VERSION ""

NS_ :

BS_:

BU_: AHLM ASBS CBC DIAGNOST DPDM DTCM ECM EHPS ESC ESL ESM ETM GPF HCP IC IRCM OCM ORC PTS RF_HUB SCCM SGW TBM TCM TPM

BO_ 1002 VehCfg3: 8 CBC
 SG_ VC_ADJ_PDL_PRSNT : 26|1@1+ (1,0) [0|0] ""  RF_HUB,SGW
 SG_ VC_AUTO_HL : 27|1@1+ (1,0) [0|0] ""  RF_HUB,SGW
 SG_ VC_AutoParkPrsnt : 61|1@1+ (1,0) [0|0] ""  RF_HUB,SGW
 SG_ VC_Base_TPM : 57|1@1+ (1,0) [0|0] ""  IC,ORC,RF_HUB,SGW,TPM
 SG_ VC_CMP_DISP : 48|1@1+ (1,0) [0|0] ""  IC,RF_HUB,SGW
 SG_ VC_CMS : 55|1@1+ (1,0) [0|0] ""  ESC,IRCM,ORC,RF_HUB,SGW
 SG_ VC_ChassisType : 32|7@1+ (1,0) [0|126] ""  DTCM,EHPS,ESC,RF_HUB,SGW
 SG_ VC_DSBL_CLK_DISP : 31|1@1+ (1,0) [0|0] ""  RF_HUB,SGW
 SG_ VC_DrAlrPrsnt : 28|1@1+ (1,0) [0|0] ""  RF_HUB,SGW
 SG_ VC_DualFuelSens : 29|1@1+ (1,0) [0|0] ""  IC,RF_HUB,SGW
 SG_ VC_ELV_Prsnt : 15|1@1+ (1,0) [0|0] ""  RF_HUB,SGW
 SG_ VC_ESCL_PRSNT : 50|1@1+ (1,0) [0|0] ""  RF_HUB,SGW
 SG_ VC_FCW : 56|1@1+ (1,0) [0|0] ""  ESC,IRCM,ORC,RF_HUB,SGW
 SG_ VC_FOBIKsafeENBL : 14|1@1+ (1,0) [0|0] ""  RF_HUB,SGW
 SG_ VC_FUEL_CAP : 16|8@1+ (1,36) [36|290] "liters"  IC,RF_HUB,SGW
 SG_ VC_HID_HL : 51|1@1+ (1,0) [0|0] ""  RF_HUB,SGW
 SG_ VC_HVAC_Config : 40|4@1+ (1,0) [0|0] ""  RF_HUB,SGW
 SG_ VC_IntEC_MIRR : 49|1@1+ (1,0) [0|0] ""  RF_HUB,SGW
 SG_ VC_KG_Prsnt : 63|1@1+ (1,0) [0|0] ""  IC,RF_HUB,SGW,TCM
 SG_ VC_Liftgate_Trunk : 53|2@1+ (1,0) [0|0] ""  RF_HUB,SGW
 SG_ VC_PDDL_PRSNT : 59|1@1+ (1,0) [0|0] ""  IC,RF_HUB,SGW,TCM
 SG_ VC_PE_Prsnt : 62|1@1+ (1,0) [0|0] ""  RF_HUB,SGW
 SG_ VC_POLICE : 2|1@1+ (1,0) [0|0] ""  RF_HUB,SGW
 SG_ VC_PWR_LFT_GT : 3|1@1+ (1,0) [0|0] ""  RF_HUB,SGW
 SG_ VC_PWR_LT_SLDR : 5|1@1+ (1,0) [0|0] ""  RF_HUB,SGW
 SG_ VC_PWR_RT_SLDR : 4|1@1+ (1,0) [0|0] ""  RF_HUB,SGW
 SG_ VC_Prem_TPM : 58|1@1+ (1,0) [0|0] ""  IC,ORC,RF_HUB,SGW,TPM
 SG_ VC_RKE_PRSNT : 6|1@1+ (1,0) [0|0] ""  RF_HUB,SGW
 SG_ VC_SPORT_PRSNT : 60|1@1+ (1,0) [0|0] ""  RF_HUB,SGW
 SG_ VC_SRT_PRSNT : 30|1@1+ (1,0) [0|0] ""  RF_HUB,SGW,TPM
 SG_ VC_SecLkPrsnt : 52|1@1+ (1,0) [0|0] ""  RF_HUB,SGW
 SG_ VC_SunShade_Present : 7|1@1+ (1,0) [0|0] ""  RF_HUB,SGW
 SG_ VC_TEMP_DISP : 39|1@1+ (1,0) [0|0] ""  IC,RF_HUB,SGW
 SG_ VC_TcaseTyp : 8|4@1+ (1,0) [0|0] ""  DTCM,ESC,IC,RF_HUB,SGW
 SG_ VC_VEH_BRAND : 44|4@1+ (1,0) [0|0] ""  PTS,RF_HUB,SGW
 SG_ VC_VehCfg3_Stat : 0|2@1+ (1,0) [0|0] ""  DTCM,ECM,EHPS,ESC,ESM,HCP,IC,IRCM,ORC,PTS,RF_HUB,SGW,TCM,TPM
 SG_ VC_WHL_BASE : 12|2@1+ (1,0) [0|0] ""  IC,IRCM,RF_HUB,SGW
 SG_ VC_WIN_EXPR_FEAT : 24|2@1+ (1,0) [0|0] ""  RF_HUB,SGW

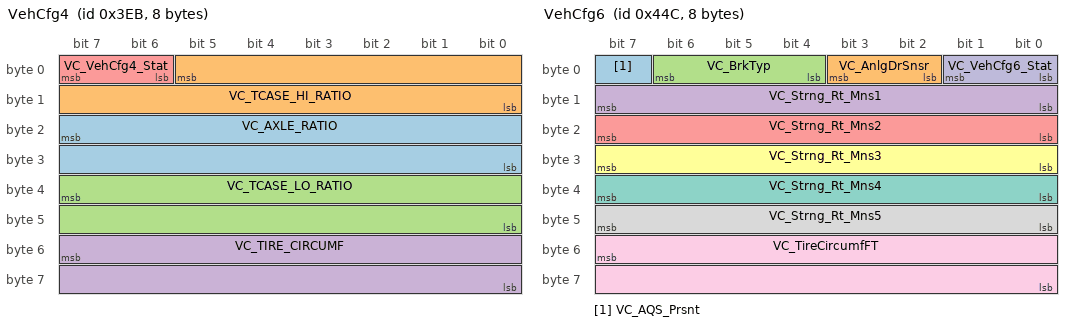
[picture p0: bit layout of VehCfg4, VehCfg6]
BO_ 1003 VehCfg4: 8 CBC
 SG_ VC_AXLE_RATIO : 23|16@0+ (0.001,0) [0|65.534] ""  DTCM,ECM,ESC,HCP,IRCM,RF_HUB,SGW,TCM
 SG_ VC_TCASE_HI_RATIO : 5|14@0+ (0.001,0) [0|16.382] ""  DTCM,ECM,ESC,HCP,RF_HUB,SGW,TCM
 SG_ VC_TCASE_LO_RATIO : 39|16@0+ (0.001,0) [0|65.534] ""  DTCM,ECM,ESC,HCP,RF_HUB,SGW,TCM
 SG_ VC_TIRE_CIRCUMF : 55|16@0+ (1,0) [0|65534] "mm"  DTCM,ECM,EHPS,ESC,HCP,IRCM,ORC,RF_HUB,SGW,TCM
 SG_ VC_VehCfg4_Stat : 6|2@1+ (1,0) [0|0] ""  DTCM,ECM,EHPS,ESC,HCP,IRCM,ORC,PTS,RF_HUB,SGW,TCM

BO_ 1098 VehCfg5: 8 CBC
 SG_ VC_AmbLtgPrsnt : 61|1@1+ (1,0) [0|0] ""  RF_HUB,SGW
 SG_ VC_AmbTempLct : 6|2@1+ (1,0) [0|0] ""  RF_HUB,SGW
 SG_ VC_ChildDisp_Prsnt : 59|1@1+ (1,0) [0|0] ""  RF_HUB,SGW
 SG_ VC_LUCI_PRSNT : 2|1@1+ (1,0) [0|0] ""  RF_HUB,SGW
 SG_ VC_NonReg_TPIS : 4|1@1+ (1,0) [0|0] ""  RF_HUB,SGW
 SG_ VC_OffRoadPg : 60|1@1+ (1,0) [0|0] ""  RF_HUB,SGW
 SG_ VC_PPPA_Prsnt : 62|1@1+ (1,0) [0|0] ""  ECM,ESC,RF_HUB,SGW
 SG_ VC_ParkStopPrsnt : 63|1@1+ (1,0) [0|0] ""  ESC,RF_HUB,SGW
 SG_ VC_RR_DuallyPrsnt : 3|1@1+ (1,0) [0|0] ""  RF_HUB,SGW
 SG_ VC_RearDoorLocks2DCM : 56|1@1+ (1,0) [0|0] ""  RF_HUB,SGW
 SG_ VC_SBR_Prsnt : 58|1@1+ (1,0) [0|0] ""  IC,RF_HUB,SGW
 SG_ VC_SpdLmt_PRSNT : 57|1@1+ (1,0) [0|0] ""  ECM,IC,IRCM,RF_HUB,SCCM,SGW
 SG_ VC_Strng_Rt_0 : 8|8@1+ (0.1,0) [0|25.4] ""  ESC,RF_HUB,SGW
 SG_ VC_Strng_Rt_pls1 : 16|8@1+ (0.1,0) [0|25.4] ""  ESC,RF_HUB,SGW
 SG_ VC_Strng_Rt_pls2 : 24|8@1+ (0.1,0) [0|25.4] ""  ESC,RF_HUB,SGW
 SG_ VC_Strng_Rt_pls3 : 32|8@1+ (0.1,0) [0|25.4] ""  ESC,RF_HUB,SGW
 SG_ VC_Strng_Rt_pls4 : 40|8@1+ (0.1,0) [0|25.4] ""  ESC,RF_HUB,SGW
 SG_ VC_Strng_Rt_pls5 : 48|8@1+ (0.1,0) [0|25.4] ""  ESC,RF_HUB,SGW
 SG_ VC_VehCfg5_Stat : 0|2@1+ (1,0) [0|0] ""  ECM,ESC,IC,ORC,PTS,RF_HUB,SCCM,SGW
 SG_ VC_WTS_Prsnt : 5|1@1+ (1,0) [0|0] ""  RF_HUB,SGW

BO_ 1100 VehCfg6: 8 CBC
 SG_ VC_AQS_Prsnt : 7|1@1+ (1,0) [0|0] ""  RF_HUB,SGW
 SG_ VC_AnlgDrSnsr : 2|2@1+ (1,0) [0|0] ""  ECM,RF_HUB,SGW
 SG_ VC_BrkTyp : 4|3@1+ (1,0) [0|0] ""  RF_HUB,SGW,TCM
 SG_ VC_Strng_Rt_Mns1 : 8|8@1+ (0.1,0) [0|25.4] ""  ESC,RF_HUB,SGW
 SG_ VC_Strng_Rt_Mns2 : 16|8@1+ (0.1,0) [0|25.4] ""  ESC,RF_HUB,SGW
 SG_ VC_Strng_Rt_Mns3 : 24|8@1+ (0.1,0) [0|25.4] ""  ESC,RF_HUB,SGW
 SG_ VC_Strng_Rt_Mns4 : 32|8@1+ (0.1,0) [0|25.4] ""  ESC,RF_HUB,SGW
 SG_ VC_Strng_Rt_Mns5 : 40|8@1+ (0.1,0) [0|25.4] ""  ESC,RF_HUB,SGW
 SG_ VC_TireCircumfFT : 55|16@0+ (1,0) [0|65534] "mm"  ESC,RF_HUB,SGW,TCM
 SG_ VC_VehCfg6_Stat : 0|2@1+ (1,0) [0|0] ""  ECM,ESC,HCP,IC,ORC,RF_HUB,SGW,TCM

BO_ 897 VehCfg7: 8 CBC
 SG_ VC_ABSM : 25|1@1+ (1,0) [0|0] ""  RF_HUB,SGW
 SG_ VC_ACC_Type : 19|2@1+ (1,0) [0|0] ""  ECM,ESC,IC,IRCM,ORC,RF_HUB,SCCM,SGW,TCM
 SG_ VC_ADR_PRSNT : 40|1@1+ (1,0) [0|0] ""  RF_HUB,SGW
 SG_ VC_AGSprsnt : 41|1@1+ (1,0) [0|0] ""  RF_HUB,SGW
 SG_ VC_AS_ERS : 14|2@1+ (1,0) [0|0] ""  RF_HUB,SGW,TCM
 SG_ VC_AxleLockerPrsnt : 26|2@1+ (1,0) [0|0] ""  DTCM,IC,RF_HUB,SGW
 SG_ VC_Brake_Type : 56|4@1+ (1,0) [0|0] ""  RF_HUB,SGW
 SG_ VC_DST_Present : 5|1@1+ (1,0) [0|0] ""  RF_HUB,SGW
 SG_ VC_DampingPrsnt : 22|1@1+ (1,0) [0|0] ""  RF_HUB,SGW
 SG_ VC_FullSpeedRange_FCW : 18|1@1+ (1,0) [0|0] ""  ESC,IC,IRCM,RF_HUB,SGW
 SG_ VC_GlareFree_Prsnt : 48|1@1+ (1,0) [0|0] ""  RF_HUB,SGW
 SG_ VC_Glovebox : 44|1@1+ (1,0) [0|0] ""  RF_HUB,SGW
 SG_ VC_HybridType : 36|3@1+ (1,0) [0|0] ""  AHLM,DTCM,ECM,EHPS,ESC,HCP,IC,IRCM,ORC,PTS,RF_HUB,SGW,TCM
 SG_ VC_LDW : 2|1@1+ (1,0) [0|0] ""  ORC,RF_HUB,SGW
 SG_ VC_MOC_Type : 45|2@1+ (1,0) [0|0] ""  RF_HUB,SGW
 SG_ VC_PBTyp : 29|3@1+ (1,0) [0|0] ""  IRCM,ORC,RF_HUB,SGW
 SG_ VC_PTCPrsnt : 43|1@1+ (1,0) [0|0] ""  ECM,RF_HUB,SGW
 SG_ VC_PdlsMdPrsnt : 4|1@1+ (1,0) [0|0] ""  RF_HUB,SGW,TCM
 SG_ VC_RedKey : 24|1@1+ (1,0) [0|0] ""  RF_HUB,SGW
 SG_ VC_STP_PRSNT : 6|1@1+ (1,0) [0|0] ""  RF_HUB,SGW
 SG_ VC_SUNR_Prsnt : 47|1@1+ (1,0) [0|0] ""  RF_HUB,SGW
 SG_ VC_SVC_Prsnt : 17|1@1+ (1,0) [0|0] ""  RF_HUB,SGW
 SG_ VC_SmartAlternator : 35|1@1+ (1,0) [0|0] ""  ECM,RF_HUB,SGW
 SG_ VC_SuspPrsnt : 21|1@1+ (1,0) [0|0] ""  RF_HUB,SGW
 SG_ VC_Suspension_Type : 60|4@1+ (1,0) [0|0] ""  RF_HUB,SGW
 SG_ VC_TPMS_Configuration : 32|3@1+ (1,0) [0|0] ""  IC,RF_HUB,SGW,TPM
 SG_ VC_TSBM_Prsnt : 39|1@1+ (1,0) [0|0] ""  RF_HUB,SGW
 SG_ VC_TeenKey : 16|1@1+ (1,0) [0|0] ""  RF_HUB,SGW
 SG_ VC_Temp_Display_Resolution : 42|1@1+ (1,0) [0|0] ""  RF_HUB,SGW
 SG_ VC_TransType : 8|6@1+ (1,0) [0|0] ""  DTCM,ESC,IC,RF_HUB,SGW
 SG_ VC_Trans_Equipped : 28|1@1+ (1,0) [0|0] ""  DTCM,ESC,IC,IRCM,ORC,PTS,RF_HUB,SGW,TPM
 SG_ VC_Trans_N_Hold_Prsnt : 23|1@1+ (1,0) [0|0] ""  RF_HUB,SGW
 SG_ VC_TrnsDrvMdPrsnt : 3|1@1+ (1,0) [0|0] ""  RF_HUB,SGW,TCM
 SG_ VC_VehCfg7_Stat : 0|2@1+ (1,0) [0|0] ""  DTCM,ECM,EHPS,ESC,HCP,IC,IRCM,ORC,PTS,RF_HUB,SCCM,SGW,TCM,TPM
 SG_ VC_eShifter_Prsnt : 7|1@1+ (1,0) [0|0] ""  RF_HUB,SGW

BO_ 906 VehCfg8: 8 CBC
 SG_ VC_ARC_PRSNT : 5|1@1+ (1,0) [0|0] ""  RF_HUB,SGW
 SG_ VC_AVAC_PRSNT : 21|1@1+ (1,0) [0|0] ""  RF_HUB,SGW
 SG_ VC_BEAM_SHAPING_PRSNT : 19|1@1+ (1,0) [0|0] ""  RF_HUB,SGW
 SG_ VC_CHILLER_PRSNT : 6|1@1+ (1,0) [0|0] ""  RF_HUB,SGW
 SG_ VC_DBL_PRSNT : 20|1@1+ (1,0) [0|0] ""  RF_HUB,SGW
 SG_ VC_FADPrsnt : 38|1@1+ (1,0) [0|0] ""  DTCM,RF_HUB,SGW
 SG_ VC_HighOctane_PRSNT : 7|1@1+ (1,0) [0|0] ""  RF_HUB,SGW
 SG_ VC_INDIA_SPEED_WARNING : 41|1@1+ (1,0) [0|0] ""  IC,RF_HUB,SGW
 SG_ VC_Increasing_Speed_Constant : 13|3@1+ (1,0) [0|0] ""  ECM,IC,IRCM,RF_HUB,SGW
 SG_ VC_LineLock_PRSNT : 4|1@1+ (1,0) [0|0] ""  RF_HUB,SGW
 SG_ VC_OFFRoadModePrsnt : 22|1@1+ (1,0) [0|0] ""  DTCM,ECM,ESC,IC,IRCM,RF_HUB,SGW,TCM
 SG_ VC_OFFroad_Camera : 23|1@1+ (1,0) [0|0] ""  RF_HUB,SGW
 SG_ VC_OvertakingBan : 16|1@1+ (1,0) [0|0] ""  RF_HUB,SGW
 SG_ VC_PEB_PRSNT : 62|1@1+ (1,0) [0|0] ""  RF_HUB,SGW
 SG_ VC_PPPAHardBtn : 24|1@1+ (1,0) [0|0] ""  RF_HUB,SGW
 SG_ VC_Power_Outlet_Type : 35|2@1+ (1,0) [0|0] ""  RF_HUB,SGW
 SG_ VC_SBL_FBL_CORNERING_PRSNT : 17|2@1+ (1,0) [0|0] ""  RF_HUB,SGW
 SG_ VC_STFA_Prsnt : 53|1@1+ (1,0) [0|0] ""  RF_HUB,SGW,TPM
 SG_ VC_Speedometer_Tolerance : 9|4@1+ (1,0) [0|0] ""  ECM,IC,IRCM,RF_HUB,SGW
 SG_ VC_Steering_Cfactor : 2|2@1+ (1,0) [0|0] ""  IRCM,RF_HUB,SGW
 SG_ VC_TACHO_TYPE : 54|2@1+ (1,0) [0|0] ""  ECM,IC,RF_HUB,SGW
 SG_ VC_TIPL_LOT : 39|1@1+ (1,0) [0|0] ""  RF_HUB
 SG_ VC_TLC_PRSNT : 37|1@1+ (1,0) [0|0] ""  RF_HUB,SGW
 SG_ VC_Trans_Brake_PRSNT : 8|1@1+ (1,0) [0|0] ""  RF_HUB,SGW
 SG_ VC_VP_Level : 43|4@1+ (1,0) [0|0] ""  HCP,RF_HUB,SGW
 SG_ VC_VehCfg8_Stat : 0|2@1+ (1,0) [0|0] ""  DTCM,ECM,IC,IRCM,RF_HUB,SGW,TCM
 SG_ VC_WHL_BASE_LENGTH : 56|4@1+ (1,0) [0|0] ""  IRCM,RF_HUB,SGW

BO_ 1004 VehCfgBu1: 8 RF_HUB
 SG_ VC_BU_AUTO_HB : 27|1@1+ (1,0) [0|0] ""  CBC,SGW
 SG_ VC_BU_BODY_STYLE : 28|4@1+ (1,0) [0|0] ""  CBC,SGW
 SG_ VC_BU_CHMCM_Prsnt : 61|1@1+ (1,0) [0|0] ""  CBC,SGW
 SG_ VC_BU_COUNTRY : 16|5@1+ (1,0) [0|0] ""  CBC,SGW
 SG_ VC_BU_EmodePrsnt : 26|1@1+ (1,0) [0|0] ""  CBC,SGW
 SG_ VC_BU_HDC_Prsnt : 62|1@1+ (1,0) [0|0] ""  CBC,SGW
 SG_ VC_BU_HdRstPrsnt : 56|1@1+ (1,0) [0|0] ""  CBC,SGW
 SG_ VC_BU_LHD_RHD : 21|2@1+ (1,0) [0|0] ""  CBC,SGW
 SG_ VC_BU_MAX_VEH_SPD : 32|8@1+ (2,0) [0|506] "kph"  CBC,SGW
 SG_ VC_BU_MODEL_YEAR : 2|6@1+ (1,2000) [2000|2062] "model-year"  CBC,SGW
 SG_ VC_BU_PP_Prsnt : 47|1@1+ (1,0) [0|0] ""  CBC,SGW
 SG_ VC_BU_PTS_Config : 58|2@1+ (1,0) [0|0] ""  CBC,SGW
 SG_ VC_BU_PTS_DispTyp : 44|3@1+ (1,0) [0|0] ""  CBC,SGW
 SG_ VC_BU_RVCM_Prsnt : 60|1@1+ (1,0) [0|0] ""  CBC,SGW
 SG_ VC_BU_RemStPrsnt : 23|1@1+ (1,0) [0|0] ""  CBC,SGW
 SG_ VC_BU_SCR_Prsnt : 57|1@1+ (1,0) [0|0] ""  CBC,SGW
 SG_ VC_BU_SSC_Prsnt : 63|1@1+ (1,0) [0|0] ""  CBC,SGW
 SG_ VC_BU_ShftrTyp : 40|4@1+ (1,0) [0|0] ""  CBC,SGW
 SG_ VC_BU_SpecialPKG : 48|8@1+ (1,0) [1|254] ""  CBC,SGW
 SG_ VC_BU_VEH_LINE : 8|8@1+ (1,0) [0|0] ""  CBC,SGW
 SG_ VC_BU_VehCfg1_Stat : 0|2@1+ (1,0) [0|0] ""  CBC,SGW
 SG_ VC_BU_XWD : 24|2@1+ (1,0) [0|0] ""  CBC,SGW

BO_ 1005 VehCfgBu2: 8 RF_HUB
 SG_ VC_BU_AC_Prsnt : 11|1@1+ (1,0) [0|0] ""  CBC,SGW
 SG_ VC_BU_CRUISE_PRSNT : 12|1@1+ (1,0) [0|0] ""  CBC,SGW
 SG_ VC_BU_DRVMD_Prsnt : 25|1@1+ (1,0) [0|0] ""  CBC,SGW
 SG_ VC_BU_ECO_Indicator : 24|1@1+ (1,0) [0|0] ""  CBC,SGW
 SG_ VC_BU_ESCDrvMd_Prsnt : 27|1@1+ (1,0) [0|0] ""  CBC,SGW
 SG_ VC_BU_EngPowerDrvMd_Prsnt : 28|1@1+ (1,0) [0|0] ""  CBC,SGW
 SG_ VC_BU_FG_PRSNT : 13|1@1+ (1,0) [0|0] ""  CBC,SGW
 SG_ VC_BU_FULL_SPARE : 14|1@1+ (1,0) [0|0] ""  CBC,SGW
 SG_ VC_BU_LgtLdPressFtTr : 56|8@1+ (1,0) [0|126] "psi"  CBC,SGW
 SG_ VC_BU_LgtLdPressRrTr : 48|8@1+ (1,0) [0|126] "psi"  CBC,SGW
 SG_ VC_BU_MaseratiMd : 6|2@1+ (1,0) [0|0] ""  CBC,SGW
 SG_ VC_BU_MaxLdPressFtTr : 40|8@1+ (1,0) [0|126] "psi"  CBC,SGW
 SG_ VC_BU_MaxLdPressRrTr : 32|8@1+ (1,0) [0|126] "psi"  CBC,SGW
 SG_ VC_BU_MemoryDRVMD_Prsnt : 26|1@1+ (1,0) [0|0] ""  CBC,SGW
 SG_ VC_BU_OffRoad : 15|1@1+ (1,0) [0|0] ""  CBC,SGW
 SG_ VC_BU_PADS_Prsnt : 8|1@1+ (1,0) [0|0] ""  CBC,SGW
 SG_ VC_BU_PwrIvtrTyp : 2|2@1+ (1,0) [0|0] ""  CBC,SGW
 SG_ VC_BU_RainSnsPrsnt : 9|1@1+ (1,0) [0|0] ""  CBC,SGW
 SG_ VC_BU_RunFlatTirePrsnt : 5|1@1+ (1,0) [0|0] ""  CBC,SGW
 SG_ VC_BU_SKIM_PRSNT : 10|1@1+ (1,0) [0|0] ""  CBC,SGW
 SG_ VC_BU_SecPrkPrsnt : 29|1@1+ (1,0) [0|0] ""  CBC,SGW
 SG_ VC_BU_ShftInd_Prsnt : 30|2@1+ (1,0) [0|0] ""  CBC,SGW
 SG_ VC_BU_SpecialPKG_IC : 16|8@1+ (1,0) [0|0] ""  CBC,SGW
 SG_ VC_BU_ThatchamPrsnt : 4|1@1+ (1,0) [0|0] ""  CBC,SGW
 SG_ VC_BU_VehCfg2_Stat : 0|2@1+ (1,0) [0|0] ""  CBC,SGW

BO_ 1006 VehCfgBu3: 8 RF_HUB
 SG_ VC_BU_ADJ_PDL_PRSNT : 26|1@1+ (1,0) [0|0] ""  CBC,SGW
 SG_ VC_BU_AUTO_HL : 27|1@1+ (1,0) [0|0] ""  CBC,SGW
 SG_ VC_BU_AutoParkPrsnt : 61|1@1+ (1,0) [0|0] ""  CBC,SGW
 SG_ VC_BU_Base_TPM : 57|1@1+ (1,0) [0|0] ""  CBC,SGW
 SG_ VC_BU_CMP_DISP : 48|1@1+ (1,0) [0|0] ""  CBC,SGW
 SG_ VC_BU_CMS : 55|1@1+ (1,0) [0|0] ""  CBC,SGW
 SG_ VC_BU_ChassisType : 32|7@1+ (1,0) [0|126] ""  CBC,SGW
 SG_ VC_BU_DSBL_CLK_DISP : 31|1@1+ (1,0) [0|0] ""  CBC,SGW
 SG_ VC_BU_DrAlrPrsnt : 28|1@1+ (1,0) [0|0] ""  CBC,SGW
 SG_ VC_BU_DualFuelSens : 29|1@1+ (1,0) [0|0] ""  CBC,SGW
 SG_ VC_BU_ELV_PRSNT : 15|1@1+ (1,0) [0|0] ""  CBC,SGW
 SG_ VC_BU_ESCL_Prsnt : 50|1@1+ (1,0) [0|0] ""  CBC,SGW
 SG_ VC_BU_FCW : 56|1@1+ (1,0) [0|0] ""  CBC,SGW
 SG_ VC_BU_FOBIKsafeENBL : 14|1@1+ (1,0) [0|0] ""  CBC,SGW
 SG_ VC_BU_FUEL_CAP : 16|8@1+ (1,36) [36|290] "liters"  CBC,SGW
 SG_ VC_BU_HID_HL : 51|1@1+ (1,0) [0|0] ""  CBC,SGW
 SG_ VC_BU_HVAC_Config : 40|4@1+ (1,0) [0|0] ""  CBC,SGW
 SG_ VC_BU_IntEC_MIRR : 49|1@1+ (1,0) [0|0] ""  CBC,SGW
 SG_ VC_BU_KG_Prsnt : 63|1@1+ (1,0) [0|0] ""  CBC,SGW
 SG_ VC_BU_Liftgate_Trunk : 53|2@1+ (1,0) [0|0] ""  CBC,SGW
 SG_ VC_BU_PDDL_PRSNT : 59|1@1+ (1,0) [0|0] ""  CBC,SGW
 SG_ VC_BU_PE_Prsnt : 62|1@1+ (1,0) [0|0] ""  CBC,SGW
 SG_ VC_BU_POLICE : 2|1@1+ (1,0) [0|0] ""  CBC,SGW
 SG_ VC_BU_PWR_LFT_GT : 3|1@1+ (1,0) [0|0] ""  CBC,SGW
 SG_ VC_BU_PWR_LT_SLDR : 5|1@1+ (1,0) [0|0] ""  CBC,SGW
 SG_ VC_BU_PWR_RT_SLDR : 4|1@1+ (1,0) [0|0] ""  CBC,SGW
 SG_ VC_BU_Prem_TPM : 58|1@1+ (1,0) [0|0] ""  CBC,SGW
 SG_ VC_BU_RKE_PRSNT : 6|1@1+ (1,0) [0|0] ""  CBC,SGW
 SG_ VC_BU_SPORT_PRSNT : 60|1@1+ (1,0) [0|0] ""  CBC,SGW
 SG_ VC_BU_SRT_PRSNT : 30|1@1+ (1,0) [0|0] ""  CBC,SGW
 SG_ VC_BU_SecLkPrsnt : 52|1@1+ (1,0) [0|0] ""  CBC,SGW
 SG_ VC_BU_SunShade_Present : 7|1@1+ (1,0) [0|0] ""  CBC,SGW
 SG_ VC_BU_TEMP_DISP : 39|1@1+ (1,0) [0|0] ""  CBC,SGW
 SG_ VC_BU_TcaseTyp : 8|4@1+ (1,0) [0|0] ""  CBC,SGW
 SG_ VC_BU_VEH_BRAND : 44|4@1+ (1,0) [0|0] ""  CBC,SGW
 SG_ VC_BU_VehCfg3_Stat : 0|2@1+ (1,0) [0|0] ""  CBC,SGW
 SG_ VC_BU_WHL_BASE : 12|2@1+ (1,0) [0|0] ""  CBC,SGW
 SG_ VC_BU_WIN_EXPR_FEAT : 24|2@1+ (1,0) [0|0] ""  CBC,SGW

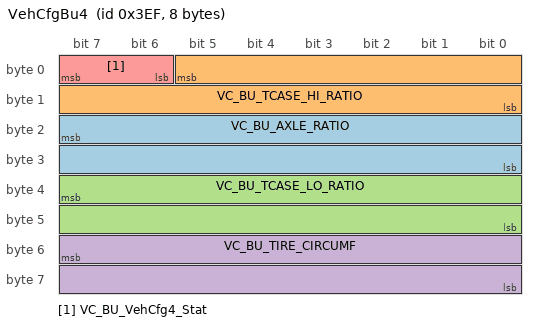
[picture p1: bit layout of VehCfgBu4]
BO_ 1007 VehCfgBu4: 8 RF_HUB
 SG_ VC_BU_AXLE_RATIO : 23|16@0+ (0.001,0) [0|65.534] ""  CBC,SGW
 SG_ VC_BU_TCASE_HI_RATIO : 5|14@0+ (0.001,0) [0|16.382] ""  CBC,SGW
 SG_ VC_BU_TCASE_LO_RATIO : 39|16@0+ (0.001,0) [0|65.534] ""  CBC,SGW
 SG_ VC_BU_TIRE_CIRCUMF : 55|16@0+ (1,0) [0|65534] "mm"  CBC,SGW
 SG_ VC_BU_VehCfg4_Stat : 6|2@1+ (1,0) [0|0] ""  CBC,SGW

CM_ SG_ 1002 VC_ADJ_PDL_PRSNT "Adjustable pedal system present (non-memory); present = [1]";
CM_ SG_ 1002 VC_AUTO_HL "Auto headlamp feature present; present = [1]";
CM_ SG_ 1002 VC_AutoParkPrsnt "Automatic transmission parking feature is present; present = [1]";
CM_ SG_ 1002 VC_Base_TPM "Base TPM system present; present = [1]";
CM_ SG_ 1002 VC_CMP_DISP "Display compass heading present; present = [1]";
CM_ SG_ 1002 VC_CMS "Collision Mitigation System present; present = [1]";
CM_ SG_ 1002 VC_ChassisType "Chassis type (including suspension, brakes, and tires)";
CM_ SG_ 1002 VC_DSBL_CLK_DISP "Disable display of radio clock; 1 = clock display disabled";
CM_ SG_ 1002 VC_DrAlrPrsnt "Door alert feature present; present = [1]";
CM_ SG_ 1002 VC_DualFuelSens "Vehicle equipped with two fuel sending units; present = [1]";
CM_ SG_ 1002 VC_ELV_Prsnt "ELV system present; enabled=[1], disabled=[0]";
CM_ SG_ 1002 VC_ESCL_PRSNT "ESCL system present; enabled=[1], disabled=[0]";
CM_ SG_ 1002 VC_FCW "Forward Collision Warning present; present = [1]";
CM_ SG_ 1002 VC_FOBIKsafeENBL "Feature FOBIK safe is enabled; present = [1]";
CM_ SG_ 1002 VC_FUEL_CAP "Fuel capacity";
CM_ SG_ 1002 VC_HID_HL "High intensity discharge head lamps; present = [1]";
CM_ SG_ 1002 VC_HVAC_Config "HVAC Configuration";
CM_ SG_ 1002 VC_IntEC_MIRR "Vehicle is equipped with an interior EC mirror; present = [1]";
CM_ SG_ 1002 VC_KG_Prsnt "Feature keyless go is present; present = [1]";
CM_ SG_ 1002 VC_Liftgate_Trunk "Liftgate or trunk";
CM_ SG_ 1002 VC_PDDL_PRSNT "Paddle shift feature is present; present = [1]";
CM_ SG_ 1002 VC_PE_Prsnt "Feature passive entry is present; present = [1]";
CM_ SG_ 1002 VC_POLICE "Police lighting feature; present = [1]";
CM_ SG_ 1002 VC_PWR_LFT_GT "Power lift gate present; present = [1]";
CM_ SG_ 1002 VC_PWR_LT_SLDR "Power left sliding door present; present = [1]";
CM_ SG_ 1002 VC_PWR_RT_SLDR "Power right sliding door present; present = [1]";
CM_ SG_ 1002 VC_Prem_TPM "Premium TPM system present; present = [1]";
CM_ SG_ 1002 VC_RKE_PRSNT "RKE system present; present = [1]";
CM_ SG_ 1002 VC_SPORT_PRSNT "Sport mode is present; present = [1]";
CM_ SG_ 1002 VC_SRT_PRSNT "Vehicle is an SRT; present = [1]";
CM_ SG_ 1002 VC_SecLkPrsnt "Secondary Lock Present; [1] = True";
CM_ SG_ 1002 VC_SunShade_Present "Vehicle equipped w/SunShade (1=present)";
CM_ SG_ 1002 VC_TEMP_DISP "Display outside temperature present; present = [1]";
CM_ SG_ 1002 VC_TcaseTyp "Tcase type";
CM_ SG_ 1002 VC_VEH_BRAND "Vehicle brand type";
CM_ SG_ 1002 VC_VehCfg3_Stat "Configuration messages status 3";
CM_ SG_ 1002 VC_WHL_BASE "Wheel base";
CM_ SG_ 1002 VC_WIN_EXPR_FEAT "Window express feature configuration";
CM_ SG_ 1003 VC_AXLE_RATIO "Axle ratio";
CM_ SG_ 1003 VC_TCASE_HI_RATIO "Transfer case high ratio";
CM_ SG_ 1003 VC_TCASE_LO_RATIO "Transfer case low range reduction ratio";
CM_ SG_ 1003 VC_TIRE_CIRCUMF "Dynamic tire circumference (all or rear)";
CM_ SG_ 1003 VC_VehCfg4_Stat "Configuration messages status 4";
CM_ SG_ 1098 VC_AmbLtgPrsnt "Ambient lighting feature is present; True = [1]";
CM_ SG_ 1098 VC_AmbTempLct "Ambient temperature sensor location";
CM_ SG_ 1098 VC_ChildDisp_Prsnt "Child display feature is present; True = 1";
CM_ SG_ 1098 VC_LUCI_PRSNT "Luci feature present; present = [1]";
CM_ SG_ 1098 VC_NonReg_TPIS "Non-regulated tire pressure indicator system; True = 1";
CM_ SG_ 1098 VC_OffRoadPg "Off road pages present; True = [1]";
CM_ SG_ 1098 VC_PPPA_Prsnt "Semi automatic parking system present; present = [1]";
CM_ SG_ 1098 VC_ParkStopPrsnt "Park with stop is present; True = 1";
CM_ SG_ 1098 VC_RR_DuallyPrsnt "Vehicle is equipped with rear duals; present = [1]";
CM_ SG_ 1098 VC_RearDoorLocks2DCM "Rear door lock switch present; present = [1]";
CM_ SG_ 1098 VC_SBR_Prsnt "Seat belt reminder module is present; True = 1";
CM_ SG_ 1098 VC_SpdLmt_PRSNT "Speed limiter is present; present = [1]";
CM_ SG_ 1098 VC_Strng_Rt_0 "Steering Ratio at zero";
CM_ SG_ 1098 VC_Strng_Rt_pls1 "Steering Ratio at positve angle 1";
CM_ SG_ 1098 VC_Strng_Rt_pls2 "Steering Ratio at positve angle 2";
CM_ SG_ 1098 VC_Strng_Rt_pls3 "Steering Ratio at positve angle 3";
CM_ SG_ 1098 VC_Strng_Rt_pls4 "Steering Ratio at positve angle 4";
CM_ SG_ 1098 VC_Strng_Rt_pls5 "Steering Ratio at positve angle 5";
CM_ SG_ 1098 VC_VehCfg5_Stat "Configuration messages status 5";
CM_ SG_ 1098 VC_WTS_Prsnt "Wait to start feature is present; present = [1]";
CM_ SG_ 1100 VC_AQS_Prsnt "Air quality sensor present; present = [1]";
CM_ SG_ 1100 VC_AnlgDrSnsr "Analog door sensor configuration";
CM_ SG_ 1100 VC_BrkTyp "Brake type configuration (M156/7)";
CM_ SG_ 1100 VC_Strng_Rt_Mns1 "Steering Ratio at negative angle 1";
CM_ SG_ 1100 VC_Strng_Rt_Mns2 "Steering Ratio at negative angle 2";
CM_ SG_ 1100 VC_Strng_Rt_Mns3 "Steering Ratio at negative angle 3";
CM_ SG_ 1100 VC_Strng_Rt_Mns4 "Steering Ratio at negative angle 4";
CM_ SG_ 1100 VC_Strng_Rt_Mns5 "Steering Ratio at negative angle 5";
CM_ SG_ 1100 VC_TireCircumfFT "Dynamic tire circumference - front only";
CM_ SG_ 1100 VC_VehCfg6_Stat "Configuration messages status 6";
CM_ SG_ 897 VC_ABSM "Active Blind Spot present; present = [1]";
CM_ SG_ 897 VC_ACC_Type "Type of adaptive cruise control (ACC) system present";
CM_ SG_ 897 VC_ADR_PRSNT "ADR feature present; True = [1]";
CM_ SG_ 897 VC_AGSprsnt "AGS Present/Absent;  Present = 1";
CM_ SG_ 897 VC_AS_ERS "Shift feature autostick / electronic range select status";
CM_ SG_ 897 VC_AxleLockerPrsnt "Axle locker configuration";
CM_ SG_ 897 VC_Brake_Type "Brake type";
CM_ SG_ 897 VC_DST_Present "Dynamic steering torque present; True = [1]";
CM_ SG_ 897 VC_DampingPrsnt "NetCfg_ASCM contains active damping; present = [1]";
CM_ SG_ 897 VC_FullSpeedRange_FCW "Full speed range forward collision warning plus system present; Present = 1";
CM_ SG_ 897 VC_GlareFree_Prsnt "Glare Free Present";
CM_ SG_ 897 VC_Glovebox "Glovebox control; Present = 1";
CM_ SG_ 897 VC_HybridType "Identify the kind of hybrid vehicle";
CM_ SG_ 897 VC_LDW "Lane Departure Warning present; present = [1]";
CM_ SG_ 897 VC_MOC_Type "Motor on caliper type";
CM_ SG_ 897 VC_PBTyp "Park brake type";
CM_ SG_ 897 VC_PTCPrsnt "PTC Present/Absent;  Present = 1";
CM_ SG_ 897 VC_PdlsMdPrsnt "Paddles lock-out feature; present = [1]";
CM_ SG_ 897 VC_RedKey "RedKey feature is present; Present = [1]";
CM_ SG_ 897 VC_STP_PRSNT "Super trac pack present; True = [1]";
CM_ SG_ 897 VC_SUNR_Prsnt "Sunroof is present; True = 1";
CM_ SG_ 897 VC_SVC_Prsnt "Surround view camera; present = [1]";
CM_ SG_ 897 VC_SmartAlternator "Smart alternator is present; True = [1]";
CM_ SG_ 897 VC_SuspPrsnt "NetCfg_ASCM contains suspension; present = [1]";
CM_ SG_ 897 VC_Suspension_Type "Suspension type";
CM_ SG_ 897 VC_TPMS_Configuration "TPMS configuration";
CM_ SG_ 897 VC_TSBM_Prsnt "TSBM LIN slave is present; True = [1]";
CM_ SG_ 897 VC_TeenKey "TeenKey feature is present; Present = [1]";
CM_ SG_ 897 VC_Temp_Display_Resolution "Toggle between 0.5degC and 1degC temperature display";
CM_ SG_ 897 VC_TransType "Automatic transmission type";
CM_ SG_ 897 VC_Trans_Equipped "Transmission equipped: 0 = Automatic & 1 = Manual";
CM_ SG_ 897 VC_Trans_N_Hold_Prsnt "Transmission neutral hold feature; present = [1]";
CM_ SG_ 897 VC_TrnsDrvMdPrsnt "Transmission drive mode feature; present = [1]";
CM_ SG_ 897 VC_VehCfg7_Stat "Configuration messages status 7";
CM_ SG_ 897 VC_eShifter_Prsnt "e-shifter present; present = [1]";
CM_ SG_ 906 VC_ARC_PRSNT "After Run Cooling (Race Cool Down) feature present; True = [1]";
CM_ SG_ 906 VC_AVAC_PRSNT "Present = 1";
CM_ SG_ 906 VC_BEAM_SHAPING_PRSNT "Present = 1";
CM_ SG_ 906 VC_CHILLER_PRSNT "Chiller present; True = [1]";
CM_ SG_ 906 VC_DBL_PRSNT "Present = 1";
CM_ SG_ 906 VC_FADPrsnt "Present = 1";
CM_ SG_ 906 VC_HighOctane_PRSNT "High Octane feature present; True = [1]";
CM_ SG_ 906 VC_INDIA_SPEED_WARNING "INDIA EQUIPPED SPEED WARNING Feature";
CM_ SG_ 906 VC_Increasing_Speed_Constant "Increasing Speed Constant (Offset for Speedometer Biasing)";
CM_ SG_ 906 VC_LineLock_PRSNT "Line Lock feature present; True = [1]";
CM_ SG_ 906 VC_OFFRoadModePrsnt "OFF ROAD MODE Present, Present = 1";
CM_ SG_ 906 VC_OFFroad_Camera "OFF Road Camera Present, Present = 1";
CM_ SG_ 906 VC_OvertakingBan "Overtaking Ban present; present = [1]";
CM_ SG_ 906 VC_PEB_PRSNT "Vehicle config to learn the presence of PEB";
CM_ SG_ 906 VC_PPPAHardBtn "PPPA Hard button present, Present = 1";
CM_ SG_ 906 VC_Power_Outlet_Type "Request to IC to determine the cargo power outlet indication display version";
CM_ SG_ 906 VC_SBL_FBL_CORNERING_PRSNT "Configuration messages status 8";
CM_ SG_ 906 VC_STFA_Prsnt "Selectable Tire Fill Alert Present; True = [1]";
CM_ SG_ 906 VC_Speedometer_Tolerance "Speedometer Tolerance Percentage (Gain for Speedometer Biasing)";
CM_ SG_ 906 VC_Steering_Cfactor "Steering Cfactor feature";
CM_ SG_ 906 VC_TACHO_TYPE "CBC VC Config of Tachometer Type";
CM_ SG_ 906 VC_TIPL_LOT "Traffic in Parallel and Lock on Target (1=present)";
CM_ SG_ 906 VC_TLC_PRSNT "Trailer Light Check Feature Present;  present = [1]";
CM_ SG_ 906 VC_Trans_Brake_PRSNT "Transmission Brake feature present; True = [1]";
CM_ SG_ 906 VC_VP_Level "Radio Type Identifier";
CM_ SG_ 906 VC_VehCfg8_Stat "Configuration messages status 8";
CM_ SG_ 906 VC_WHL_BASE_LENGTH "Wheel Base Length";
CM_ SG_ 1004 VC_BU_AUTO_HB "Backup for Auto Highbeam feature present; present = [1]";
CM_ SG_ 1004 VC_BU_BODY_STYLE "Backup for Body style";
CM_ SG_ 1004 VC_BU_CHMCM_Prsnt "Backup for CHMSL camera (1=present)";
CM_ SG_ 1004 VC_BU_COUNTRY "Backup for Country Code";
CM_ SG_ 1004 VC_BU_EmodePrsnt "Backup for E-Mode feature present; True = [1]";
CM_ SG_ 1004 VC_BU_HDC_Prsnt "Backup for Hill descent feature is present; present = [1]";
CM_ SG_ 1004 VC_BU_HdRstPrsnt "Backup for headrest present; present = [1]";
CM_ SG_ 1004 VC_BU_LHD_RHD "Backup for Left/right hand drive";
CM_ SG_ 1004 VC_BU_MAX_VEH_SPD "Backup for Maximum vehicle speed";
CM_ SG_ 1004 VC_BU_MODEL_YEAR "Backup for Model year";
CM_ SG_ 1004 VC_BU_PP_Prsnt "Backup for Performance Pages Present (1=present)";
CM_ SG_ 1004 VC_BU_PTS_Config "Backup for Parktronics system configuration";
CM_ SG_ 1004 VC_BU_PTS_DispTyp "PTS display type and location";
CM_ SG_ 1004 VC_BU_RVCM_Prsnt "Backup for rear view camera (1=present)";
CM_ SG_ 1004 VC_BU_RemStPrsnt "Backup for Remote start present; present = [1]";
CM_ SG_ 1004 VC_BU_SCR_Prsnt "Backup for Urea/SCR system present; present = [1]";
CM_ SG_ 1004 VC_BU_SSC_Prsnt "Backup for Select speed control feature is present; present = [1]";
CM_ SG_ 1004 VC_BU_ShftrTyp "Shifter type";
CM_ SG_ 1004 VC_BU_SpecialPKG "Special sales code package";
CM_ SG_ 1004 VC_BU_VEH_LINE "Backup for Vehicle line";
CM_ SG_ 1004 VC_BU_VehCfg1_Stat "Backup for Configuration messages status 1";
CM_ SG_ 1004 VC_BU_XWD "Backup for Drive configuration";
CM_ SG_ 1005 VC_BU_AC_Prsnt "Backup for Vehicle is equipped with air conditioning; present = [1]";
CM_ SG_ 1005 VC_BU_CRUISE_PRSNT "Backup for Cruise feature is present; present = [1]";
CM_ SG_ 1005 VC_BU_DRVMD_Prsnt "Backup for drive mode feature configuration (1 = Present)";
CM_ SG_ 1005 VC_BU_ECO_Indicator "Backup for ECO Indicator present on vehicle; True = [1]";
CM_ SG_ 1005 VC_BU_ESCDrvMd_Prsnt "Backup for ESC drive mode sub-feature configuration (1 = Present)";
CM_ SG_ 1005 VC_BU_EngPowerDrvMd_Prsnt "Backup for ECM drive mode sub-feature configuration (1 = Present)";
CM_ SG_ 1005 VC_BU_FG_PRSNT "Backup for Flipper glass present; present = [1]";
CM_ SG_ 1005 VC_BU_FULL_SPARE "Backup for Full size spare; present = [1]";
CM_ SG_ 1005 VC_BU_LgtLdPressFtTr "Backup for Light Load Inflation Pressure Front Tire";
CM_ SG_ 1005 VC_BU_LgtLdPressRrTr "Backup for Light Load Inflation Pressure Rear Tire";
CM_ SG_ 1005 VC_BU_MaseratiMd "Backup for Maserati vehicle mode";
CM_ SG_ 1005 VC_BU_MaxLdPressFtTr "Backup for Max Load Inflation Pressure Front Tire";
CM_ SG_ 1005 VC_BU_MaxLdPressRrTr "Backup for Max Load Inflation Pressure Rear Tire";
CM_ SG_ 1005 VC_BU_MemoryDRVMD_Prsnt "Backup for memory drive mode sub-feature configuration (1 = Present)";
CM_ SG_ 1005 VC_BU_OffRoad "Backup for Off road capable; present = [1]";
CM_ SG_ 1005 VC_BU_PADS_Prsnt "Backup for Pass. airbag disable switch present; present = [1]";
CM_ SG_ 1005 VC_BU_PwrIvtrTyp "Backup for power inverter type";
CM_ SG_ 1005 VC_BU_RainSnsPrsnt "Backup for Rain sensor present; present = [1]";
CM_ SG_ 1005 VC_BU_RunFlatTirePrsnt "Backup for run flat tires present; present = [1]";
CM_ SG_ 1005 VC_BU_SKIM_PRSNT "Backup for SKIM system present; present = [1]";
CM_ SG_ 1005 VC_BU_SecPrkPrsnt "Backup for secure park feature present; present = [1]";
CM_ SG_ 1005 VC_BU_ShftInd_Prsnt "Backup for configuration for performance & gear shift indication";
CM_ SG_ 1005 VC_BU_SpecialPKG_IC "Special sales code package";
CM_ SG_ 1005 VC_BU_ThatchamPrsnt "Backup for thatcham present; present = [1]";
CM_ SG_ 1005 VC_BU_VehCfg2_Stat "Backup for Configuration messages status 2";
CM_ SG_ 1006 VC_BU_ADJ_PDL_PRSNT "Backup for Adjustable pedal system present (non-memory); present = [1]";
CM_ SG_ 1006 VC_BU_AUTO_HL "Backup for Auto headlamp feature present; present = [1]";
CM_ SG_ 1006 VC_BU_AutoParkPrsnt "Backup for automatic transmission parking feature is present; present = [1]";
CM_ SG_ 1006 VC_BU_Base_TPM "Backup for Base TPM system present; present = [1]";
CM_ SG_ 1006 VC_BU_CMP_DISP "Backup for display compass heading present; present = [1]";
CM_ SG_ 1006 VC_BU_CMS "Backup for Collision Mitigation System present; present = [1]";
CM_ SG_ 1006 VC_BU_ChassisType "Backup for chassis type (including suspension, brakes, and tires)";
CM_ SG_ 1006 VC_BU_DSBL_CLK_DISP "Backup of Disable display of radio clock; 1 = clock display disabled";
CM_ SG_ 1006 VC_BU_DrAlrPrsnt "Backup for Door alert feature present; present = [1]";
CM_ SG_ 1006 VC_BU_DualFuelSens "Backup for Vehicle equipped with two fuel sending units; present = [1]";
CM_ SG_ 1006 VC_BU_ELV_PRSNT "Backup for ELV system present; enabled=[1], disabled=[0]";
CM_ SG_ 1006 VC_BU_ESCL_Prsnt "Backup for ESCL system present; enabled=[1], disabled=[0]";
CM_ SG_ 1006 VC_BU_FCW "Backup for Forward Collision Warning present; present = [1]";
CM_ SG_ 1006 VC_BU_FOBIKsafeENBL "Backup for FOBIK safe feature; present = [1]";
CM_ SG_ 1006 VC_BU_FUEL_CAP "Backup for Fuel capacity";
CM_ SG_ 1006 VC_BU_HID_HL "Backup for High intensity discharge head lamps; present = [1]";
CM_ SG_ 1006 VC_BU_HVAC_Config "Backup for HVAC Configuration";
CM_ SG_ 1006 VC_BU_IntEC_MIRR "Backup for vehicle is equipped with an interior EC mirror; present = [1]";
CM_ SG_ 1006 VC_BU_KG_Prsnt "Backup for keyless go is present; present = [1]";
CM_ SG_ 1006 VC_BU_Liftgate_Trunk "Backup for Liftgate or trunk";
CM_ SG_ 1006 VC_BU_PDDL_PRSNT "backup for Paddle shift feature is present; present = [1]";
CM_ SG_ 1006 VC_BU_PE_Prsnt "Backup for passive entry is present; present = [1]";
CM_ SG_ 1006 VC_BU_POLICE "Backup for Police lighting feature; present = [1]";
CM_ SG_ 1006 VC_BU_PWR_LFT_GT "Backup for Power lift gate present; present = [1]";
CM_ SG_ 1006 VC_BU_PWR_LT_SLDR "Backup for Power left sliding door present; present = [1]";
CM_ SG_ 1006 VC_BU_PWR_RT_SLDR "Backup for Power right sliding door present; present = [1]";
CM_ SG_ 1006 VC_BU_Prem_TPM "Backup for Premium TPM system present; present = [1]";
CM_ SG_ 1006 VC_BU_RKE_PRSNT "Backup for RKE system present; present = [1]";
CM_ SG_ 1006 VC_BU_SPORT_PRSNT "Backup for Sport mode is present; present = [1]";
CM_ SG_ 1006 VC_BU_SRT_PRSNT "Backup for Vehicle is an SRT; present = [1]";
CM_ SG_ 1006 VC_BU_SecLkPrsnt "Backup for Secondary Lock Present; [1] = True";
CM_ SG_ 1006 VC_BU_SunShade_Present "Backup for Vehicle equipped w/SunShade (1=present)";
CM_ SG_ 1006 VC_BU_TEMP_DISP "Backup for display outside temperature present; present = [1]";
CM_ SG_ 1006 VC_BU_TcaseTyp "Backup for Tcase type";
CM_ SG_ 1006 VC_BU_VEH_BRAND "Backup for Vehicle brand type";
CM_ SG_ 1006 VC_BU_VehCfg3_Stat "Backup for Configuration messages status 3";
CM_ SG_ 1006 VC_BU_WHL_BASE "Backup for Wheel base";
CM_ SG_ 1006 VC_BU_WIN_EXPR_FEAT "Backup for Window express feature configuration";
CM_ SG_ 1007 VC_BU_AXLE_RATIO "Backup for Axle ratio";
CM_ SG_ 1007 VC_BU_TCASE_HI_RATIO "Backup for Transfer case high ratio";
CM_ SG_ 1007 VC_BU_TCASE_LO_RATIO "Backup for Transfer case low range reduction ratio";
CM_ SG_ 1007 VC_BU_TIRE_CIRCUMF "Backup for Dynamic tire circumference (all or rear)";
CM_ SG_ 1007 VC_BU_VehCfg4_Stat "Backup for Configuration messages status 4";
BA_DEF_ BO_  "App-Botschaft" ENUM  "nein","ja";
BA_DEF_ BO_  "CanMsgMinLen" INT 0 8;
BA_DEF_ BO_  "DiagRequest" ENUM  "nein","ja";
BA_DEF_ BO_  "DiagResponse" ENUM  "nein","ja";
BA_DEF_ BO_  "DiagState" ENUM  "nein","ja";
BA_DEF_ BO_  "GenMsgCycleTime" INT 0 65535;
BA_DEF_ BO_  "GenMsgCycleTimeActive" INT 0 65535;
BA_DEF_ BO_  "GenMsgDelayTime" INT 0 65535;
BA_DEF_ BO_  "GenMsgNrOfRepetitions" INT 0 65535;
BA_DEF_ BO_  "GenMsgSendType" ENUM  "cyclicX","spontanX","cyclicIfActiveX","spontanWithDelay","cyclicAndSpontanX","cyclicAndSpontanWithDelay","spontanWithRepitition","cyclicIfActiveAndSpontanWD","cyclicIfActiveFast","cyclicWithRepeatOnDemand","none";
BA_DEF_ BO_  "GenMsgStartDelayTime" INT 0 65535;
BA_DEF_ BO_  "GenMsgStartValue" STRING ;
BA_DEF_ BO_  "NWM-Botschaft" ENUM  "nein","ja";
BA_DEF_ BO_  "TpTxIndex" INT 0 99;
BA_DEF_ SG_  "FlexKomComment" STRING ;
BA_DEF_ SG_  "FlexKomIsMotorola" ENUM  "nein","ja";
BA_DEF_ SG_  "FlexKomSID" INT 0 2147483647;
BA_DEF_ SG_  "FlexKomSigLaenge" INT 0 64;
BA_DEF_ SG_  "FlexKomSigName" STRING ;
BA_DEF_ SG_  "FlexKomSigStartPos" INT 0 63;
BA_DEF_ SG_  "FlexKomSigStartValue" STRING ;
BA_DEF_ SG_  "GenSigCycleTime" INT 0 65535;
BA_DEF_ SG_  "GenSigCycleTimeActive" INT 0 65535;
BA_DEF_ SG_  "GenSigSendType" ENUM  "cyclicX","spontanX","cyclicIfActiveX","spontanWithDelay","cyclicAndSpontanX","cyclicAndSpontanWithDelay","spontanWithRepitition","cyclicIfActiveAndSpontanWD","cyclicIfActiveFast","cyclicWithRepeatOnDemand","none";
BA_DEF_ SG_  "GenSigSNA" STRING ;
BA_DEF_ SG_  "GenSigStartValue" HEX 0 2147483648;
BA_DEF_ SG_  "GenSigTimeout_AHLM" INT 0 65535;
BA_DEF_ SG_  "GenSigTimeout_ASBS" INT 0 65535;
BA_DEF_ SG_  "GenSigTimeout_CBC" INT 0 65535;
BA_DEF_ SG_  "GenSigTimeout_DPDM" INT 0 65535;
BA_DEF_ SG_  "GenSigTimeout_DTCM" INT 0 65535;
BA_DEF_ SG_  "GenSigTimeout_EHPS" INT 0 65535;
BA_DEF_ SG_  "GenSigTimeout_ESC" INT 0 65535;
BA_DEF_ SG_  "GenSigTimeout_ESL" INT 0 65535;
BA_DEF_ SG_  "GenSigTimeout_ESM" INT 0 65535;
BA_DEF_ SG_  "GenSigTimeout_ETM" INT 0 65535;
BA_DEF_ SG_  "GenSigTimeout_IC" INT 0 65535;
BA_DEF_ SG_  "GenSigTimeout_OCM" INT 0 65535;
BA_DEF_ SG_  "GenSigTimeout_ORC" INT 0 65535;
BA_DEF_ SG_  "GenSigTimeout_PTS" INT 0 65535;
BA_DEF_ SG_  "GenSigTimeout_RF_HUB" INT 0 65535;
BA_DEF_ SG_  "GenSigTimeout_SCCM" INT 0 65535;
BA_DEF_ SG_  "GenSigTimeout_TBM" INT 0 65535;
BA_DEF_ SG_  "GenSigTimeout_TCM" INT 0 65535;
BA_DEF_ SG_  "GenSigTimeout_TPM" INT 0 65535;
BA_DEF_ SG_  "RID" STRING ;
BA_DEF_ SG_  "SystemSignalLongSymbol" STRING ;
BA_DEF_DEF_  "App-Botschaft" "nein";
BA_DEF_DEF_  "CanMsgMinLen" 0;
BA_DEF_DEF_  "DiagRequest" "nein";
BA_DEF_DEF_  "DiagResponse" "nein";
BA_DEF_DEF_  "DiagState" "nein";
BA_DEF_DEF_  "GenMsgCycleTime" 0;
BA_DEF_DEF_  "GenMsgCycleTimeActive" 0;
BA_DEF_DEF_  "GenMsgDelayTime" 0;
BA_DEF_DEF_  "GenMsgNrOfRepetitions" 0;
BA_DEF_DEF_  "GenMsgSendType" "cyclicX";
BA_DEF_DEF_  "GenMsgStartDelayTime" 0;
BA_DEF_DEF_  "GenMsgStartValue" "";
BA_DEF_DEF_  "NWM-Botschaft" "nein";
BA_DEF_DEF_  "TpTxIndex" 0;
BA_DEF_DEF_  "FlexKomComment" "";
BA_DEF_DEF_  "FlexKomIsMotorola" "nein";
BA_DEF_DEF_  "FlexKomSID" 0;
BA_DEF_DEF_  "FlexKomSigLaenge" 0;
BA_DEF_DEF_  "FlexKomSigName" "";
BA_DEF_DEF_  "FlexKomSigStartPos" 0;
BA_DEF_DEF_  "FlexKomSigStartValue" "";
BA_DEF_DEF_  "GenSigCycleTime" 0;
BA_DEF_DEF_  "GenSigCycleTimeActive" 0;
BA_DEF_DEF_  "GenSigSendType" "cyclicX";
BA_DEF_DEF_  "GenSigSNA" "";
BA_DEF_DEF_  "GenSigStartValue" 0;
BA_DEF_DEF_  "GenSigTimeout_AHLM" 0;
BA_DEF_DEF_  "GenSigTimeout_ASBS" 0;
BA_DEF_DEF_  "GenSigTimeout_CBC" 0;
BA_DEF_DEF_  "GenSigTimeout_DPDM" 0;
BA_DEF_DEF_  "GenSigTimeout_DTCM" 0;
BA_DEF_DEF_  "GenSigTimeout_EHPS" 0;
BA_DEF_DEF_  "GenSigTimeout_ESC" 0;
BA_DEF_DEF_  "GenSigTimeout_ESL" 0;
BA_DEF_DEF_  "GenSigTimeout_ESM" 0;
BA_DEF_DEF_  "GenSigTimeout_ETM" 0;
BA_DEF_DEF_  "GenSigTimeout_IC" 0;
BA_DEF_DEF_  "GenSigTimeout_OCM" 0;
BA_DEF_DEF_  "GenSigTimeout_ORC" 0;
BA_DEF_DEF_  "GenSigTimeout_PTS" 0;
BA_DEF_DEF_  "GenSigTimeout_RF_HUB" 0;
BA_DEF_DEF_  "GenSigTimeout_SCCM" 0;
BA_DEF_DEF_  "GenSigTimeout_TBM" 0;
BA_DEF_DEF_  "GenSigTimeout_TCM" 0;
BA_DEF_DEF_  "GenSigTimeout_TPM" 0;
BA_DEF_DEF_  "RID" "";
BA_DEF_DEF_  "SystemSignalLongSymbol" "";
BA_ "GenMsgStartValue" BO_ 1002 "0370FF037FFF0000h";
BA_ "GenMsgStartDelayTime" BO_ 1002 50;
BA_ "GenMsgSendType" BO_ 1002 5;
BA_ "GenMsgNrOfRepetitions" BO_ 1002 2;
BA_ "GenMsgDelayTime" BO_ 1002 20;
BA_ "GenMsgCycleTime" BO_ 1002 2000;
BA_ "GenMsgStartValue" BO_ 1003 "FFFFFFFFFFFFFFFFh";
BA_ "GenMsgStartDelayTime" BO_ 1003 120;
BA_ "GenMsgSendType" BO_ 1003 5;
BA_ "GenMsgNrOfRepetitions" BO_ 1003 2;
BA_ "GenMsgDelayTime" BO_ 1003 20;
BA_ "GenMsgCycleTime" BO_ 1003 1000;
BA_ "GenMsgStartValue" BO_ 1098 "C3FFFFFFFFFFFF00h";
BA_ "GenMsgStartDelayTime" BO_ 1098 60;
BA_ "GenMsgSendType" BO_ 1098 5;
BA_ "GenMsgNrOfRepetitions" BO_ 1098 2;
BA_ "GenMsgDelayTime" BO_ 1098 20;
BA_ "GenMsgCycleTime" BO_ 1098 2000;
BA_ "GenMsgStartValue" BO_ 1100 "73FFFFFFFFFFFFFFh";
BA_ "GenMsgStartDelayTime" BO_ 1100 70;
BA_ "GenMsgSendType" BO_ 1100 5;
BA_ "GenMsgNrOfRepetitions" BO_ 1100 2;
BA_ "GenMsgDelayTime" BO_ 1100 20;
BA_ "GenMsgCycleTime" BO_ 1100 2000;
BA_ "GenMsgStartValue" BO_ 897 "033F000000000000h";
BA_ "GenMsgSendType" BO_ 897 5;
BA_ "GenMsgNrOfRepetitions" BO_ 897 2;
BA_ "GenMsgDelayTime" BO_ 897 20;
BA_ "GenMsgCycleTime" BO_ 897 2000;
BA_ "GenMsgStartValue" BO_ 906 "0300000000000000h";
BA_ "GenMsgSendType" BO_ 906 5;
BA_ "GenMsgNrOfRepetitions" BO_ 906 2;
BA_ "GenMsgDelayTime" BO_ 906 20;
BA_ "GenMsgCycleTime" BO_ 906 2000;
BA_ "GenMsgStartValue" BO_ 1004 "FFFF7FF0FF0FFF00h";
BA_ "GenMsgSendType" BO_ 1004 1;
BA_ "GenMsgNrOfRepetitions" BO_ 1004 2;
BA_ "GenMsgDelayTime" BO_ 1004 20;
BA_ "GenMsgStartValue" BO_ 1005 "0300FF00FFFFFFFFh";
BA_ "GenMsgSendType" BO_ 1005 1;
BA_ "GenMsgNrOfRepetitions" BO_ 1005 2;
BA_ "GenMsgDelayTime" BO_ 1005 20;
BA_ "GenMsgStartValue" BO_ 1006 "0370FF037FFF0000h";
BA_ "GenMsgSendType" BO_ 1006 1;
BA_ "GenMsgNrOfRepetitions" BO_ 1006 2;
BA_ "GenMsgDelayTime" BO_ 1006 20;
BA_ "GenMsgStartValue" BO_ 1007 "FFFFFFFFFFFFFFFFh";
BA_ "GenMsgSendType" BO_ 1007 1;
BA_ "GenMsgNrOfRepetitions" BO_ 1007 2;
BA_ "GenMsgDelayTime" BO_ 1007 20;
BA_ "GenSigSNA" SG_ 1002 VC_ADJ_PDL_PRSNT "0h";
BA_ "GenSigSendType" SG_ 1002 VC_ADJ_PDL_PRSNT 5;
BA_ "GenSigCycleTime" SG_ 1002 VC_ADJ_PDL_PRSNT 2000;
BA_ "FlexKomSigStartValue" SG_ 1002 VC_ADJ_PDL_PRSNT "0370FF037FFF0000h";
BA_ "FlexKomSigStartPos" SG_ 1002 VC_ADJ_PDL_PRSNT 7;
BA_ "FlexKomSigName" SG_ 1002 VC_ADJ_PDL_PRSNT "VehCfg3_Pkt";
BA_ "FlexKomSigLaenge" SG_ 1002 VC_ADJ_PDL_PRSNT 64;
BA_ "FlexKomSID" SG_ 1002 VC_ADJ_PDL_PRSNT 888;
BA_ "FlexKomIsMotorola" SG_ 1002 VC_ADJ_PDL_PRSNT 1;
BA_ "FlexKomComment" SG_ 1002 VC_ADJ_PDL_PRSNT "Vehicle Configuration 3 Packet";
BA_ "GenSigTimeout_IC" SG_ 1002 VC_AUTO_HL 21000;
BA_ "GenSigSNA" SG_ 1002 VC_AUTO_HL "0h";
BA_ "GenSigSendType" SG_ 1002 VC_AUTO_HL 5;
BA_ "GenSigCycleTime" SG_ 1002 VC_AUTO_HL 2000;
BA_ "FlexKomSigStartValue" SG_ 1002 VC_AUTO_HL "0370FF037FFF0000h";
BA_ "FlexKomSigStartPos" SG_ 1002 VC_AUTO_HL 7;
BA_ "FlexKomSigName" SG_ 1002 VC_AUTO_HL "VehCfg3_Pkt";
BA_ "FlexKomSigLaenge" SG_ 1002 VC_AUTO_HL 64;
BA_ "FlexKomSID" SG_ 1002 VC_AUTO_HL 888;
BA_ "FlexKomIsMotorola" SG_ 1002 VC_AUTO_HL 1;
BA_ "FlexKomComment" SG_ 1002 VC_AUTO_HL "Vehicle Configuration 3 Packet";
BA_ "GenSigTimeout_IC" SG_ 1002 VC_AutoParkPrsnt 21000;
BA_ "GenSigSNA" SG_ 1002 VC_AutoParkPrsnt "0h";
BA_ "GenSigSendType" SG_ 1002 VC_AutoParkPrsnt 5;
BA_ "GenSigCycleTime" SG_ 1002 VC_AutoParkPrsnt 2000;
BA_ "FlexKomSigStartValue" SG_ 1002 VC_AutoParkPrsnt "0370FF037FFF0000h";
BA_ "FlexKomSigStartPos" SG_ 1002 VC_AutoParkPrsnt 7;
BA_ "FlexKomSigName" SG_ 1002 VC_AutoParkPrsnt "VehCfg3_Pkt";
BA_ "FlexKomSigLaenge" SG_ 1002 VC_AutoParkPrsnt 64;
BA_ "FlexKomSID" SG_ 1002 VC_AutoParkPrsnt 888;
BA_ "FlexKomIsMotorola" SG_ 1002 VC_AutoParkPrsnt 1;
BA_ "FlexKomComment" SG_ 1002 VC_AutoParkPrsnt "Vehicle Configuration 3 Packet";
BA_ "GenSigTimeout_TPM" SG_ 1002 VC_Base_TPM 21000;
BA_ "GenSigTimeout_ORC" SG_ 1002 VC_Base_TPM 7000;
BA_ "GenSigTimeout_IC" SG_ 1002 VC_Base_TPM 21000;
BA_ "GenSigSNA" SG_ 1002 VC_Base_TPM "0h";
BA_ "GenSigSendType" SG_ 1002 VC_Base_TPM 5;
BA_ "GenSigCycleTime" SG_ 1002 VC_Base_TPM 2000;
BA_ "FlexKomSigStartValue" SG_ 1002 VC_Base_TPM "0370FF037FFF0000h";
BA_ "FlexKomSigStartPos" SG_ 1002 VC_Base_TPM 7;
BA_ "FlexKomSigName" SG_ 1002 VC_Base_TPM "VehCfg3_Pkt";
BA_ "FlexKomSigLaenge" SG_ 1002 VC_Base_TPM 64;
BA_ "FlexKomSID" SG_ 1002 VC_Base_TPM 888;
BA_ "FlexKomIsMotorola" SG_ 1002 VC_Base_TPM 1;
BA_ "FlexKomComment" SG_ 1002 VC_Base_TPM "Vehicle Configuration 3 Packet";
BA_ "GenSigTimeout_IC" SG_ 1002 VC_CMP_DISP 21000;
BA_ "GenSigSNA" SG_ 1002 VC_CMP_DISP "0h";
BA_ "GenSigSendType" SG_ 1002 VC_CMP_DISP 5;
BA_ "GenSigCycleTime" SG_ 1002 VC_CMP_DISP 2000;
BA_ "FlexKomSigStartValue" SG_ 1002 VC_CMP_DISP "0370FF037FFF0000h";
BA_ "FlexKomSigStartPos" SG_ 1002 VC_CMP_DISP 7;
BA_ "FlexKomSigName" SG_ 1002 VC_CMP_DISP "VehCfg3_Pkt";
BA_ "FlexKomSigLaenge" SG_ 1002 VC_CMP_DISP 64;
BA_ "FlexKomSID" SG_ 1002 VC_CMP_DISP 888;
BA_ "FlexKomIsMotorola" SG_ 1002 VC_CMP_DISP 1;
BA_ "FlexKomComment" SG_ 1002 VC_CMP_DISP "Vehicle Configuration 3 Packet";
BA_ "GenSigTimeout_ORC" SG_ 1002 VC_CMS 7000;
BA_ "GenSigSNA" SG_ 1002 VC_CMS "0h";
BA_ "GenSigSendType" SG_ 1002 VC_CMS 5;
BA_ "GenSigCycleTime" SG_ 1002 VC_CMS 2000;
BA_ "FlexKomSigStartValue" SG_ 1002 VC_CMS "0370FF037FFF0000h";
BA_ "FlexKomSigStartPos" SG_ 1002 VC_CMS 7;
BA_ "FlexKomSigName" SG_ 1002 VC_CMS "VehCfg3_Pkt";
BA_ "FlexKomSigLaenge" SG_ 1002 VC_CMS 64;
BA_ "FlexKomSID" SG_ 1002 VC_CMS 888;
BA_ "FlexKomIsMotorola" SG_ 1002 VC_CMS 1;
BA_ "FlexKomComment" SG_ 1002 VC_CMS "Vehicle Configuration 3 Packet";
BA_ "GenSigTimeout_PTS" SG_ 1002 VC_ChassisType 21000;
BA_ "GenSigTimeout_ORC" SG_ 1002 VC_ChassisType 7000;
BA_ "GenSigTimeout_EHPS" SG_ 1002 VC_ChassisType 21000;
BA_ "GenSigStartValue" SG_ 1002 VC_ChassisType 127;
BA_ "GenSigSNA" SG_ 1002 VC_ChassisType "7Fh";
BA_ "GenSigSendType" SG_ 1002 VC_ChassisType 5;
BA_ "GenSigCycleTime" SG_ 1002 VC_ChassisType 2000;
BA_ "FlexKomSigStartValue" SG_ 1002 VC_ChassisType "0370FF037FFF0000h";
BA_ "FlexKomSigStartPos" SG_ 1002 VC_ChassisType 7;
BA_ "FlexKomSigName" SG_ 1002 VC_ChassisType "VehCfg3_Pkt";
BA_ "FlexKomSigLaenge" SG_ 1002 VC_ChassisType 64;
BA_ "FlexKomSID" SG_ 1002 VC_ChassisType 888;
BA_ "FlexKomIsMotorola" SG_ 1002 VC_ChassisType 1;
BA_ "FlexKomComment" SG_ 1002 VC_ChassisType "Vehicle Configuration 3 Packet";
BA_ "GenSigTimeout_IC" SG_ 1002 VC_DSBL_CLK_DISP 21000;
BA_ "GenSigSNA" SG_ 1002 VC_DSBL_CLK_DISP "0h";
BA_ "GenSigSendType" SG_ 1002 VC_DSBL_CLK_DISP 5;
BA_ "GenSigCycleTime" SG_ 1002 VC_DSBL_CLK_DISP 2000;
BA_ "FlexKomSigStartValue" SG_ 1002 VC_DSBL_CLK_DISP "0370FF037FFF0000h";
BA_ "FlexKomSigStartPos" SG_ 1002 VC_DSBL_CLK_DISP 7;
BA_ "FlexKomSigName" SG_ 1002 VC_DSBL_CLK_DISP "VehCfg3_Pkt";
BA_ "FlexKomSigLaenge" SG_ 1002 VC_DSBL_CLK_DISP 64;
BA_ "FlexKomSID" SG_ 1002 VC_DSBL_CLK_DISP 888;
BA_ "FlexKomIsMotorola" SG_ 1002 VC_DSBL_CLK_DISP 1;
BA_ "FlexKomComment" SG_ 1002 VC_DSBL_CLK_DISP "Vehicle Configuration 3 Packet";
BA_ "GenSigTimeout_IC" SG_ 1002 VC_DrAlrPrsnt 21000;
BA_ "GenSigSNA" SG_ 1002 VC_DrAlrPrsnt "0h";
BA_ "GenSigSendType" SG_ 1002 VC_DrAlrPrsnt 5;
BA_ "GenSigCycleTime" SG_ 1002 VC_DrAlrPrsnt 2000;
BA_ "FlexKomSigStartValue" SG_ 1002 VC_DrAlrPrsnt "0370FF037FFF0000h";
BA_ "FlexKomSigStartPos" SG_ 1002 VC_DrAlrPrsnt 7;
BA_ "FlexKomSigName" SG_ 1002 VC_DrAlrPrsnt "VehCfg3_Pkt";
BA_ "FlexKomSigLaenge" SG_ 1002 VC_DrAlrPrsnt 64;
BA_ "FlexKomSID" SG_ 1002 VC_DrAlrPrsnt 888;
BA_ "FlexKomIsMotorola" SG_ 1002 VC_DrAlrPrsnt 1;
BA_ "FlexKomComment" SG_ 1002 VC_DrAlrPrsnt "Vehicle Configuration 3 Packet";
BA_ "GenSigTimeout_IC" SG_ 1002 VC_DualFuelSens 21000;
BA_ "GenSigSNA" SG_ 1002 VC_DualFuelSens "0h";
BA_ "GenSigSendType" SG_ 1002 VC_DualFuelSens 5;
BA_ "GenSigCycleTime" SG_ 1002 VC_DualFuelSens 2000;
BA_ "FlexKomSigStartValue" SG_ 1002 VC_DualFuelSens "0370FF037FFF0000h";
BA_ "FlexKomSigStartPos" SG_ 1002 VC_DualFuelSens 7;
BA_ "FlexKomSigName" SG_ 1002 VC_DualFuelSens "VehCfg3_Pkt";
BA_ "FlexKomSigLaenge" SG_ 1002 VC_DualFuelSens 64;
BA_ "FlexKomSID" SG_ 1002 VC_DualFuelSens 888;
BA_ "FlexKomIsMotorola" SG_ 1002 VC_DualFuelSens 1;
BA_ "FlexKomComment" SG_ 1002 VC_DualFuelSens "Vehicle Configuration 3 Packet";
BA_ "GenSigSNA" SG_ 1002 VC_ELV_Prsnt "0h";
BA_ "GenSigSendType" SG_ 1002 VC_ELV_Prsnt 5;
BA_ "GenSigCycleTime" SG_ 1002 VC_ELV_Prsnt 2000;
BA_ "FlexKomSigStartValue" SG_ 1002 VC_ELV_Prsnt "0370FF037FFF0000h";
BA_ "FlexKomSigStartPos" SG_ 1002 VC_ELV_Prsnt 7;
BA_ "FlexKomSigName" SG_ 1002 VC_ELV_Prsnt "VehCfg3_Pkt";
BA_ "FlexKomSigLaenge" SG_ 1002 VC_ELV_Prsnt 64;
BA_ "FlexKomSID" SG_ 1002 VC_ELV_Prsnt 888;
BA_ "FlexKomIsMotorola" SG_ 1002 VC_ELV_Prsnt 1;
BA_ "FlexKomComment" SG_ 1002 VC_ELV_Prsnt "Vehicle Configuration 3 Packet";
BA_ "GenSigSNA" SG_ 1002 VC_ESCL_PRSNT "0h";
BA_ "GenSigSendType" SG_ 1002 VC_ESCL_PRSNT 5;
BA_ "GenSigCycleTime" SG_ 1002 VC_ESCL_PRSNT 2000;
BA_ "FlexKomSigStartValue" SG_ 1002 VC_ESCL_PRSNT "0370FF037FFF0000h";
BA_ "FlexKomSigStartPos" SG_ 1002 VC_ESCL_PRSNT 7;
BA_ "FlexKomSigName" SG_ 1002 VC_ESCL_PRSNT "VehCfg3_Pkt";
BA_ "FlexKomSigLaenge" SG_ 1002 VC_ESCL_PRSNT 64;
BA_ "FlexKomSID" SG_ 1002 VC_ESCL_PRSNT 888;
BA_ "FlexKomIsMotorola" SG_ 1002 VC_ESCL_PRSNT 1;
BA_ "FlexKomComment" SG_ 1002 VC_ESCL_PRSNT "Vehicle Configuration 3 Packet";
BA_ "GenSigTimeout_ORC" SG_ 1002 VC_FCW 7000;
BA_ "GenSigSNA" SG_ 1002 VC_FCW "0h";
BA_ "GenSigSendType" SG_ 1002 VC_FCW 5;
BA_ "GenSigCycleTime" SG_ 1002 VC_FCW 2000;
BA_ "FlexKomSigStartValue" SG_ 1002 VC_FCW "0370FF037FFF0000h";
BA_ "FlexKomSigStartPos" SG_ 1002 VC_FCW 7;
BA_ "FlexKomSigName" SG_ 1002 VC_FCW "VehCfg3_Pkt";
BA_ "FlexKomSigLaenge" SG_ 1002 VC_FCW 64;
BA_ "FlexKomSID" SG_ 1002 VC_FCW 888;
BA_ "FlexKomIsMotorola" SG_ 1002 VC_FCW 1;
BA_ "FlexKomComment" SG_ 1002 VC_FCW "Vehicle Configuration 3 Packet";
BA_ "GenSigStartValue" SG_ 1002 VC_FOBIKsafeENBL 1;
BA_ "GenSigSNA" SG_ 1002 VC_FOBIKsafeENBL "1h";
BA_ "GenSigSendType" SG_ 1002 VC_FOBIKsafeENBL 5;
BA_ "GenSigCycleTime" SG_ 1002 VC_FOBIKsafeENBL 2000;
BA_ "FlexKomSigStartValue" SG_ 1002 VC_FOBIKsafeENBL "0370FF037FFF0000h";
BA_ "FlexKomSigStartPos" SG_ 1002 VC_FOBIKsafeENBL 7;
BA_ "FlexKomSigName" SG_ 1002 VC_FOBIKsafeENBL "VehCfg3_Pkt";
BA_ "FlexKomSigLaenge" SG_ 1002 VC_FOBIKsafeENBL 64;
BA_ "FlexKomSID" SG_ 1002 VC_FOBIKsafeENBL 888;
BA_ "FlexKomIsMotorola" SG_ 1002 VC_FOBIKsafeENBL 1;
BA_ "FlexKomComment" SG_ 1002 VC_FOBIKsafeENBL "Vehicle Configuration 3 Packet";
BA_ "GenSigTimeout_IC" SG_ 1002 VC_FUEL_CAP 21000;
BA_ "GenSigStartValue" SG_ 1002 VC_FUEL_CAP 255;
BA_ "GenSigSNA" SG_ 1002 VC_FUEL_CAP "FFh";
BA_ "GenSigSendType" SG_ 1002 VC_FUEL_CAP 5;
BA_ "GenSigCycleTime" SG_ 1002 VC_FUEL_CAP 2000;
BA_ "FlexKomSigStartValue" SG_ 1002 VC_FUEL_CAP "0370FF037FFF0000h";
BA_ "FlexKomSigStartPos" SG_ 1002 VC_FUEL_CAP 7;
BA_ "FlexKomSigName" SG_ 1002 VC_FUEL_CAP "VehCfg3_Pkt";
BA_ "FlexKomSigLaenge" SG_ 1002 VC_FUEL_CAP 64;
BA_ "FlexKomSID" SG_ 1002 VC_FUEL_CAP 888;
BA_ "FlexKomIsMotorola" SG_ 1002 VC_FUEL_CAP 1;
BA_ "FlexKomComment" SG_ 1002 VC_FUEL_CAP "Vehicle Configuration 3 Packet";
BA_ "GenSigSNA" SG_ 1002 VC_HID_HL "0h";
BA_ "GenSigSendType" SG_ 1002 VC_HID_HL 5;
BA_ "GenSigCycleTime" SG_ 1002 VC_HID_HL 2000;
BA_ "FlexKomSigStartValue" SG_ 1002 VC_HID_HL "0370FF037FFF0000h";
BA_ "FlexKomSigStartPos" SG_ 1002 VC_HID_HL 7;
BA_ "FlexKomSigName" SG_ 1002 VC_HID_HL "VehCfg3_Pkt";
BA_ "FlexKomSigLaenge" SG_ 1002 VC_HID_HL 64;
BA_ "FlexKomSID" SG_ 1002 VC_HID_HL 888;
BA_ "FlexKomIsMotorola" SG_ 1002 VC_HID_HL 1;
BA_ "FlexKomComment" SG_ 1002 VC_HID_HL "Vehicle Configuration 3 Packet";
BA_ "GenSigTimeout_IC" SG_ 1002 VC_HVAC_Config 21000;
BA_ "GenSigStartValue" SG_ 1002 VC_HVAC_Config 15;
BA_ "GenSigSNA" SG_ 1002 VC_HVAC_Config "Fh";
BA_ "GenSigSendType" SG_ 1002 VC_HVAC_Config 5;
BA_ "GenSigCycleTime" SG_ 1002 VC_HVAC_Config 2000;
BA_ "FlexKomSigStartValue" SG_ 1002 VC_HVAC_Config "0370FF037FFF0000h";
BA_ "FlexKomSigStartPos" SG_ 1002 VC_HVAC_Config 7;
BA_ "FlexKomSigName" SG_ 1002 VC_HVAC_Config "VehCfg3_Pkt";
BA_ "FlexKomSigLaenge" SG_ 1002 VC_HVAC_Config 64;
BA_ "FlexKomSID" SG_ 1002 VC_HVAC_Config 888;
BA_ "FlexKomIsMotorola" SG_ 1002 VC_HVAC_Config 1;
BA_ "FlexKomComment" SG_ 1002 VC_HVAC_Config "Vehicle Configuration 3 Packet";
BA_ "GenSigSNA" SG_ 1002 VC_IntEC_MIRR "0h";
BA_ "GenSigSendType" SG_ 1002 VC_IntEC_MIRR 5;
BA_ "GenSigCycleTime" SG_ 1002 VC_IntEC_MIRR 2000;
BA_ "FlexKomSigStartValue" SG_ 1002 VC_IntEC_MIRR "0370FF037FFF0000h";
BA_ "FlexKomSigStartPos" SG_ 1002 VC_IntEC_MIRR 7;
BA_ "FlexKomSigName" SG_ 1002 VC_IntEC_MIRR "VehCfg3_Pkt";
BA_ "FlexKomSigLaenge" SG_ 1002 VC_IntEC_MIRR 64;
BA_ "FlexKomSID" SG_ 1002 VC_IntEC_MIRR 888;
BA_ "FlexKomIsMotorola" SG_ 1002 VC_IntEC_MIRR 1;
BA_ "FlexKomComment" SG_ 1002 VC_IntEC_MIRR "Vehicle Configuration 3 Packet";
BA_ "GenSigTimeout_IC" SG_ 1002 VC_KG_Prsnt 21000;
BA_ "GenSigSNA" SG_ 1002 VC_KG_Prsnt "0h";
BA_ "GenSigSendType" SG_ 1002 VC_KG_Prsnt 5;
BA_ "GenSigCycleTime" SG_ 1002 VC_KG_Prsnt 2000;
BA_ "FlexKomSigStartValue" SG_ 1002 VC_KG_Prsnt "0370FF037FFF0000h";
BA_ "FlexKomSigStartPos" SG_ 1002 VC_KG_Prsnt 7;
BA_ "FlexKomSigName" SG_ 1002 VC_KG_Prsnt "VehCfg3_Pkt";
BA_ "FlexKomSigLaenge" SG_ 1002 VC_KG_Prsnt 64;
BA_ "FlexKomSID" SG_ 1002 VC_KG_Prsnt 888;
BA_ "FlexKomIsMotorola" SG_ 1002 VC_KG_Prsnt 1;
BA_ "FlexKomComment" SG_ 1002 VC_KG_Prsnt "Vehicle Configuration 3 Packet";
BA_ "GenSigTimeout_IC" SG_ 1002 VC_Liftgate_Trunk 21000;
BA_ "GenSigSNA" SG_ 1002 VC_Liftgate_Trunk "3h";
BA_ "GenSigSendType" SG_ 1002 VC_Liftgate_Trunk 5;
BA_ "GenSigCycleTime" SG_ 1002 VC_Liftgate_Trunk 2000;
BA_ "FlexKomSigStartValue" SG_ 1002 VC_Liftgate_Trunk "0370FF037FFF0000h";
BA_ "FlexKomSigStartPos" SG_ 1002 VC_Liftgate_Trunk 7;
BA_ "FlexKomSigName" SG_ 1002 VC_Liftgate_Trunk "VehCfg3_Pkt";
BA_ "FlexKomSigLaenge" SG_ 1002 VC_Liftgate_Trunk 64;
BA_ "FlexKomSID" SG_ 1002 VC_Liftgate_Trunk 888;
BA_ "FlexKomIsMotorola" SG_ 1002 VC_Liftgate_Trunk 1;
BA_ "FlexKomComment" SG_ 1002 VC_Liftgate_Trunk "Vehicle Configuration 3 Packet";
BA_ "GenSigTimeout_IC" SG_ 1002 VC_PDDL_PRSNT 21000;
BA_ "GenSigSNA" SG_ 1002 VC_PDDL_PRSNT "0h";
BA_ "GenSigSendType" SG_ 1002 VC_PDDL_PRSNT 5;
BA_ "GenSigCycleTime" SG_ 1002 VC_PDDL_PRSNT 2000;
BA_ "FlexKomSigStartValue" SG_ 1002 VC_PDDL_PRSNT "0370FF037FFF0000h";
BA_ "FlexKomSigStartPos" SG_ 1002 VC_PDDL_PRSNT 7;
BA_ "FlexKomSigName" SG_ 1002 VC_PDDL_PRSNT "VehCfg3_Pkt";
BA_ "FlexKomSigLaenge" SG_ 1002 VC_PDDL_PRSNT 64;
BA_ "FlexKomSID" SG_ 1002 VC_PDDL_PRSNT 888;
BA_ "FlexKomIsMotorola" SG_ 1002 VC_PDDL_PRSNT 1;
BA_ "FlexKomComment" SG_ 1002 VC_PDDL_PRSNT "Vehicle Configuration 3 Packet";
BA_ "GenSigTimeout_IC" SG_ 1002 VC_PE_Prsnt 21000;
BA_ "GenSigSNA" SG_ 1002 VC_PE_Prsnt "0h";
BA_ "GenSigSendType" SG_ 1002 VC_PE_Prsnt 5;
BA_ "GenSigCycleTime" SG_ 1002 VC_PE_Prsnt 2000;
BA_ "FlexKomSigStartValue" SG_ 1002 VC_PE_Prsnt "0370FF037FFF0000h";
BA_ "FlexKomSigStartPos" SG_ 1002 VC_PE_Prsnt 7;
BA_ "FlexKomSigName" SG_ 1002 VC_PE_Prsnt "VehCfg3_Pkt";
BA_ "FlexKomSigLaenge" SG_ 1002 VC_PE_Prsnt 64;
BA_ "FlexKomSID" SG_ 1002 VC_PE_Prsnt 888;
BA_ "FlexKomIsMotorola" SG_ 1002 VC_PE_Prsnt 1;
BA_ "FlexKomComment" SG_ 1002 VC_PE_Prsnt "Vehicle Configuration 3 Packet";
BA_ "GenSigTimeout_ORC" SG_ 1002 VC_POLICE 7000;
BA_ "GenSigTimeout_IC" SG_ 1002 VC_POLICE 21000;
BA_ "GenSigSNA" SG_ 1002 VC_POLICE "0h";
BA_ "GenSigSendType" SG_ 1002 VC_POLICE 5;
BA_ "GenSigCycleTime" SG_ 1002 VC_POLICE 2000;
BA_ "FlexKomSigStartValue" SG_ 1002 VC_POLICE "0370FF037FFF0000h";
BA_ "FlexKomSigStartPos" SG_ 1002 VC_POLICE 7;
BA_ "FlexKomSigName" SG_ 1002 VC_POLICE "VehCfg3_Pkt";
BA_ "FlexKomSigLaenge" SG_ 1002 VC_POLICE 64;
BA_ "FlexKomSID" SG_ 1002 VC_POLICE 888;
BA_ "FlexKomIsMotorola" SG_ 1002 VC_POLICE 1;
BA_ "FlexKomComment" SG_ 1002 VC_POLICE "Vehicle Configuration 3 Packet";
BA_ "GenSigSNA" SG_ 1002 VC_PWR_LFT_GT "0h";
BA_ "GenSigSendType" SG_ 1002 VC_PWR_LFT_GT 5;
BA_ "GenSigCycleTime" SG_ 1002 VC_PWR_LFT_GT 2000;
BA_ "FlexKomSigStartValue" SG_ 1002 VC_PWR_LFT_GT "0370FF037FFF0000h";
BA_ "FlexKomSigStartPos" SG_ 1002 VC_PWR_LFT_GT 7;
BA_ "FlexKomSigName" SG_ 1002 VC_PWR_LFT_GT "VehCfg3_Pkt";
BA_ "FlexKomSigLaenge" SG_ 1002 VC_PWR_LFT_GT 64;
BA_ "FlexKomSID" SG_ 1002 VC_PWR_LFT_GT 888;
BA_ "FlexKomIsMotorola" SG_ 1002 VC_PWR_LFT_GT 1;
BA_ "FlexKomComment" SG_ 1002 VC_PWR_LFT_GT "Vehicle Configuration 3 Packet";
BA_ "GenSigSNA" SG_ 1002 VC_PWR_LT_SLDR "0h";
BA_ "GenSigSendType" SG_ 1002 VC_PWR_LT_SLDR 5;
BA_ "GenSigCycleTime" SG_ 1002 VC_PWR_LT_SLDR 2000;
BA_ "FlexKomSigStartValue" SG_ 1002 VC_PWR_LT_SLDR "0370FF037FFF0000h";
BA_ "FlexKomSigStartPos" SG_ 1002 VC_PWR_LT_SLDR 7;
BA_ "FlexKomSigName" SG_ 1002 VC_PWR_LT_SLDR "VehCfg3_Pkt";
BA_ "FlexKomSigLaenge" SG_ 1002 VC_PWR_LT_SLDR 64;
BA_ "FlexKomSID" SG_ 1002 VC_PWR_LT_SLDR 888;
BA_ "FlexKomIsMotorola" SG_ 1002 VC_PWR_LT_SLDR 1;
BA_ "FlexKomComment" SG_ 1002 VC_PWR_LT_SLDR "Vehicle Configuration 3 Packet";
BA_ "GenSigSNA" SG_ 1002 VC_PWR_RT_SLDR "0h";
BA_ "GenSigSendType" SG_ 1002 VC_PWR_RT_SLDR 5;
BA_ "GenSigCycleTime" SG_ 1002 VC_PWR_RT_SLDR 2000;
BA_ "FlexKomSigStartValue" SG_ 1002 VC_PWR_RT_SLDR "0370FF037FFF0000h";
BA_ "FlexKomSigStartPos" SG_ 1002 VC_PWR_RT_SLDR 7;
BA_ "FlexKomSigName" SG_ 1002 VC_PWR_RT_SLDR "VehCfg3_Pkt";
BA_ "FlexKomSigLaenge" SG_ 1002 VC_PWR_RT_SLDR 64;
BA_ "FlexKomSID" SG_ 1002 VC_PWR_RT_SLDR 888;
BA_ "FlexKomIsMotorola" SG_ 1002 VC_PWR_RT_SLDR 1;
BA_ "FlexKomComment" SG_ 1002 VC_PWR_RT_SLDR "Vehicle Configuration 3 Packet";
BA_ "GenSigTimeout_TPM" SG_ 1002 VC_Prem_TPM 21000;
BA_ "GenSigTimeout_ORC" SG_ 1002 VC_Prem_TPM 7000;
BA_ "GenSigTimeout_IC" SG_ 1002 VC_Prem_TPM 21000;
BA_ "GenSigSNA" SG_ 1002 VC_Prem_TPM "0h";
BA_ "GenSigSendType" SG_ 1002 VC_Prem_TPM 5;
BA_ "GenSigCycleTime" SG_ 1002 VC_Prem_TPM 2000;
BA_ "FlexKomSigStartValue" SG_ 1002 VC_Prem_TPM "0370FF037FFF0000h";
BA_ "FlexKomSigStartPos" SG_ 1002 VC_Prem_TPM 7;
BA_ "FlexKomSigName" SG_ 1002 VC_Prem_TPM "VehCfg3_Pkt";
BA_ "FlexKomSigLaenge" SG_ 1002 VC_Prem_TPM 64;
BA_ "FlexKomSID" SG_ 1002 VC_Prem_TPM 888;
BA_ "FlexKomIsMotorola" SG_ 1002 VC_Prem_TPM 1;
BA_ "FlexKomComment" SG_ 1002 VC_Prem_TPM "Vehicle Configuration 3 Packet";
BA_ "GenSigTimeout_IC" SG_ 1002 VC_RKE_PRSNT 21000;
BA_ "GenSigSNA" SG_ 1002 VC_RKE_PRSNT "0h";
BA_ "GenSigSendType" SG_ 1002 VC_RKE_PRSNT 5;
BA_ "GenSigCycleTime" SG_ 1002 VC_RKE_PRSNT 2000;
BA_ "FlexKomSigStartValue" SG_ 1002 VC_RKE_PRSNT "0370FF037FFF0000h";
BA_ "FlexKomSigStartPos" SG_ 1002 VC_RKE_PRSNT 7;
BA_ "FlexKomSigName" SG_ 1002 VC_RKE_PRSNT "VehCfg3_Pkt";
BA_ "FlexKomSigLaenge" SG_ 1002 VC_RKE_PRSNT 64;
BA_ "FlexKomSID" SG_ 1002 VC_RKE_PRSNT 888;
BA_ "FlexKomIsMotorola" SG_ 1002 VC_RKE_PRSNT 1;
BA_ "FlexKomComment" SG_ 1002 VC_RKE_PRSNT "Vehicle Configuration 3 Packet";
BA_ "GenSigTimeout_IC" SG_ 1002 VC_SPORT_PRSNT 21000;
BA_ "GenSigSNA" SG_ 1002 VC_SPORT_PRSNT "0h";
BA_ "GenSigSendType" SG_ 1002 VC_SPORT_PRSNT 5;
BA_ "GenSigCycleTime" SG_ 1002 VC_SPORT_PRSNT 2000;
BA_ "FlexKomSigStartValue" SG_ 1002 VC_SPORT_PRSNT "0370FF037FFF0000h";
BA_ "FlexKomSigStartPos" SG_ 1002 VC_SPORT_PRSNT 7;
BA_ "FlexKomSigName" SG_ 1002 VC_SPORT_PRSNT "VehCfg3_Pkt";
BA_ "FlexKomSigLaenge" SG_ 1002 VC_SPORT_PRSNT 64;
BA_ "FlexKomSID" SG_ 1002 VC_SPORT_PRSNT 888;
BA_ "FlexKomIsMotorola" SG_ 1002 VC_SPORT_PRSNT 1;
BA_ "FlexKomComment" SG_ 1002 VC_SPORT_PRSNT "Vehicle Configuration 3 Packet";
BA_ "GenSigTimeout_TPM" SG_ 1002 VC_SRT_PRSNT 21000;
BA_ "GenSigTimeout_ORC" SG_ 1002 VC_SRT_PRSNT 7000;
BA_ "GenSigTimeout_IC" SG_ 1002 VC_SRT_PRSNT 21000;
BA_ "GenSigSNA" SG_ 1002 VC_SRT_PRSNT "0h";
BA_ "GenSigSendType" SG_ 1002 VC_SRT_PRSNT 5;
BA_ "GenSigCycleTime" SG_ 1002 VC_SRT_PRSNT 2000;
BA_ "FlexKomSigStartValue" SG_ 1002 VC_SRT_PRSNT "0370FF037FFF0000h";
BA_ "FlexKomSigStartPos" SG_ 1002 VC_SRT_PRSNT 7;
BA_ "FlexKomSigName" SG_ 1002 VC_SRT_PRSNT "VehCfg3_Pkt";
BA_ "FlexKomSigLaenge" SG_ 1002 VC_SRT_PRSNT 64;
BA_ "FlexKomSID" SG_ 1002 VC_SRT_PRSNT 888;
BA_ "FlexKomIsMotorola" SG_ 1002 VC_SRT_PRSNT 1;
BA_ "FlexKomComment" SG_ 1002 VC_SRT_PRSNT "Vehicle Configuration 3 Packet";
BA_ "GenSigSNA" SG_ 1002 VC_SecLkPrsnt "0h";
BA_ "GenSigSendType" SG_ 1002 VC_SecLkPrsnt 5;
BA_ "GenSigCycleTime" SG_ 1002 VC_SecLkPrsnt 2000;
BA_ "FlexKomSigStartValue" SG_ 1002 VC_SecLkPrsnt "0370FF037FFF0000h";
BA_ "FlexKomSigStartPos" SG_ 1002 VC_SecLkPrsnt 7;
BA_ "FlexKomSigName" SG_ 1002 VC_SecLkPrsnt "VehCfg3_Pkt";
BA_ "FlexKomSigLaenge" SG_ 1002 VC_SecLkPrsnt 64;
BA_ "FlexKomSID" SG_ 1002 VC_SecLkPrsnt 888;
BA_ "FlexKomIsMotorola" SG_ 1002 VC_SecLkPrsnt 1;
BA_ "FlexKomComment" SG_ 1002 VC_SecLkPrsnt "Vehicle Configuration 3 Packet";
BA_ "GenSigSNA" SG_ 1002 VC_SunShade_Present "0h";
BA_ "GenSigSendType" SG_ 1002 VC_SunShade_Present 5;
BA_ "GenSigCycleTime" SG_ 1002 VC_SunShade_Present 2000;
BA_ "FlexKomSigStartValue" SG_ 1002 VC_SunShade_Present "0370FF037FFF0000h";
BA_ "FlexKomSigStartPos" SG_ 1002 VC_SunShade_Present 7;
BA_ "FlexKomSigName" SG_ 1002 VC_SunShade_Present "VehCfg3_Pkt";
BA_ "FlexKomSigLaenge" SG_ 1002 VC_SunShade_Present 64;
BA_ "FlexKomSID" SG_ 1002 VC_SunShade_Present 888;
BA_ "FlexKomIsMotorola" SG_ 1002 VC_SunShade_Present 1;
BA_ "FlexKomComment" SG_ 1002 VC_SunShade_Present "Vehicle Configuration 3 Packet";
BA_ "GenSigTimeout_IC" SG_ 1002 VC_TEMP_DISP 21000;
BA_ "GenSigSNA" SG_ 1002 VC_TEMP_DISP "0h";
BA_ "GenSigSendType" SG_ 1002 VC_TEMP_DISP 5;
BA_ "GenSigCycleTime" SG_ 1002 VC_TEMP_DISP 2000;
BA_ "FlexKomSigStartValue" SG_ 1002 VC_TEMP_DISP "0370FF037FFF0000h";
BA_ "FlexKomSigStartPos" SG_ 1002 VC_TEMP_DISP 7;
BA_ "FlexKomSigName" SG_ 1002 VC_TEMP_DISP "VehCfg3_Pkt";
BA_ "FlexKomSigLaenge" SG_ 1002 VC_TEMP_DISP 64;
BA_ "FlexKomSID" SG_ 1002 VC_TEMP_DISP 888;
BA_ "FlexKomIsMotorola" SG_ 1002 VC_TEMP_DISP 1;
BA_ "FlexKomComment" SG_ 1002 VC_TEMP_DISP "Vehicle Configuration 3 Packet";
BA_ "GenSigSNA" SG_ 1002 VC_TcaseTyp "0h";
BA_ "GenSigSendType" SG_ 1002 VC_TcaseTyp 5;
BA_ "GenSigCycleTime" SG_ 1002 VC_TcaseTyp 2000;
BA_ "FlexKomSigStartValue" SG_ 1002 VC_TcaseTyp "0370FF037FFF0000h";
BA_ "FlexKomSigStartPos" SG_ 1002 VC_TcaseTyp 7;
BA_ "FlexKomSigName" SG_ 1002 VC_TcaseTyp "VehCfg3_Pkt";
BA_ "FlexKomSigLaenge" SG_ 1002 VC_TcaseTyp 64;
BA_ "FlexKomSID" SG_ 1002 VC_TcaseTyp 888;
BA_ "FlexKomIsMotorola" SG_ 1002 VC_TcaseTyp 1;
BA_ "FlexKomComment" SG_ 1002 VC_TcaseTyp "Vehicle Configuration 3 Packet";
BA_ "GenSigTimeout_TPM" SG_ 1002 VC_VEH_BRAND 21000;
BA_ "GenSigTimeout_IC" SG_ 1002 VC_VEH_BRAND 21000;
BA_ "GenSigStartValue" SG_ 1002 VC_VEH_BRAND 15;
BA_ "GenSigSNA" SG_ 1002 VC_VEH_BRAND "Fh";
BA_ "GenSigSendType" SG_ 1002 VC_VEH_BRAND 5;
BA_ "GenSigCycleTime" SG_ 1002 VC_VEH_BRAND 2000;
BA_ "FlexKomSigStartValue" SG_ 1002 VC_VEH_BRAND "0370FF037FFF0000h";
BA_ "FlexKomSigStartPos" SG_ 1002 VC_VEH_BRAND 7;
BA_ "FlexKomSigName" SG_ 1002 VC_VEH_BRAND "VehCfg3_Pkt";
BA_ "FlexKomSigLaenge" SG_ 1002 VC_VEH_BRAND 64;
BA_ "FlexKomSID" SG_ 1002 VC_VEH_BRAND 888;
BA_ "FlexKomIsMotorola" SG_ 1002 VC_VEH_BRAND 1;
BA_ "FlexKomComment" SG_ 1002 VC_VEH_BRAND "Vehicle Configuration 3 Packet";
BA_ "GenSigTimeout_TPM" SG_ 1002 VC_VehCfg3_Stat 21000;
BA_ "GenSigTimeout_ORC" SG_ 1002 VC_VehCfg3_Stat 7000;
BA_ "GenSigTimeout_IC" SG_ 1002 VC_VehCfg3_Stat 21000;
BA_ "GenSigTimeout_EHPS" SG_ 1002 VC_VehCfg3_Stat 21000;
BA_ "GenSigStartValue" SG_ 1002 VC_VehCfg3_Stat 3;
BA_ "GenSigSNA" SG_ 1002 VC_VehCfg3_Stat "3h";
BA_ "GenSigSendType" SG_ 1002 VC_VehCfg3_Stat 5;
BA_ "GenSigCycleTime" SG_ 1002 VC_VehCfg3_Stat 2000;
BA_ "FlexKomSigStartValue" SG_ 1002 VC_VehCfg3_Stat "0370FF037FFF0000h";
BA_ "FlexKomSigStartPos" SG_ 1002 VC_VehCfg3_Stat 7;
BA_ "FlexKomSigName" SG_ 1002 VC_VehCfg3_Stat "VehCfg3_Pkt";
BA_ "FlexKomSigLaenge" SG_ 1002 VC_VehCfg3_Stat 64;
BA_ "FlexKomSID" SG_ 1002 VC_VehCfg3_Stat 888;
BA_ "FlexKomIsMotorola" SG_ 1002 VC_VehCfg3_Stat 1;
BA_ "FlexKomComment" SG_ 1002 VC_VehCfg3_Stat "Vehicle Configuration 3 Packet";
BA_ "GenSigTimeout_ORC" SG_ 1002 VC_WHL_BASE 7000;
BA_ "GenSigStartValue" SG_ 1002 VC_WHL_BASE 3;
BA_ "GenSigSNA" SG_ 1002 VC_WHL_BASE "3h";
BA_ "GenSigSendType" SG_ 1002 VC_WHL_BASE 5;
BA_ "GenSigCycleTime" SG_ 1002 VC_WHL_BASE 2000;
BA_ "FlexKomSigStartValue" SG_ 1002 VC_WHL_BASE "0370FF037FFF0000h";
BA_ "FlexKomSigStartPos" SG_ 1002 VC_WHL_BASE 7;
BA_ "FlexKomSigName" SG_ 1002 VC_WHL_BASE "VehCfg3_Pkt";
BA_ "FlexKomSigLaenge" SG_ 1002 VC_WHL_BASE 64;
BA_ "FlexKomSID" SG_ 1002 VC_WHL_BASE 888;
BA_ "FlexKomIsMotorola" SG_ 1002 VC_WHL_BASE 1;
BA_ "FlexKomComment" SG_ 1002 VC_WHL_BASE "Vehicle Configuration 3 Packet";
BA_ "GenSigStartValue" SG_ 1002 VC_WIN_EXPR_FEAT 3;
BA_ "GenSigSNA" SG_ 1002 VC_WIN_EXPR_FEAT "3h";
BA_ "GenSigSendType" SG_ 1002 VC_WIN_EXPR_FEAT 5;
BA_ "GenSigCycleTime" SG_ 1002 VC_WIN_EXPR_FEAT 2000;
BA_ "FlexKomSigStartValue" SG_ 1002 VC_WIN_EXPR_FEAT "0370FF037FFF0000h";
BA_ "FlexKomSigStartPos" SG_ 1002 VC_WIN_EXPR_FEAT 7;
BA_ "FlexKomSigName" SG_ 1002 VC_WIN_EXPR_FEAT "VehCfg3_Pkt";
BA_ "FlexKomSigLaenge" SG_ 1002 VC_WIN_EXPR_FEAT 64;
BA_ "FlexKomSID" SG_ 1002 VC_WIN_EXPR_FEAT 888;
BA_ "FlexKomIsMotorola" SG_ 1002 VC_WIN_EXPR_FEAT 1;
BA_ "FlexKomComment" SG_ 1002 VC_WIN_EXPR_FEAT "Vehicle Configuration 3 Packet";
BA_ "GenSigTimeout_TCM" SG_ 1003 VC_AXLE_RATIO 3500;
BA_ "GenSigStartValue" SG_ 1003 VC_AXLE_RATIO 65535;
BA_ "GenSigSNA" SG_ 1003 VC_AXLE_RATIO "FFFFh";
BA_ "GenSigSendType" SG_ 1003 VC_AXLE_RATIO 5;
BA_ "GenSigCycleTime" SG_ 1003 VC_AXLE_RATIO 1000;
BA_ "FlexKomSigStartValue" SG_ 1003 VC_AXLE_RATIO "FFFFFFFFFFFFFFFFh";
BA_ "FlexKomSigStartPos" SG_ 1003 VC_AXLE_RATIO 7;
BA_ "FlexKomSigName" SG_ 1003 VC_AXLE_RATIO "VehCfg4_Pkt";
BA_ "FlexKomSigLaenge" SG_ 1003 VC_AXLE_RATIO 64;
BA_ "FlexKomSID" SG_ 1003 VC_AXLE_RATIO 1035;
BA_ "FlexKomIsMotorola" SG_ 1003 VC_AXLE_RATIO 1;
BA_ "FlexKomComment" SG_ 1003 VC_AXLE_RATIO "Vehicle Configuration 4 Packet";
BA_ "GenSigTimeout_TCM" SG_ 1003 VC_TCASE_HI_RATIO 3500;
BA_ "GenSigStartValue" SG_ 1003 VC_TCASE_HI_RATIO 16383;
BA_ "GenSigSNA" SG_ 1003 VC_TCASE_HI_RATIO "3FFFh";
BA_ "GenSigSendType" SG_ 1003 VC_TCASE_HI_RATIO 5;
BA_ "GenSigCycleTime" SG_ 1003 VC_TCASE_HI_RATIO 1000;
BA_ "FlexKomSigStartValue" SG_ 1003 VC_TCASE_HI_RATIO "FFFFFFFFFFFFFFFFh";
BA_ "FlexKomSigStartPos" SG_ 1003 VC_TCASE_HI_RATIO 7;
BA_ "FlexKomSigName" SG_ 1003 VC_TCASE_HI_RATIO "VehCfg4_Pkt";
BA_ "FlexKomSigLaenge" SG_ 1003 VC_TCASE_HI_RATIO 64;
BA_ "FlexKomSID" SG_ 1003 VC_TCASE_HI_RATIO 1035;
BA_ "FlexKomIsMotorola" SG_ 1003 VC_TCASE_HI_RATIO 1;
BA_ "FlexKomComment" SG_ 1003 VC_TCASE_HI_RATIO "Vehicle Configuration 4 Packet";
BA_ "GenSigTimeout_TCM" SG_ 1003 VC_TCASE_LO_RATIO 3500;
BA_ "GenSigStartValue" SG_ 1003 VC_TCASE_LO_RATIO 65535;
BA_ "GenSigSNA" SG_ 1003 VC_TCASE_LO_RATIO "FFFFh";
BA_ "GenSigSendType" SG_ 1003 VC_TCASE_LO_RATIO 5;
BA_ "GenSigCycleTime" SG_ 1003 VC_TCASE_LO_RATIO 1000;
BA_ "FlexKomSigStartValue" SG_ 1003 VC_TCASE_LO_RATIO "FFFFFFFFFFFFFFFFh";
BA_ "FlexKomSigStartPos" SG_ 1003 VC_TCASE_LO_RATIO 7;
BA_ "FlexKomSigName" SG_ 1003 VC_TCASE_LO_RATIO "VehCfg4_Pkt";
BA_ "FlexKomSigLaenge" SG_ 1003 VC_TCASE_LO_RATIO 64;
BA_ "FlexKomSID" SG_ 1003 VC_TCASE_LO_RATIO 1035;
BA_ "FlexKomIsMotorola" SG_ 1003 VC_TCASE_LO_RATIO 1;
BA_ "FlexKomComment" SG_ 1003 VC_TCASE_LO_RATIO "Vehicle Configuration 4 Packet";
BA_ "GenSigTimeout_ORC" SG_ 1003 VC_TIRE_CIRCUMF 3500;
BA_ "GenSigTimeout_EHPS" SG_ 1003 VC_TIRE_CIRCUMF 10500;
BA_ "GenSigTimeout_DTCM" SG_ 1003 VC_TIRE_CIRCUMF 5500;
BA_ "GenSigStartValue" SG_ 1003 VC_TIRE_CIRCUMF 65535;
BA_ "GenSigSNA" SG_ 1003 VC_TIRE_CIRCUMF "FFFFh";
BA_ "GenSigSendType" SG_ 1003 VC_TIRE_CIRCUMF 5;
BA_ "GenSigCycleTime" SG_ 1003 VC_TIRE_CIRCUMF 1000;
BA_ "FlexKomSigStartValue" SG_ 1003 VC_TIRE_CIRCUMF "FFFFFFFFFFFFFFFFh";
BA_ "FlexKomSigStartPos" SG_ 1003 VC_TIRE_CIRCUMF 7;
BA_ "FlexKomSigName" SG_ 1003 VC_TIRE_CIRCUMF "VehCfg4_Pkt";
BA_ "FlexKomSigLaenge" SG_ 1003 VC_TIRE_CIRCUMF 64;
BA_ "FlexKomSID" SG_ 1003 VC_TIRE_CIRCUMF 1035;
BA_ "FlexKomIsMotorola" SG_ 1003 VC_TIRE_CIRCUMF 1;
BA_ "FlexKomComment" SG_ 1003 VC_TIRE_CIRCUMF "Vehicle Configuration 4 Packet";
BA_ "GenSigTimeout_RF_HUB" SG_ 1003 VC_VehCfg4_Stat 10500;
BA_ "GenSigTimeout_ORC" SG_ 1003 VC_VehCfg4_Stat 3500;
BA_ "GenSigTimeout_EHPS" SG_ 1003 VC_VehCfg4_Stat 10500;
BA_ "GenSigStartValue" SG_ 1003 VC_VehCfg4_Stat 3;
BA_ "GenSigSNA" SG_ 1003 VC_VehCfg4_Stat "3h";
BA_ "GenSigSendType" SG_ 1003 VC_VehCfg4_Stat 5;
BA_ "GenSigCycleTime" SG_ 1003 VC_VehCfg4_Stat 1000;
BA_ "FlexKomSigStartValue" SG_ 1003 VC_VehCfg4_Stat "FFFFFFFFFFFFFFFFh";
BA_ "FlexKomSigStartPos" SG_ 1003 VC_VehCfg4_Stat 7;
BA_ "FlexKomSigName" SG_ 1003 VC_VehCfg4_Stat "VehCfg4_Pkt";
BA_ "FlexKomSigLaenge" SG_ 1003 VC_VehCfg4_Stat 64;
BA_ "FlexKomSID" SG_ 1003 VC_VehCfg4_Stat 1035;
BA_ "FlexKomIsMotorola" SG_ 1003 VC_VehCfg4_Stat 1;
BA_ "FlexKomComment" SG_ 1003 VC_VehCfg4_Stat "Vehicle Configuration 4 Packet";
BA_ "GenSigTimeout_IC" SG_ 1098 VC_AmbLtgPrsnt 21000;
BA_ "GenSigSNA" SG_ 1098 VC_AmbLtgPrsnt "0h";
BA_ "GenSigSendType" SG_ 1098 VC_AmbLtgPrsnt 5;
BA_ "GenSigCycleTime" SG_ 1098 VC_AmbLtgPrsnt 2000;
BA_ "FlexKomSigStartValue" SG_ 1098 VC_AmbLtgPrsnt "C3FFFFFFFFFFFF00h";
BA_ "FlexKomSigStartPos" SG_ 1098 VC_AmbLtgPrsnt 7;
BA_ "FlexKomSigName" SG_ 1098 VC_AmbLtgPrsnt "VehCfg5_Pkt";
BA_ "FlexKomSigLaenge" SG_ 1098 VC_AmbLtgPrsnt 64;
BA_ "FlexKomSID" SG_ 1098 VC_AmbLtgPrsnt 1198;
BA_ "FlexKomIsMotorola" SG_ 1098 VC_AmbLtgPrsnt 1;
BA_ "FlexKomComment" SG_ 1098 VC_AmbLtgPrsnt "Vehicle Configuration 5 Packet";
BA_ "GenSigStartValue" SG_ 1098 VC_AmbTempLct 3;
BA_ "GenSigSNA" SG_ 1098 VC_AmbTempLct "3h";
BA_ "GenSigSendType" SG_ 1098 VC_AmbTempLct 5;
BA_ "GenSigCycleTime" SG_ 1098 VC_AmbTempLct 2000;
BA_ "FlexKomSigStartValue" SG_ 1098 VC_AmbTempLct "C3FFFFFFFFFFFF00h";
BA_ "FlexKomSigStartPos" SG_ 1098 VC_AmbTempLct 7;
BA_ "FlexKomSigName" SG_ 1098 VC_AmbTempLct "VehCfg5_Pkt";
BA_ "FlexKomSigLaenge" SG_ 1098 VC_AmbTempLct 64;
BA_ "FlexKomSID" SG_ 1098 VC_AmbTempLct 1198;
BA_ "FlexKomIsMotorola" SG_ 1098 VC_AmbTempLct 1;
BA_ "FlexKomComment" SG_ 1098 VC_AmbTempLct "Vehicle Configuration 5 Packet";
BA_ "GenSigTimeout_ORC" SG_ 1098 VC_ChildDisp_Prsnt 7000;
BA_ "GenSigTimeout_IC" SG_ 1098 VC_ChildDisp_Prsnt 21000;
BA_ "GenSigSNA" SG_ 1098 VC_ChildDisp_Prsnt "0h";
BA_ "GenSigSendType" SG_ 1098 VC_ChildDisp_Prsnt 5;
BA_ "GenSigCycleTime" SG_ 1098 VC_ChildDisp_Prsnt 2000;
BA_ "FlexKomSigStartValue" SG_ 1098 VC_ChildDisp_Prsnt "C3FFFFFFFFFFFF00h";
BA_ "FlexKomSigStartPos" SG_ 1098 VC_ChildDisp_Prsnt 7;
BA_ "FlexKomSigName" SG_ 1098 VC_ChildDisp_Prsnt "VehCfg5_Pkt";
BA_ "FlexKomSigLaenge" SG_ 1098 VC_ChildDisp_Prsnt 64;
BA_ "FlexKomSID" SG_ 1098 VC_ChildDisp_Prsnt 1198;
BA_ "FlexKomIsMotorola" SG_ 1098 VC_ChildDisp_Prsnt 1;
BA_ "FlexKomComment" SG_ 1098 VC_ChildDisp_Prsnt "Vehicle Configuration 5 Packet";
BA_ "GenSigSNA" SG_ 1098 VC_LUCI_PRSNT "0h";
BA_ "GenSigSendType" SG_ 1098 VC_LUCI_PRSNT 5;
BA_ "GenSigCycleTime" SG_ 1098 VC_LUCI_PRSNT 2000;
BA_ "FlexKomSigStartValue" SG_ 1098 VC_LUCI_PRSNT "C3FFFFFFFFFFFF00h";
BA_ "FlexKomSigStartPos" SG_ 1098 VC_LUCI_PRSNT 7;
BA_ "FlexKomSigName" SG_ 1098 VC_LUCI_PRSNT "VehCfg5_Pkt";
BA_ "FlexKomSigLaenge" SG_ 1098 VC_LUCI_PRSNT 64;
BA_ "FlexKomSID" SG_ 1098 VC_LUCI_PRSNT 1198;
BA_ "FlexKomIsMotorola" SG_ 1098 VC_LUCI_PRSNT 1;
BA_ "FlexKomComment" SG_ 1098 VC_LUCI_PRSNT "Vehicle Configuration 5 Packet";
BA_ "GenSigTimeout_IC" SG_ 1098 VC_NonReg_TPIS 21000;
BA_ "GenSigSNA" SG_ 1098 VC_NonReg_TPIS "0h";
BA_ "GenSigSendType" SG_ 1098 VC_NonReg_TPIS 5;
BA_ "GenSigCycleTime" SG_ 1098 VC_NonReg_TPIS 2000;
BA_ "FlexKomSigStartValue" SG_ 1098 VC_NonReg_TPIS "C3FFFFFFFFFFFF00h";
BA_ "FlexKomSigStartPos" SG_ 1098 VC_NonReg_TPIS 7;
BA_ "FlexKomSigName" SG_ 1098 VC_NonReg_TPIS "VehCfg5_Pkt";
BA_ "FlexKomSigLaenge" SG_ 1098 VC_NonReg_TPIS 64;
BA_ "FlexKomSID" SG_ 1098 VC_NonReg_TPIS 1198;
BA_ "FlexKomIsMotorola" SG_ 1098 VC_NonReg_TPIS 1;
BA_ "FlexKomComment" SG_ 1098 VC_NonReg_TPIS "Vehicle Configuration 5 Packet";
BA_ "GenSigTimeout_IC" SG_ 1098 VC_OffRoadPg 21000;
BA_ "GenSigSNA" SG_ 1098 VC_OffRoadPg "0h";
BA_ "GenSigSendType" SG_ 1098 VC_OffRoadPg 5;
BA_ "GenSigCycleTime" SG_ 1098 VC_OffRoadPg 2000;
BA_ "FlexKomSigStartValue" SG_ 1098 VC_OffRoadPg "C3FFFFFFFFFFFF00h";
BA_ "FlexKomSigStartPos" SG_ 1098 VC_OffRoadPg 7;
BA_ "FlexKomSigName" SG_ 1098 VC_OffRoadPg "VehCfg5_Pkt";
BA_ "FlexKomSigLaenge" SG_ 1098 VC_OffRoadPg 64;
BA_ "FlexKomSID" SG_ 1098 VC_OffRoadPg 1198;
BA_ "FlexKomIsMotorola" SG_ 1098 VC_OffRoadPg 1;
BA_ "FlexKomComment" SG_ 1098 VC_OffRoadPg "Vehicle Configuration 5 Packet";
BA_ "GenSigTimeout_PTS" SG_ 1098 VC_PPPA_Prsnt 21000;
BA_ "GenSigTimeout_IC" SG_ 1098 VC_PPPA_Prsnt 21000;
BA_ "GenSigSNA" SG_ 1098 VC_PPPA_Prsnt "0h";
BA_ "GenSigSendType" SG_ 1098 VC_PPPA_Prsnt 5;
BA_ "GenSigCycleTime" SG_ 1098 VC_PPPA_Prsnt 2000;
BA_ "FlexKomSigStartValue" SG_ 1098 VC_PPPA_Prsnt "C3FFFFFFFFFFFF00h";
BA_ "FlexKomSigStartPos" SG_ 1098 VC_PPPA_Prsnt 7;
BA_ "FlexKomSigName" SG_ 1098 VC_PPPA_Prsnt "VehCfg5_Pkt";
BA_ "FlexKomSigLaenge" SG_ 1098 VC_PPPA_Prsnt 64;
BA_ "FlexKomSID" SG_ 1098 VC_PPPA_Prsnt 1198;
BA_ "FlexKomIsMotorola" SG_ 1098 VC_PPPA_Prsnt 1;
BA_ "FlexKomComment" SG_ 1098 VC_PPPA_Prsnt "Vehicle Configuration 5 Packet";
BA_ "GenSigTimeout_PTS" SG_ 1098 VC_ParkStopPrsnt 21000;
BA_ "GenSigSNA" SG_ 1098 VC_ParkStopPrsnt "0h";
BA_ "GenSigSendType" SG_ 1098 VC_ParkStopPrsnt 5;
BA_ "GenSigCycleTime" SG_ 1098 VC_ParkStopPrsnt 2000;
BA_ "FlexKomSigStartValue" SG_ 1098 VC_ParkStopPrsnt "C3FFFFFFFFFFFF00h";
BA_ "FlexKomSigStartPos" SG_ 1098 VC_ParkStopPrsnt 7;
BA_ "FlexKomSigName" SG_ 1098 VC_ParkStopPrsnt "VehCfg5_Pkt";
BA_ "FlexKomSigLaenge" SG_ 1098 VC_ParkStopPrsnt 64;
BA_ "FlexKomSID" SG_ 1098 VC_ParkStopPrsnt 1198;
BA_ "FlexKomIsMotorola" SG_ 1098 VC_ParkStopPrsnt 1;
BA_ "FlexKomComment" SG_ 1098 VC_ParkStopPrsnt "Vehicle Configuration 5 Packet";
BA_ "GenSigTimeout_IC" SG_ 1098 VC_RR_DuallyPrsnt 21000;
BA_ "GenSigSNA" SG_ 1098 VC_RR_DuallyPrsnt "0h";
BA_ "GenSigSendType" SG_ 1098 VC_RR_DuallyPrsnt 5;
BA_ "GenSigCycleTime" SG_ 1098 VC_RR_DuallyPrsnt 2000;
BA_ "FlexKomSigStartValue" SG_ 1098 VC_RR_DuallyPrsnt "C3FFFFFFFFFFFF00h";
BA_ "FlexKomSigStartPos" SG_ 1098 VC_RR_DuallyPrsnt 7;
BA_ "FlexKomSigName" SG_ 1098 VC_RR_DuallyPrsnt "VehCfg5_Pkt";
BA_ "FlexKomSigLaenge" SG_ 1098 VC_RR_DuallyPrsnt 64;
BA_ "FlexKomSID" SG_ 1098 VC_RR_DuallyPrsnt 1198;
BA_ "FlexKomIsMotorola" SG_ 1098 VC_RR_DuallyPrsnt 1;
BA_ "FlexKomComment" SG_ 1098 VC_RR_DuallyPrsnt "Vehicle Configuration 5 Packet";
BA_ "GenSigSNA" SG_ 1098 VC_RearDoorLocks2DCM "0h";
BA_ "GenSigSendType" SG_ 1098 VC_RearDoorLocks2DCM 5;
BA_ "GenSigCycleTime" SG_ 1098 VC_RearDoorLocks2DCM 2000;
BA_ "FlexKomSigStartValue" SG_ 1098 VC_RearDoorLocks2DCM "C3FFFFFFFFFFFF00h";
BA_ "FlexKomSigStartPos" SG_ 1098 VC_RearDoorLocks2DCM 7;
BA_ "FlexKomSigName" SG_ 1098 VC_RearDoorLocks2DCM "VehCfg5_Pkt";
BA_ "FlexKomSigLaenge" SG_ 1098 VC_RearDoorLocks2DCM 64;
BA_ "FlexKomSID" SG_ 1098 VC_RearDoorLocks2DCM 1198;
BA_ "FlexKomIsMotorola" SG_ 1098 VC_RearDoorLocks2DCM 1;
BA_ "FlexKomComment" SG_ 1098 VC_RearDoorLocks2DCM "Vehicle Configuration 5 Packet";
BA_ "GenSigTimeout_ORC" SG_ 1098 VC_SBR_Prsnt 7000;
BA_ "GenSigTimeout_IC" SG_ 1098 VC_SBR_Prsnt 21000;
BA_ "GenSigSNA" SG_ 1098 VC_SBR_Prsnt "0h";
BA_ "GenSigSendType" SG_ 1098 VC_SBR_Prsnt 5;
BA_ "GenSigCycleTime" SG_ 1098 VC_SBR_Prsnt 2000;
BA_ "FlexKomSigStartValue" SG_ 1098 VC_SBR_Prsnt "C3FFFFFFFFFFFF00h";
BA_ "FlexKomSigStartPos" SG_ 1098 VC_SBR_Prsnt 7;
BA_ "FlexKomSigName" SG_ 1098 VC_SBR_Prsnt "VehCfg5_Pkt";
BA_ "FlexKomSigLaenge" SG_ 1098 VC_SBR_Prsnt 64;
BA_ "FlexKomSID" SG_ 1098 VC_SBR_Prsnt 1198;
BA_ "FlexKomIsMotorola" SG_ 1098 VC_SBR_Prsnt 1;
BA_ "FlexKomComment" SG_ 1098 VC_SBR_Prsnt "Vehicle Configuration 5 Packet";
BA_ "GenSigTimeout_ORC" SG_ 1098 VC_SpdLmt_PRSNT 7000;
BA_ "GenSigTimeout_IC" SG_ 1098 VC_SpdLmt_PRSNT 21000;
BA_ "GenSigSNA" SG_ 1098 VC_SpdLmt_PRSNT "0h";
BA_ "GenSigSendType" SG_ 1098 VC_SpdLmt_PRSNT 5;
BA_ "GenSigCycleTime" SG_ 1098 VC_SpdLmt_PRSNT 2000;
BA_ "FlexKomSigStartValue" SG_ 1098 VC_SpdLmt_PRSNT "C3FFFFFFFFFFFF00h";
BA_ "FlexKomSigStartPos" SG_ 1098 VC_SpdLmt_PRSNT 7;
BA_ "FlexKomSigName" SG_ 1098 VC_SpdLmt_PRSNT "VehCfg5_Pkt";
BA_ "FlexKomSigLaenge" SG_ 1098 VC_SpdLmt_PRSNT 64;
BA_ "FlexKomSID" SG_ 1098 VC_SpdLmt_PRSNT 1198;
BA_ "FlexKomIsMotorola" SG_ 1098 VC_SpdLmt_PRSNT 1;
BA_ "FlexKomComment" SG_ 1098 VC_SpdLmt_PRSNT "Vehicle Configuration 5 Packet";
BA_ "GenSigStartValue" SG_ 1098 VC_Strng_Rt_0 255;
BA_ "GenSigSNA" SG_ 1098 VC_Strng_Rt_0 "FFh";
BA_ "GenSigSendType" SG_ 1098 VC_Strng_Rt_0 5;
BA_ "GenSigCycleTime" SG_ 1098 VC_Strng_Rt_0 2000;
BA_ "FlexKomSigStartValue" SG_ 1098 VC_Strng_Rt_0 "C3FFFFFFFFFFFF00h";
BA_ "FlexKomSigStartPos" SG_ 1098 VC_Strng_Rt_0 7;
BA_ "FlexKomSigName" SG_ 1098 VC_Strng_Rt_0 "VehCfg5_Pkt";
BA_ "FlexKomSigLaenge" SG_ 1098 VC_Strng_Rt_0 64;
BA_ "FlexKomSID" SG_ 1098 VC_Strng_Rt_0 1198;
BA_ "FlexKomIsMotorola" SG_ 1098 VC_Strng_Rt_0 1;
BA_ "FlexKomComment" SG_ 1098 VC_Strng_Rt_0 "Vehicle Configuration 5 Packet";
BA_ "GenSigStartValue" SG_ 1098 VC_Strng_Rt_pls1 255;
BA_ "GenSigSNA" SG_ 1098 VC_Strng_Rt_pls1 "FFh";
BA_ "GenSigSendType" SG_ 1098 VC_Strng_Rt_pls1 5;
BA_ "GenSigCycleTime" SG_ 1098 VC_Strng_Rt_pls1 2000;
BA_ "FlexKomSigStartValue" SG_ 1098 VC_Strng_Rt_pls1 "C3FFFFFFFFFFFF00h";
BA_ "FlexKomSigStartPos" SG_ 1098 VC_Strng_Rt_pls1 7;
BA_ "FlexKomSigName" SG_ 1098 VC_Strng_Rt_pls1 "VehCfg5_Pkt";
BA_ "FlexKomSigLaenge" SG_ 1098 VC_Strng_Rt_pls1 64;
BA_ "FlexKomSID" SG_ 1098 VC_Strng_Rt_pls1 1198;
BA_ "FlexKomIsMotorola" SG_ 1098 VC_Strng_Rt_pls1 1;
BA_ "FlexKomComment" SG_ 1098 VC_Strng_Rt_pls1 "Vehicle Configuration 5 Packet";
BA_ "GenSigStartValue" SG_ 1098 VC_Strng_Rt_pls2 255;
BA_ "GenSigSNA" SG_ 1098 VC_Strng_Rt_pls2 "FFh";
BA_ "GenSigSendType" SG_ 1098 VC_Strng_Rt_pls2 5;
BA_ "GenSigCycleTime" SG_ 1098 VC_Strng_Rt_pls2 2000;
BA_ "FlexKomSigStartValue" SG_ 1098 VC_Strng_Rt_pls2 "C3FFFFFFFFFFFF00h";
BA_ "FlexKomSigStartPos" SG_ 1098 VC_Strng_Rt_pls2 7;
BA_ "FlexKomSigName" SG_ 1098 VC_Strng_Rt_pls2 "VehCfg5_Pkt";
BA_ "FlexKomSigLaenge" SG_ 1098 VC_Strng_Rt_pls2 64;
BA_ "FlexKomSID" SG_ 1098 VC_Strng_Rt_pls2 1198;
BA_ "FlexKomIsMotorola" SG_ 1098 VC_Strng_Rt_pls2 1;
BA_ "FlexKomComment" SG_ 1098 VC_Strng_Rt_pls2 "Vehicle Configuration 5 Packet";
BA_ "GenSigStartValue" SG_ 1098 VC_Strng_Rt_pls3 255;
BA_ "GenSigSNA" SG_ 1098 VC_Strng_Rt_pls3 "FFh";
BA_ "GenSigSendType" SG_ 1098 VC_Strng_Rt_pls3 5;
BA_ "GenSigCycleTime" SG_ 1098 VC_Strng_Rt_pls3 2000;
BA_ "FlexKomSigStartValue" SG_ 1098 VC_Strng_Rt_pls3 "C3FFFFFFFFFFFF00h";
BA_ "FlexKomSigStartPos" SG_ 1098 VC_Strng_Rt_pls3 7;
BA_ "FlexKomSigName" SG_ 1098 VC_Strng_Rt_pls3 "VehCfg5_Pkt";
BA_ "FlexKomSigLaenge" SG_ 1098 VC_Strng_Rt_pls3 64;
BA_ "FlexKomSID" SG_ 1098 VC_Strng_Rt_pls3 1198;
BA_ "FlexKomIsMotorola" SG_ 1098 VC_Strng_Rt_pls3 1;
BA_ "FlexKomComment" SG_ 1098 VC_Strng_Rt_pls3 "Vehicle Configuration 5 Packet";
BA_ "GenSigStartValue" SG_ 1098 VC_Strng_Rt_pls4 255;
BA_ "GenSigSNA" SG_ 1098 VC_Strng_Rt_pls4 "FFh";
BA_ "GenSigSendType" SG_ 1098 VC_Strng_Rt_pls4 5;
BA_ "GenSigCycleTime" SG_ 1098 VC_Strng_Rt_pls4 2000;
BA_ "FlexKomSigStartValue" SG_ 1098 VC_Strng_Rt_pls4 "C3FFFFFFFFFFFF00h";
BA_ "FlexKomSigStartPos" SG_ 1098 VC_Strng_Rt_pls4 7;
BA_ "FlexKomSigName" SG_ 1098 VC_Strng_Rt_pls4 "VehCfg5_Pkt";
BA_ "FlexKomSigLaenge" SG_ 1098 VC_Strng_Rt_pls4 64;
BA_ "FlexKomSID" SG_ 1098 VC_Strng_Rt_pls4 1198;
BA_ "FlexKomIsMotorola" SG_ 1098 VC_Strng_Rt_pls4 1;
BA_ "FlexKomComment" SG_ 1098 VC_Strng_Rt_pls4 "Vehicle Configuration 5 Packet";
BA_ "GenSigStartValue" SG_ 1098 VC_Strng_Rt_pls5 255;
BA_ "GenSigSNA" SG_ 1098 VC_Strng_Rt_pls5 "FFh";
BA_ "GenSigSendType" SG_ 1098 VC_Strng_Rt_pls5 5;
BA_ "GenSigCycleTime" SG_ 1098 VC_Strng_Rt_pls5 2000;
BA_ "FlexKomSigStartValue" SG_ 1098 VC_Strng_Rt_pls5 "C3FFFFFFFFFFFF00h";
BA_ "FlexKomSigStartPos" SG_ 1098 VC_Strng_Rt_pls5 7;
BA_ "FlexKomSigName" SG_ 1098 VC_Strng_Rt_pls5 "VehCfg5_Pkt";
BA_ "FlexKomSigLaenge" SG_ 1098 VC_Strng_Rt_pls5 64;
BA_ "FlexKomSID" SG_ 1098 VC_Strng_Rt_pls5 1198;
BA_ "FlexKomIsMotorola" SG_ 1098 VC_Strng_Rt_pls5 1;
BA_ "FlexKomComment" SG_ 1098 VC_Strng_Rt_pls5 "Vehicle Configuration 5 Packet";
BA_ "GenSigTimeout_PTS" SG_ 1098 VC_VehCfg5_Stat 21000;
BA_ "GenSigTimeout_ORC" SG_ 1098 VC_VehCfg5_Stat 7000;
BA_ "GenSigTimeout_IC" SG_ 1098 VC_VehCfg5_Stat 21000;
BA_ "GenSigStartValue" SG_ 1098 VC_VehCfg5_Stat 3;
BA_ "GenSigSNA" SG_ 1098 VC_VehCfg5_Stat "3h";
BA_ "GenSigSendType" SG_ 1098 VC_VehCfg5_Stat 5;
BA_ "GenSigCycleTime" SG_ 1098 VC_VehCfg5_Stat 2000;
BA_ "FlexKomSigStartValue" SG_ 1098 VC_VehCfg5_Stat "C3FFFFFFFFFFFF00h";
BA_ "FlexKomSigStartPos" SG_ 1098 VC_VehCfg5_Stat 7;
BA_ "FlexKomSigName" SG_ 1098 VC_VehCfg5_Stat "VehCfg5_Pkt";
BA_ "FlexKomSigLaenge" SG_ 1098 VC_VehCfg5_Stat 64;
BA_ "FlexKomSID" SG_ 1098 VC_VehCfg5_Stat 1198;
BA_ "FlexKomIsMotorola" SG_ 1098 VC_VehCfg5_Stat 1;
BA_ "FlexKomComment" SG_ 1098 VC_VehCfg5_Stat "Vehicle Configuration 5 Packet";
BA_ "GenSigSNA" SG_ 1098 VC_WTS_Prsnt "0h";
BA_ "GenSigSendType" SG_ 1098 VC_WTS_Prsnt 5;
BA_ "GenSigCycleTime" SG_ 1098 VC_WTS_Prsnt 2000;
BA_ "FlexKomSigStartValue" SG_ 1098 VC_WTS_Prsnt "C3FFFFFFFFFFFF00h";
BA_ "FlexKomSigStartPos" SG_ 1098 VC_WTS_Prsnt 7;
BA_ "FlexKomSigName" SG_ 1098 VC_WTS_Prsnt "VehCfg5_Pkt";
BA_ "FlexKomSigLaenge" SG_ 1098 VC_WTS_Prsnt 64;
BA_ "FlexKomSID" SG_ 1098 VC_WTS_Prsnt 1198;
BA_ "FlexKomIsMotorola" SG_ 1098 VC_WTS_Prsnt 1;
BA_ "FlexKomComment" SG_ 1098 VC_WTS_Prsnt "Vehicle Configuration 5 Packet";
BA_ "GenSigSNA" SG_ 1100 VC_AQS_Prsnt "0h";
BA_ "GenSigSendType" SG_ 1100 VC_AQS_Prsnt 5;
BA_ "GenSigCycleTime" SG_ 1100 VC_AQS_Prsnt 2000;
BA_ "FlexKomSigStartValue" SG_ 1100 VC_AQS_Prsnt "73FFFFFFFFFFFFFFh";
BA_ "FlexKomSigStartPos" SG_ 1100 VC_AQS_Prsnt 7;
BA_ "FlexKomSigName" SG_ 1100 VC_AQS_Prsnt "VehCfg6_Pkt";
BA_ "FlexKomSigLaenge" SG_ 1100 VC_AQS_Prsnt 64;
BA_ "FlexKomSID" SG_ 1100 VC_AQS_Prsnt 1199;
BA_ "FlexKomIsMotorola" SG_ 1100 VC_AQS_Prsnt 1;
BA_ "FlexKomComment" SG_ 1100 VC_AQS_Prsnt "Vehicle Configuration 6 Packet";
BA_ "GenSigSNA" SG_ 1100 VC_AnlgDrSnsr "0h";
BA_ "GenSigSendType" SG_ 1100 VC_AnlgDrSnsr 5;
BA_ "GenSigCycleTime" SG_ 1100 VC_AnlgDrSnsr 2000;
BA_ "FlexKomSigStartValue" SG_ 1100 VC_AnlgDrSnsr "73FFFFFFFFFFFFFFh";
BA_ "FlexKomSigStartPos" SG_ 1100 VC_AnlgDrSnsr 7;
BA_ "FlexKomSigName" SG_ 1100 VC_AnlgDrSnsr "VehCfg6_Pkt";
BA_ "FlexKomSigLaenge" SG_ 1100 VC_AnlgDrSnsr 64;
BA_ "FlexKomSID" SG_ 1100 VC_AnlgDrSnsr 1199;
BA_ "FlexKomIsMotorola" SG_ 1100 VC_AnlgDrSnsr 1;
BA_ "FlexKomComment" SG_ 1100 VC_AnlgDrSnsr "Vehicle Configuration 6 Packet";
BA_ "GenSigStartValue" SG_ 1100 VC_BrkTyp 7;
BA_ "GenSigSNA" SG_ 1100 VC_BrkTyp "7h";
BA_ "GenSigSendType" SG_ 1100 VC_BrkTyp 5;
BA_ "GenSigCycleTime" SG_ 1100 VC_BrkTyp 2000;
BA_ "FlexKomSigStartValue" SG_ 1100 VC_BrkTyp "73FFFFFFFFFFFFFFh";
BA_ "FlexKomSigStartPos" SG_ 1100 VC_BrkTyp 7;
BA_ "FlexKomSigName" SG_ 1100 VC_BrkTyp "VehCfg6_Pkt";
BA_ "FlexKomSigLaenge" SG_ 1100 VC_BrkTyp 64;
BA_ "FlexKomSID" SG_ 1100 VC_BrkTyp 1199;
BA_ "FlexKomIsMotorola" SG_ 1100 VC_BrkTyp 1;
BA_ "FlexKomComment" SG_ 1100 VC_BrkTyp "Vehicle Configuration 6 Packet";
BA_ "GenSigStartValue" SG_ 1100 VC_Strng_Rt_Mns1 255;
BA_ "GenSigSNA" SG_ 1100 VC_Strng_Rt_Mns1 "FFh";
BA_ "GenSigSendType" SG_ 1100 VC_Strng_Rt_Mns1 5;
BA_ "GenSigCycleTime" SG_ 1100 VC_Strng_Rt_Mns1 2000;
BA_ "FlexKomSigStartValue" SG_ 1100 VC_Strng_Rt_Mns1 "73FFFFFFFFFFFFFFh";
BA_ "FlexKomSigStartPos" SG_ 1100 VC_Strng_Rt_Mns1 7;
BA_ "FlexKomSigName" SG_ 1100 VC_Strng_Rt_Mns1 "VehCfg6_Pkt";
BA_ "FlexKomSigLaenge" SG_ 1100 VC_Strng_Rt_Mns1 64;
BA_ "FlexKomSID" SG_ 1100 VC_Strng_Rt_Mns1 1199;
BA_ "FlexKomIsMotorola" SG_ 1100 VC_Strng_Rt_Mns1 1;
BA_ "FlexKomComment" SG_ 1100 VC_Strng_Rt_Mns1 "Vehicle Configuration 6 Packet";
BA_ "GenSigStartValue" SG_ 1100 VC_Strng_Rt_Mns2 255;
BA_ "GenSigSNA" SG_ 1100 VC_Strng_Rt_Mns2 "FFh";
BA_ "GenSigSendType" SG_ 1100 VC_Strng_Rt_Mns2 5;
BA_ "GenSigCycleTime" SG_ 1100 VC_Strng_Rt_Mns2 2000;
BA_ "FlexKomSigStartValue" SG_ 1100 VC_Strng_Rt_Mns2 "73FFFFFFFFFFFFFFh";
BA_ "FlexKomSigStartPos" SG_ 1100 VC_Strng_Rt_Mns2 7;
BA_ "FlexKomSigName" SG_ 1100 VC_Strng_Rt_Mns2 "VehCfg6_Pkt";
BA_ "FlexKomSigLaenge" SG_ 1100 VC_Strng_Rt_Mns2 64;
BA_ "FlexKomSID" SG_ 1100 VC_Strng_Rt_Mns2 1199;
BA_ "FlexKomIsMotorola" SG_ 1100 VC_Strng_Rt_Mns2 1;
BA_ "FlexKomComment" SG_ 1100 VC_Strng_Rt_Mns2 "Vehicle Configuration 6 Packet";
BA_ "GenSigStartValue" SG_ 1100 VC_Strng_Rt_Mns3 255;
BA_ "GenSigSNA" SG_ 1100 VC_Strng_Rt_Mns3 "FFh";
BA_ "GenSigSendType" SG_ 1100 VC_Strng_Rt_Mns3 5;
BA_ "GenSigCycleTime" SG_ 1100 VC_Strng_Rt_Mns3 2000;
BA_ "FlexKomSigStartValue" SG_ 1100 VC_Strng_Rt_Mns3 "73FFFFFFFFFFFFFFh";
BA_ "FlexKomSigStartPos" SG_ 1100 VC_Strng_Rt_Mns3 7;
BA_ "FlexKomSigName" SG_ 1100 VC_Strng_Rt_Mns3 "VehCfg6_Pkt";
BA_ "FlexKomSigLaenge" SG_ 1100 VC_Strng_Rt_Mns3 64;
BA_ "FlexKomSID" SG_ 1100 VC_Strng_Rt_Mns3 1199;
BA_ "FlexKomIsMotorola" SG_ 1100 VC_Strng_Rt_Mns3 1;
BA_ "FlexKomComment" SG_ 1100 VC_Strng_Rt_Mns3 "Vehicle Configuration 6 Packet";
BA_ "GenSigStartValue" SG_ 1100 VC_Strng_Rt_Mns4 255;
BA_ "GenSigSNA" SG_ 1100 VC_Strng_Rt_Mns4 "FFh";
BA_ "GenSigSendType" SG_ 1100 VC_Strng_Rt_Mns4 5;
BA_ "GenSigCycleTime" SG_ 1100 VC_Strng_Rt_Mns4 2000;
BA_ "FlexKomSigStartValue" SG_ 1100 VC_Strng_Rt_Mns4 "73FFFFFFFFFFFFFFh";
BA_ "FlexKomSigStartPos" SG_ 1100 VC_Strng_Rt_Mns4 7;
BA_ "FlexKomSigName" SG_ 1100 VC_Strng_Rt_Mns4 "VehCfg6_Pkt";
BA_ "FlexKomSigLaenge" SG_ 1100 VC_Strng_Rt_Mns4 64;
BA_ "FlexKomSID" SG_ 1100 VC_Strng_Rt_Mns4 1199;
BA_ "FlexKomIsMotorola" SG_ 1100 VC_Strng_Rt_Mns4 1;
BA_ "FlexKomComment" SG_ 1100 VC_Strng_Rt_Mns4 "Vehicle Configuration 6 Packet";
BA_ "GenSigStartValue" SG_ 1100 VC_Strng_Rt_Mns5 255;
BA_ "GenSigSNA" SG_ 1100 VC_Strng_Rt_Mns5 "FFh";
BA_ "GenSigSendType" SG_ 1100 VC_Strng_Rt_Mns5 5;
BA_ "GenSigCycleTime" SG_ 1100 VC_Strng_Rt_Mns5 2000;
BA_ "FlexKomSigStartValue" SG_ 1100 VC_Strng_Rt_Mns5 "73FFFFFFFFFFFFFFh";
BA_ "FlexKomSigStartPos" SG_ 1100 VC_Strng_Rt_Mns5 7;
BA_ "FlexKomSigName" SG_ 1100 VC_Strng_Rt_Mns5 "VehCfg6_Pkt";
BA_ "FlexKomSigLaenge" SG_ 1100 VC_Strng_Rt_Mns5 64;
BA_ "FlexKomSID" SG_ 1100 VC_Strng_Rt_Mns5 1199;
BA_ "FlexKomIsMotorola" SG_ 1100 VC_Strng_Rt_Mns5 1;
BA_ "FlexKomComment" SG_ 1100 VC_Strng_Rt_Mns5 "Vehicle Configuration 6 Packet";
BA_ "GenSigTimeout_ORC" SG_ 1100 VC_TireCircumfFT 7000;
BA_ "GenSigStartValue" SG_ 1100 VC_TireCircumfFT 65535;
BA_ "GenSigSNA" SG_ 1100 VC_TireCircumfFT "FFFFh";
BA_ "GenSigSendType" SG_ 1100 VC_TireCircumfFT 5;
BA_ "GenSigCycleTime" SG_ 1100 VC_TireCircumfFT 2000;
BA_ "FlexKomSigStartValue" SG_ 1100 VC_TireCircumfFT "73FFFFFFFFFFFFFFh";
BA_ "FlexKomSigStartPos" SG_ 1100 VC_TireCircumfFT 7;
BA_ "FlexKomSigName" SG_ 1100 VC_TireCircumfFT "VehCfg6_Pkt";
BA_ "FlexKomSigLaenge" SG_ 1100 VC_TireCircumfFT 64;
BA_ "FlexKomSID" SG_ 1100 VC_TireCircumfFT 1199;
BA_ "FlexKomIsMotorola" SG_ 1100 VC_TireCircumfFT 1;
BA_ "FlexKomComment" SG_ 1100 VC_TireCircumfFT "Vehicle Configuration 6 Packet";
BA_ "GenSigTimeout_ORC" SG_ 1100 VC_VehCfg6_Stat 7000;
BA_ "GenSigStartValue" SG_ 1100 VC_VehCfg6_Stat 3;
BA_ "GenSigSNA" SG_ 1100 VC_VehCfg6_Stat "3h";
BA_ "GenSigSendType" SG_ 1100 VC_VehCfg6_Stat 5;
BA_ "GenSigCycleTime" SG_ 1100 VC_VehCfg6_Stat 2000;
BA_ "FlexKomSigStartValue" SG_ 1100 VC_VehCfg6_Stat "73FFFFFFFFFFFFFFh";
BA_ "FlexKomSigStartPos" SG_ 1100 VC_VehCfg6_Stat 7;
BA_ "FlexKomSigName" SG_ 1100 VC_VehCfg6_Stat "VehCfg6_Pkt";
BA_ "FlexKomSigLaenge" SG_ 1100 VC_VehCfg6_Stat 64;
BA_ "FlexKomSID" SG_ 1100 VC_VehCfg6_Stat 1199;
BA_ "FlexKomIsMotorola" SG_ 1100 VC_VehCfg6_Stat 1;
BA_ "FlexKomComment" SG_ 1100 VC_VehCfg6_Stat "Vehicle Configuration 6 Packet";
BA_ "GenSigTimeout_IC" SG_ 897 VC_ABSM 21000;
BA_ "GenSigSNA" SG_ 897 VC_ABSM "0h";
BA_ "GenSigSendType" SG_ 897 VC_ABSM 5;
BA_ "GenSigCycleTime" SG_ 897 VC_ABSM 2000;
BA_ "FlexKomSigStartValue" SG_ 897 VC_ABSM "033F000000000000h";
BA_ "FlexKomSigStartPos" SG_ 897 VC_ABSM 7;
BA_ "FlexKomSigName" SG_ 897 VC_ABSM "VehCfg7_Pkt";
BA_ "FlexKomSigLaenge" SG_ 897 VC_ABSM 64;
BA_ "FlexKomSID" SG_ 897 VC_ABSM 2026;
BA_ "FlexKomIsMotorola" SG_ 897 VC_ABSM 1;
BA_ "FlexKomComment" SG_ 897 VC_ABSM "Vehicle Configuration 7 Packet";
BA_ "GenSigTimeout_ORC" SG_ 897 VC_ACC_Type 7000;
BA_ "GenSigSNA" SG_ 897 VC_ACC_Type "0h";
BA_ "GenSigSendType" SG_ 897 VC_ACC_Type 5;
BA_ "GenSigCycleTime" SG_ 897 VC_ACC_Type 2000;
BA_ "FlexKomSigStartValue" SG_ 897 VC_ACC_Type "033F000000000000h";
BA_ "FlexKomSigStartPos" SG_ 897 VC_ACC_Type 7;
BA_ "FlexKomSigName" SG_ 897 VC_ACC_Type "VehCfg7_Pkt";
BA_ "FlexKomSigLaenge" SG_ 897 VC_ACC_Type 64;
BA_ "FlexKomSID" SG_ 897 VC_ACC_Type 2026;
BA_ "FlexKomIsMotorola" SG_ 897 VC_ACC_Type 1;
BA_ "FlexKomComment" SG_ 897 VC_ACC_Type "Vehicle Configuration 7 Packet";
BA_ "GenSigSNA" SG_ 897 VC_ADR_PRSNT "0h";
BA_ "GenSigSendType" SG_ 897 VC_ADR_PRSNT 5;
BA_ "GenSigCycleTime" SG_ 897 VC_ADR_PRSNT 2000;
BA_ "FlexKomSigStartValue" SG_ 897 VC_ADR_PRSNT "033F000000000000h";
BA_ "FlexKomSigStartPos" SG_ 897 VC_ADR_PRSNT 7;
BA_ "FlexKomSigName" SG_ 897 VC_ADR_PRSNT "VehCfg7_Pkt";
BA_ "FlexKomSigLaenge" SG_ 897 VC_ADR_PRSNT 64;
BA_ "FlexKomSID" SG_ 897 VC_ADR_PRSNT 2026;
BA_ "FlexKomIsMotorola" SG_ 897 VC_ADR_PRSNT 1;
BA_ "FlexKomComment" SG_ 897 VC_ADR_PRSNT "Vehicle Configuration 7 Packet";
BA_ "GenSigSNA" SG_ 897 VC_AGSprsnt "0h";
BA_ "GenSigSendType" SG_ 897 VC_AGSprsnt 5;
BA_ "GenSigCycleTime" SG_ 897 VC_AGSprsnt 2000;
BA_ "FlexKomSigStartValue" SG_ 897 VC_AGSprsnt "033F000000000000h";
BA_ "FlexKomSigStartPos" SG_ 897 VC_AGSprsnt 7;
BA_ "FlexKomSigName" SG_ 897 VC_AGSprsnt "VehCfg7_Pkt";
BA_ "FlexKomSigLaenge" SG_ 897 VC_AGSprsnt 64;
BA_ "FlexKomSID" SG_ 897 VC_AGSprsnt 2026;
BA_ "FlexKomIsMotorola" SG_ 897 VC_AGSprsnt 1;
BA_ "FlexKomComment" SG_ 897 VC_AGSprsnt "Vehicle Configuration 7 Packet";
BA_ "GenSigTimeout_IC" SG_ 897 VC_AS_ERS 21000;
BA_ "GenSigSNA" SG_ 897 VC_AS_ERS "3h";
BA_ "GenSigSendType" SG_ 897 VC_AS_ERS 5;
BA_ "GenSigCycleTime" SG_ 897 VC_AS_ERS 2000;
BA_ "FlexKomSigStartValue" SG_ 897 VC_AS_ERS "033F000000000000h";
BA_ "FlexKomSigStartPos" SG_ 897 VC_AS_ERS 7;
BA_ "FlexKomSigName" SG_ 897 VC_AS_ERS "VehCfg7_Pkt";
BA_ "FlexKomSigLaenge" SG_ 897 VC_AS_ERS 64;
BA_ "FlexKomSID" SG_ 897 VC_AS_ERS 2026;
BA_ "FlexKomIsMotorola" SG_ 897 VC_AS_ERS 1;
BA_ "FlexKomComment" SG_ 897 VC_AS_ERS "Vehicle Configuration 7 Packet";
BA_ "GenSigSNA" SG_ 897 VC_AxleLockerPrsnt "0h";
BA_ "GenSigSendType" SG_ 897 VC_AxleLockerPrsnt 5;
BA_ "GenSigCycleTime" SG_ 897 VC_AxleLockerPrsnt 2000;
BA_ "FlexKomSigStartValue" SG_ 897 VC_AxleLockerPrsnt "033F000000000000h";
BA_ "FlexKomSigStartPos" SG_ 897 VC_AxleLockerPrsnt 7;
BA_ "FlexKomSigName" SG_ 897 VC_AxleLockerPrsnt "VehCfg7_Pkt";
BA_ "FlexKomSigLaenge" SG_ 897 VC_AxleLockerPrsnt 64;
BA_ "FlexKomSID" SG_ 897 VC_AxleLockerPrsnt 2026;
BA_ "FlexKomIsMotorola" SG_ 897 VC_AxleLockerPrsnt 1;
BA_ "FlexKomComment" SG_ 897 VC_AxleLockerPrsnt "Vehicle Configuration 7 Packet";
BA_ "GenSigSNA" SG_ 897 VC_Brake_Type "0h";
BA_ "GenSigSendType" SG_ 897 VC_Brake_Type 5;
BA_ "GenSigCycleTime" SG_ 897 VC_Brake_Type 2000;
BA_ "FlexKomSigStartValue" SG_ 897 VC_Brake_Type "033F000000000000h";
BA_ "FlexKomSigStartPos" SG_ 897 VC_Brake_Type 7;
BA_ "FlexKomSigName" SG_ 897 VC_Brake_Type "VehCfg7_Pkt";
BA_ "FlexKomSigLaenge" SG_ 897 VC_Brake_Type 64;
BA_ "FlexKomSID" SG_ 897 VC_Brake_Type 2026;
BA_ "FlexKomIsMotorola" SG_ 897 VC_Brake_Type 1;
BA_ "FlexKomComment" SG_ 897 VC_Brake_Type "Vehicle Configuration 7 Packet";
BA_ "GenSigTimeout_ORC" SG_ 897 VC_DST_Present 7000;
BA_ "GenSigSNA" SG_ 897 VC_DST_Present "0h";
BA_ "GenSigSendType" SG_ 897 VC_DST_Present 5;
BA_ "GenSigCycleTime" SG_ 897 VC_DST_Present 2000;
BA_ "FlexKomSigStartValue" SG_ 897 VC_DST_Present "033F000000000000h";
BA_ "FlexKomSigStartPos" SG_ 897 VC_DST_Present 7;
BA_ "FlexKomSigName" SG_ 897 VC_DST_Present "VehCfg7_Pkt";
BA_ "FlexKomSigLaenge" SG_ 897 VC_DST_Present 64;
BA_ "FlexKomSID" SG_ 897 VC_DST_Present 2026;
BA_ "FlexKomIsMotorola" SG_ 897 VC_DST_Present 1;
BA_ "FlexKomComment" SG_ 897 VC_DST_Present "Vehicle Configuration 7 Packet";
BA_ "GenSigTimeout_IC" SG_ 897 VC_DampingPrsnt 21000;
BA_ "GenSigSNA" SG_ 897 VC_DampingPrsnt "0h";
BA_ "GenSigSendType" SG_ 897 VC_DampingPrsnt 5;
BA_ "GenSigCycleTime" SG_ 897 VC_DampingPrsnt 2000;
BA_ "FlexKomSigStartValue" SG_ 897 VC_DampingPrsnt "033F000000000000h";
BA_ "FlexKomSigStartPos" SG_ 897 VC_DampingPrsnt 7;
BA_ "FlexKomSigName" SG_ 897 VC_DampingPrsnt "VehCfg7_Pkt";
BA_ "FlexKomSigLaenge" SG_ 897 VC_DampingPrsnt 64;
BA_ "FlexKomSID" SG_ 897 VC_DampingPrsnt 2026;
BA_ "FlexKomIsMotorola" SG_ 897 VC_DampingPrsnt 1;
BA_ "FlexKomComment" SG_ 897 VC_DampingPrsnt "Vehicle Configuration 7 Packet";
BA_ "GenSigTimeout_ORC" SG_ 897 VC_FullSpeedRange_FCW 7000;
BA_ "GenSigSNA" SG_ 897 VC_FullSpeedRange_FCW "0h";
BA_ "GenSigSendType" SG_ 897 VC_FullSpeedRange_FCW 5;
BA_ "GenSigCycleTime" SG_ 897 VC_FullSpeedRange_FCW 2000;
BA_ "FlexKomSigStartValue" SG_ 897 VC_FullSpeedRange_FCW "033F000000000000h";
BA_ "FlexKomSigStartPos" SG_ 897 VC_FullSpeedRange_FCW 7;
BA_ "FlexKomSigName" SG_ 897 VC_FullSpeedRange_FCW "VehCfg7_Pkt";
BA_ "FlexKomSigLaenge" SG_ 897 VC_FullSpeedRange_FCW 64;
BA_ "FlexKomSID" SG_ 897 VC_FullSpeedRange_FCW 2026;
BA_ "FlexKomIsMotorola" SG_ 897 VC_FullSpeedRange_FCW 1;
BA_ "FlexKomComment" SG_ 897 VC_FullSpeedRange_FCW "Vehicle Configuration 7 Packet";
BA_ "GenSigSNA" SG_ 897 VC_GlareFree_Prsnt "0h";
BA_ "GenSigSendType" SG_ 897 VC_GlareFree_Prsnt 5;
BA_ "GenSigCycleTime" SG_ 897 VC_GlareFree_Prsnt 2000;
BA_ "FlexKomSigStartValue" SG_ 897 VC_GlareFree_Prsnt "033F000000000000h";
BA_ "FlexKomSigStartPos" SG_ 897 VC_GlareFree_Prsnt 7;
BA_ "FlexKomSigName" SG_ 897 VC_GlareFree_Prsnt "VehCfg7_Pkt";
BA_ "FlexKomSigLaenge" SG_ 897 VC_GlareFree_Prsnt 64;
BA_ "FlexKomSID" SG_ 897 VC_GlareFree_Prsnt 2026;
BA_ "FlexKomIsMotorola" SG_ 897 VC_GlareFree_Prsnt 1;
BA_ "FlexKomComment" SG_ 897 VC_GlareFree_Prsnt "Vehicle Configuration 7 Packet";
BA_ "GenSigSNA" SG_ 897 VC_Glovebox "0h";
BA_ "GenSigSendType" SG_ 897 VC_Glovebox 5;
BA_ "GenSigCycleTime" SG_ 897 VC_Glovebox 2000;
BA_ "FlexKomSigStartValue" SG_ 897 VC_Glovebox "033F000000000000h";
BA_ "FlexKomSigStartPos" SG_ 897 VC_Glovebox 7;
BA_ "FlexKomSigName" SG_ 897 VC_Glovebox "VehCfg7_Pkt";
BA_ "FlexKomSigLaenge" SG_ 897 VC_Glovebox 64;
BA_ "FlexKomSID" SG_ 897 VC_Glovebox 2026;
BA_ "FlexKomIsMotorola" SG_ 897 VC_Glovebox 1;
BA_ "FlexKomComment" SG_ 897 VC_Glovebox "Vehicle Configuration 7 Packet";
BA_ "GenSigTimeout_ORC" SG_ 897 VC_HybridType 7000;
BA_ "GenSigSNA" SG_ 897 VC_HybridType "0h";
BA_ "GenSigSendType" SG_ 897 VC_HybridType 5;
BA_ "GenSigCycleTime" SG_ 897 VC_HybridType 2000;
BA_ "FlexKomSigStartValue" SG_ 897 VC_HybridType "033F000000000000h";
BA_ "FlexKomSigStartPos" SG_ 897 VC_HybridType 7;
BA_ "FlexKomSigName" SG_ 897 VC_HybridType "VehCfg7_Pkt";
BA_ "FlexKomSigLaenge" SG_ 897 VC_HybridType 64;
BA_ "FlexKomSID" SG_ 897 VC_HybridType 2026;
BA_ "FlexKomIsMotorola" SG_ 897 VC_HybridType 1;
BA_ "FlexKomComment" SG_ 897 VC_HybridType "Vehicle Configuration 7 Packet";
BA_ "GenSigTimeout_ORC" SG_ 897 VC_LDW 7000;
BA_ "GenSigSNA" SG_ 897 VC_LDW "0h";
BA_ "GenSigSendType" SG_ 897 VC_LDW 5;
BA_ "GenSigCycleTime" SG_ 897 VC_LDW 2000;
BA_ "FlexKomSigStartValue" SG_ 897 VC_LDW "033F000000000000h";
BA_ "FlexKomSigStartPos" SG_ 897 VC_LDW 7;
BA_ "FlexKomSigName" SG_ 897 VC_LDW "VehCfg7_Pkt";
BA_ "FlexKomSigLaenge" SG_ 897 VC_LDW 64;
BA_ "FlexKomSID" SG_ 897 VC_LDW 2026;
BA_ "FlexKomIsMotorola" SG_ 897 VC_LDW 1;
BA_ "FlexKomComment" SG_ 897 VC_LDW "Vehicle Configuration 7 Packet";
BA_ "GenSigTimeout_IC" SG_ 897 VC_MOC_Type 21000;
BA_ "GenSigSNA" SG_ 897 VC_MOC_Type "0h";
BA_ "GenSigSendType" SG_ 897 VC_MOC_Type 5;
BA_ "GenSigCycleTime" SG_ 897 VC_MOC_Type 2000;
BA_ "FlexKomSigStartValue" SG_ 897 VC_MOC_Type "033F000000000000h";
BA_ "FlexKomSigStartPos" SG_ 897 VC_MOC_Type 7;
BA_ "FlexKomSigName" SG_ 897 VC_MOC_Type "VehCfg7_Pkt";
BA_ "FlexKomSigLaenge" SG_ 897 VC_MOC_Type 64;
BA_ "FlexKomSID" SG_ 897 VC_MOC_Type 2026;
BA_ "FlexKomIsMotorola" SG_ 897 VC_MOC_Type 1;
BA_ "FlexKomComment" SG_ 897 VC_MOC_Type "Vehicle Configuration 7 Packet";
BA_ "GenSigTimeout_ORC" SG_ 897 VC_PBTyp 7000;
BA_ "GenSigSNA" SG_ 897 VC_PBTyp "7h";
BA_ "GenSigSendType" SG_ 897 VC_PBTyp 5;
BA_ "GenSigCycleTime" SG_ 897 VC_PBTyp 2000;
BA_ "FlexKomSigStartValue" SG_ 897 VC_PBTyp "033F000000000000h";
BA_ "FlexKomSigStartPos" SG_ 897 VC_PBTyp 7;
BA_ "FlexKomSigName" SG_ 897 VC_PBTyp "VehCfg7_Pkt";
BA_ "FlexKomSigLaenge" SG_ 897 VC_PBTyp 64;
BA_ "FlexKomSID" SG_ 897 VC_PBTyp 2026;
BA_ "FlexKomIsMotorola" SG_ 897 VC_PBTyp 1;
BA_ "FlexKomComment" SG_ 897 VC_PBTyp "Vehicle Configuration 7 Packet";
BA_ "GenSigSNA" SG_ 897 VC_PTCPrsnt "0h";
BA_ "GenSigSendType" SG_ 897 VC_PTCPrsnt 5;
BA_ "GenSigCycleTime" SG_ 897 VC_PTCPrsnt 2000;
BA_ "FlexKomSigStartValue" SG_ 897 VC_PTCPrsnt "033F000000000000h";
BA_ "FlexKomSigStartPos" SG_ 897 VC_PTCPrsnt 7;
BA_ "FlexKomSigName" SG_ 897 VC_PTCPrsnt "VehCfg7_Pkt";
BA_ "FlexKomSigLaenge" SG_ 897 VC_PTCPrsnt 64;
BA_ "FlexKomSID" SG_ 897 VC_PTCPrsnt 2026;
BA_ "FlexKomIsMotorola" SG_ 897 VC_PTCPrsnt 1;
BA_ "FlexKomComment" SG_ 897 VC_PTCPrsnt "Vehicle Configuration 7 Packet";
BA_ "GenSigTimeout_IC" SG_ 897 VC_PdlsMdPrsnt 21000;
BA_ "GenSigSNA" SG_ 897 VC_PdlsMdPrsnt "0h";
BA_ "GenSigSendType" SG_ 897 VC_PdlsMdPrsnt 5;
BA_ "GenSigCycleTime" SG_ 897 VC_PdlsMdPrsnt 2000;
BA_ "FlexKomSigStartValue" SG_ 897 VC_PdlsMdPrsnt "033F000000000000h";
BA_ "FlexKomSigStartPos" SG_ 897 VC_PdlsMdPrsnt 7;
BA_ "FlexKomSigName" SG_ 897 VC_PdlsMdPrsnt "VehCfg7_Pkt";
BA_ "FlexKomSigLaenge" SG_ 897 VC_PdlsMdPrsnt 64;
BA_ "FlexKomSID" SG_ 897 VC_PdlsMdPrsnt 2026;
BA_ "FlexKomIsMotorola" SG_ 897 VC_PdlsMdPrsnt 1;
BA_ "FlexKomComment" SG_ 897 VC_PdlsMdPrsnt "Vehicle Configuration 7 Packet";
BA_ "GenSigTimeout_RF_HUB" SG_ 897 VC_RedKey 21000;
BA_ "GenSigSNA" SG_ 897 VC_RedKey "0h";
BA_ "GenSigSendType" SG_ 897 VC_RedKey 5;
BA_ "GenSigCycleTime" SG_ 897 VC_RedKey 2000;
BA_ "FlexKomSigStartValue" SG_ 897 VC_RedKey "033F000000000000h";
BA_ "FlexKomSigStartPos" SG_ 897 VC_RedKey 7;
BA_ "FlexKomSigName" SG_ 897 VC_RedKey "VehCfg7_Pkt";
BA_ "FlexKomSigLaenge" SG_ 897 VC_RedKey 64;
BA_ "FlexKomSID" SG_ 897 VC_RedKey 2026;
BA_ "FlexKomIsMotorola" SG_ 897 VC_RedKey 1;
BA_ "FlexKomComment" SG_ 897 VC_RedKey "Vehicle Configuration 7 Packet";
BA_ "GenSigTimeout_IC" SG_ 897 VC_STP_PRSNT 21000;
BA_ "GenSigSNA" SG_ 897 VC_STP_PRSNT "0h";
BA_ "GenSigSendType" SG_ 897 VC_STP_PRSNT 5;
BA_ "GenSigCycleTime" SG_ 897 VC_STP_PRSNT 2000;
BA_ "FlexKomSigStartValue" SG_ 897 VC_STP_PRSNT "033F000000000000h";
BA_ "FlexKomSigStartPos" SG_ 897 VC_STP_PRSNT 7;
BA_ "FlexKomSigName" SG_ 897 VC_STP_PRSNT "VehCfg7_Pkt";
BA_ "FlexKomSigLaenge" SG_ 897 VC_STP_PRSNT 64;
BA_ "FlexKomSID" SG_ 897 VC_STP_PRSNT 2026;
BA_ "FlexKomIsMotorola" SG_ 897 VC_STP_PRSNT 1;
BA_ "FlexKomComment" SG_ 897 VC_STP_PRSNT "Vehicle Configuration 7 Packet";
BA_ "GenSigSNA" SG_ 897 VC_SUNR_Prsnt "0h";
BA_ "GenSigSendType" SG_ 897 VC_SUNR_Prsnt 5;
BA_ "GenSigCycleTime" SG_ 897 VC_SUNR_Prsnt 2000;
BA_ "FlexKomSigStartValue" SG_ 897 VC_SUNR_Prsnt "033F000000000000h";
BA_ "FlexKomSigStartPos" SG_ 897 VC_SUNR_Prsnt 7;
BA_ "FlexKomSigName" SG_ 897 VC_SUNR_Prsnt "VehCfg7_Pkt";
BA_ "FlexKomSigLaenge" SG_ 897 VC_SUNR_Prsnt 64;
BA_ "FlexKomSID" SG_ 897 VC_SUNR_Prsnt 2026;
BA_ "FlexKomIsMotorola" SG_ 897 VC_SUNR_Prsnt 1;
BA_ "FlexKomComment" SG_ 897 VC_SUNR_Prsnt "Vehicle Configuration 7 Packet";
BA_ "GenSigSNA" SG_ 897 VC_SVC_Prsnt "0h";
BA_ "GenSigSendType" SG_ 897 VC_SVC_Prsnt 5;
BA_ "GenSigCycleTime" SG_ 897 VC_SVC_Prsnt 2000;
BA_ "FlexKomSigStartValue" SG_ 897 VC_SVC_Prsnt "033F000000000000h";
BA_ "FlexKomSigStartPos" SG_ 897 VC_SVC_Prsnt 7;
BA_ "FlexKomSigName" SG_ 897 VC_SVC_Prsnt "VehCfg7_Pkt";
BA_ "FlexKomSigLaenge" SG_ 897 VC_SVC_Prsnt 64;
BA_ "FlexKomSID" SG_ 897 VC_SVC_Prsnt 2026;
BA_ "FlexKomIsMotorola" SG_ 897 VC_SVC_Prsnt 1;
BA_ "FlexKomComment" SG_ 897 VC_SVC_Prsnt "Vehicle Configuration 7 Packet";
BA_ "GenSigSNA" SG_ 897 VC_SmartAlternator "0h";
BA_ "GenSigSendType" SG_ 897 VC_SmartAlternator 5;
BA_ "GenSigCycleTime" SG_ 897 VC_SmartAlternator 2000;
BA_ "FlexKomSigStartValue" SG_ 897 VC_SmartAlternator "033F000000000000h";
BA_ "FlexKomSigStartPos" SG_ 897 VC_SmartAlternator 7;
BA_ "FlexKomSigName" SG_ 897 VC_SmartAlternator "VehCfg7_Pkt";
BA_ "FlexKomSigLaenge" SG_ 897 VC_SmartAlternator 64;
BA_ "FlexKomSID" SG_ 897 VC_SmartAlternator 2026;
BA_ "FlexKomIsMotorola" SG_ 897 VC_SmartAlternator 1;
BA_ "FlexKomComment" SG_ 897 VC_SmartAlternator "Vehicle Configuration 7 Packet";
BA_ "GenSigTimeout_IC" SG_ 897 VC_SuspPrsnt 21000;
BA_ "GenSigSNA" SG_ 897 VC_SuspPrsnt "0h";
BA_ "GenSigSendType" SG_ 897 VC_SuspPrsnt 5;
BA_ "GenSigCycleTime" SG_ 897 VC_SuspPrsnt 2000;
BA_ "FlexKomSigStartValue" SG_ 897 VC_SuspPrsnt "033F000000000000h";
BA_ "FlexKomSigStartPos" SG_ 897 VC_SuspPrsnt 7;
BA_ "FlexKomSigName" SG_ 897 VC_SuspPrsnt "VehCfg7_Pkt";
BA_ "FlexKomSigLaenge" SG_ 897 VC_SuspPrsnt 64;
BA_ "FlexKomSID" SG_ 897 VC_SuspPrsnt 2026;
BA_ "FlexKomIsMotorola" SG_ 897 VC_SuspPrsnt 1;
BA_ "FlexKomComment" SG_ 897 VC_SuspPrsnt "Vehicle Configuration 7 Packet";
BA_ "GenSigSNA" SG_ 897 VC_Suspension_Type "0h";
BA_ "GenSigSendType" SG_ 897 VC_Suspension_Type 5;
BA_ "GenSigCycleTime" SG_ 897 VC_Suspension_Type 2000;
BA_ "FlexKomSigStartValue" SG_ 897 VC_Suspension_Type "033F000000000000h";
BA_ "FlexKomSigStartPos" SG_ 897 VC_Suspension_Type 7;
BA_ "FlexKomSigName" SG_ 897 VC_Suspension_Type "VehCfg7_Pkt";
BA_ "FlexKomSigLaenge" SG_ 897 VC_Suspension_Type 64;
BA_ "FlexKomSID" SG_ 897 VC_Suspension_Type 2026;
BA_ "FlexKomIsMotorola" SG_ 897 VC_Suspension_Type 1;
BA_ "FlexKomComment" SG_ 897 VC_Suspension_Type "Vehicle Configuration 7 Packet";
BA_ "GenSigTimeout_TPM" SG_ 897 VC_TPMS_Configuration 21000;
BA_ "GenSigTimeout_IC" SG_ 897 VC_TPMS_Configuration 21000;
BA_ "GenSigSNA" SG_ 897 VC_TPMS_Configuration "7h";
BA_ "GenSigSendType" SG_ 897 VC_TPMS_Configuration 5;
BA_ "GenSigCycleTime" SG_ 897 VC_TPMS_Configuration 2000;
BA_ "FlexKomSigStartValue" SG_ 897 VC_TPMS_Configuration "033F000000000000h";
BA_ "FlexKomSigStartPos" SG_ 897 VC_TPMS_Configuration 7;
BA_ "FlexKomSigName" SG_ 897 VC_TPMS_Configuration "VehCfg7_Pkt";
BA_ "FlexKomSigLaenge" SG_ 897 VC_TPMS_Configuration 64;
BA_ "FlexKomSID" SG_ 897 VC_TPMS_Configuration 2026;
BA_ "FlexKomIsMotorola" SG_ 897 VC_TPMS_Configuration 1;
BA_ "FlexKomComment" SG_ 897 VC_TPMS_Configuration "Vehicle Configuration 7 Packet";
BA_ "GenSigSNA" SG_ 897 VC_TSBM_Prsnt "0h";
BA_ "GenSigSendType" SG_ 897 VC_TSBM_Prsnt 5;
BA_ "GenSigCycleTime" SG_ 897 VC_TSBM_Prsnt 2000;
BA_ "FlexKomSigStartValue" SG_ 897 VC_TSBM_Prsnt "033F000000000000h";
BA_ "FlexKomSigStartPos" SG_ 897 VC_TSBM_Prsnt 7;
BA_ "FlexKomSigName" SG_ 897 VC_TSBM_Prsnt "VehCfg7_Pkt";
BA_ "FlexKomSigLaenge" SG_ 897 VC_TSBM_Prsnt 64;
BA_ "FlexKomSID" SG_ 897 VC_TSBM_Prsnt 2026;
BA_ "FlexKomIsMotorola" SG_ 897 VC_TSBM_Prsnt 1;
BA_ "FlexKomComment" SG_ 897 VC_TSBM_Prsnt "Vehicle Configuration 7 Packet";
BA_ "GenSigTimeout_RF_HUB" SG_ 897 VC_TeenKey 21000;
BA_ "GenSigSNA" SG_ 897 VC_TeenKey "0h";
BA_ "GenSigSendType" SG_ 897 VC_TeenKey 5;
BA_ "GenSigCycleTime" SG_ 897 VC_TeenKey 2000;
BA_ "FlexKomSigStartValue" SG_ 897 VC_TeenKey "033F000000000000h";
BA_ "FlexKomSigStartPos" SG_ 897 VC_TeenKey 7;
BA_ "FlexKomSigName" SG_ 897 VC_TeenKey "VehCfg7_Pkt";
BA_ "FlexKomSigLaenge" SG_ 897 VC_TeenKey 64;
BA_ "FlexKomSID" SG_ 897 VC_TeenKey 2026;
BA_ "FlexKomIsMotorola" SG_ 897 VC_TeenKey 1;
BA_ "FlexKomComment" SG_ 897 VC_TeenKey "Vehicle Configuration 7 Packet";
BA_ "GenSigSNA" SG_ 897 VC_Temp_Display_Resolution "0h";
BA_ "GenSigSendType" SG_ 897 VC_Temp_Display_Resolution 5;
BA_ "GenSigCycleTime" SG_ 897 VC_Temp_Display_Resolution 2000;
BA_ "FlexKomSigStartValue" SG_ 897 VC_Temp_Display_Resolution "033F000000000000h";
BA_ "FlexKomSigStartPos" SG_ 897 VC_Temp_Display_Resolution 7;
BA_ "FlexKomSigName" SG_ 897 VC_Temp_Display_Resolution "VehCfg7_Pkt";
BA_ "FlexKomSigLaenge" SG_ 897 VC_Temp_Display_Resolution 64;
BA_ "FlexKomSID" SG_ 897 VC_Temp_Display_Resolution 2026;
BA_ "FlexKomIsMotorola" SG_ 897 VC_Temp_Display_Resolution 1;
BA_ "FlexKomComment" SG_ 897 VC_Temp_Display_Resolution "Vehicle Configuration 7 Packet";
BA_ "GenSigTimeout_IC" SG_ 897 VC_TransType 21000;
BA_ "GenSigStartValue" SG_ 897 VC_TransType 63;
BA_ "GenSigSNA" SG_ 897 VC_TransType "3Fh";
BA_ "GenSigSendType" SG_ 897 VC_TransType 5;
BA_ "GenSigCycleTime" SG_ 897 VC_TransType 2000;
BA_ "FlexKomSigStartValue" SG_ 897 VC_TransType "033F000000000000h";
BA_ "FlexKomSigStartPos" SG_ 897 VC_TransType 7;
BA_ "FlexKomSigName" SG_ 897 VC_TransType "VehCfg7_Pkt";
BA_ "FlexKomSigLaenge" SG_ 897 VC_TransType 64;
BA_ "FlexKomSID" SG_ 897 VC_TransType 2026;
BA_ "FlexKomIsMotorola" SG_ 897 VC_TransType 1;
BA_ "FlexKomComment" SG_ 897 VC_TransType "Vehicle Configuration 7 Packet";
BA_ "GenSigTimeout_ORC" SG_ 897 VC_Trans_Equipped 7000;
BA_ "GenSigSNA" SG_ 897 VC_Trans_Equipped "0h";
BA_ "GenSigSendType" SG_ 897 VC_Trans_Equipped 5;
BA_ "GenSigCycleTime" SG_ 897 VC_Trans_Equipped 2000;
BA_ "FlexKomSigStartValue" SG_ 897 VC_Trans_Equipped "033F000000000000h";
BA_ "FlexKomSigStartPos" SG_ 897 VC_Trans_Equipped 7;
BA_ "FlexKomSigName" SG_ 897 VC_Trans_Equipped "VehCfg7_Pkt";
BA_ "FlexKomSigLaenge" SG_ 897 VC_Trans_Equipped 64;
BA_ "FlexKomSID" SG_ 897 VC_Trans_Equipped 2026;
BA_ "FlexKomIsMotorola" SG_ 897 VC_Trans_Equipped 1;
BA_ "FlexKomComment" SG_ 897 VC_Trans_Equipped "Vehicle Configuration 7 Packet";
BA_ "GenSigSNA" SG_ 897 VC_Trans_N_Hold_Prsnt "0h";
BA_ "GenSigSendType" SG_ 897 VC_Trans_N_Hold_Prsnt 5;
BA_ "GenSigCycleTime" SG_ 897 VC_Trans_N_Hold_Prsnt 2000;
BA_ "FlexKomSigStartValue" SG_ 897 VC_Trans_N_Hold_Prsnt "033F000000000000h";
BA_ "FlexKomSigStartPos" SG_ 897 VC_Trans_N_Hold_Prsnt 7;
BA_ "FlexKomSigName" SG_ 897 VC_Trans_N_Hold_Prsnt "VehCfg7_Pkt";
BA_ "FlexKomSigLaenge" SG_ 897 VC_Trans_N_Hold_Prsnt 64;
BA_ "FlexKomSID" SG_ 897 VC_Trans_N_Hold_Prsnt 2026;
BA_ "FlexKomIsMotorola" SG_ 897 VC_Trans_N_Hold_Prsnt 1;
BA_ "FlexKomComment" SG_ 897 VC_Trans_N_Hold_Prsnt "Vehicle Configuration 7 Packet";
BA_ "GenSigTimeout_IC" SG_ 897 VC_TrnsDrvMdPrsnt 21000;
BA_ "GenSigSNA" SG_ 897 VC_TrnsDrvMdPrsnt "0h";
BA_ "GenSigSendType" SG_ 897 VC_TrnsDrvMdPrsnt 5;
BA_ "GenSigCycleTime" SG_ 897 VC_TrnsDrvMdPrsnt 2000;
BA_ "FlexKomSigStartValue" SG_ 897 VC_TrnsDrvMdPrsnt "033F000000000000h";
BA_ "FlexKomSigStartPos" SG_ 897 VC_TrnsDrvMdPrsnt 7;
BA_ "FlexKomSigName" SG_ 897 VC_TrnsDrvMdPrsnt "VehCfg7_Pkt";
BA_ "FlexKomSigLaenge" SG_ 897 VC_TrnsDrvMdPrsnt 64;
BA_ "FlexKomSID" SG_ 897 VC_TrnsDrvMdPrsnt 2026;
BA_ "FlexKomIsMotorola" SG_ 897 VC_TrnsDrvMdPrsnt 1;
BA_ "FlexKomComment" SG_ 897 VC_TrnsDrvMdPrsnt "Vehicle Configuration 7 Packet";
BA_ "GenSigTimeout_TPM" SG_ 897 VC_VehCfg7_Stat 21000;
BA_ "GenSigTimeout_ORC" SG_ 897 VC_VehCfg7_Stat 7000;
BA_ "GenSigTimeout_IC" SG_ 897 VC_VehCfg7_Stat 21000;
BA_ "GenSigStartValue" SG_ 897 VC_VehCfg7_Stat 3;
BA_ "GenSigSNA" SG_ 897 VC_VehCfg7_Stat "3h";
BA_ "GenSigSendType" SG_ 897 VC_VehCfg7_Stat 5;
BA_ "GenSigCycleTime" SG_ 897 VC_VehCfg7_Stat 2000;
BA_ "FlexKomSigStartValue" SG_ 897 VC_VehCfg7_Stat "033F000000000000h";
BA_ "FlexKomSigStartPos" SG_ 897 VC_VehCfg7_Stat 7;
BA_ "FlexKomSigName" SG_ 897 VC_VehCfg7_Stat "VehCfg7_Pkt";
BA_ "FlexKomSigLaenge" SG_ 897 VC_VehCfg7_Stat 64;
BA_ "FlexKomSID" SG_ 897 VC_VehCfg7_Stat 2026;
BA_ "FlexKomIsMotorola" SG_ 897 VC_VehCfg7_Stat 1;
BA_ "FlexKomComment" SG_ 897 VC_VehCfg7_Stat "Vehicle Configuration 7 Packet";
BA_ "GenSigTimeout_RF_HUB" SG_ 897 VC_eShifter_Prsnt 21000;
BA_ "GenSigSNA" SG_ 897 VC_eShifter_Prsnt "0h";
BA_ "GenSigSendType" SG_ 897 VC_eShifter_Prsnt 5;
BA_ "GenSigCycleTime" SG_ 897 VC_eShifter_Prsnt 2000;
BA_ "FlexKomSigStartValue" SG_ 897 VC_eShifter_Prsnt "033F000000000000h";
BA_ "FlexKomSigStartPos" SG_ 897 VC_eShifter_Prsnt 7;
BA_ "FlexKomSigName" SG_ 897 VC_eShifter_Prsnt "VehCfg7_Pkt";
BA_ "FlexKomSigLaenge" SG_ 897 VC_eShifter_Prsnt 64;
BA_ "FlexKomSID" SG_ 897 VC_eShifter_Prsnt 2026;
BA_ "FlexKomIsMotorola" SG_ 897 VC_eShifter_Prsnt 1;
BA_ "FlexKomComment" SG_ 897 VC_eShifter_Prsnt "Vehicle Configuration 7 Packet";
BA_ "GenSigTimeout_TPM" SG_ 906 VC_ARC_PRSNT 21000;
BA_ "GenSigTimeout_ORC" SG_ 906 VC_ARC_PRSNT 7000;
BA_ "GenSigTimeout_IC" SG_ 906 VC_ARC_PRSNT 21000;
BA_ "GenSigSNA" SG_ 906 VC_ARC_PRSNT "0h";
BA_ "GenSigSendType" SG_ 906 VC_ARC_PRSNT 5;
BA_ "GenSigCycleTime" SG_ 906 VC_ARC_PRSNT 2000;
BA_ "FlexKomSigStartValue" SG_ 906 VC_ARC_PRSNT "0300000000000000h";
BA_ "FlexKomSigStartPos" SG_ 906 VC_ARC_PRSNT 7;
BA_ "FlexKomSigName" SG_ 906 VC_ARC_PRSNT "VehCfg8_Pkt";
BA_ "FlexKomSigLaenge" SG_ 906 VC_ARC_PRSNT 64;
BA_ "FlexKomSID" SG_ 906 VC_ARC_PRSNT 2722;
BA_ "FlexKomIsMotorola" SG_ 906 VC_ARC_PRSNT 1;
BA_ "FlexKomComment" SG_ 906 VC_ARC_PRSNT "Vehicle Configuration 8 Packet";
BA_ "GenSigSNA" SG_ 906 VC_AVAC_PRSNT "0h";
BA_ "GenSigSendType" SG_ 906 VC_AVAC_PRSNT 5;
BA_ "GenSigCycleTime" SG_ 906 VC_AVAC_PRSNT 2000;
BA_ "FlexKomSigStartValue" SG_ 906 VC_AVAC_PRSNT "0300000000000000h";
BA_ "FlexKomSigStartPos" SG_ 906 VC_AVAC_PRSNT 7;
BA_ "FlexKomSigName" SG_ 906 VC_AVAC_PRSNT "VehCfg8_Pkt";
BA_ "FlexKomSigLaenge" SG_ 906 VC_AVAC_PRSNT 64;
BA_ "FlexKomSID" SG_ 906 VC_AVAC_PRSNT 2722;
BA_ "FlexKomIsMotorola" SG_ 906 VC_AVAC_PRSNT 1;
BA_ "FlexKomComment" SG_ 906 VC_AVAC_PRSNT "Vehicle Configuration 8 Packet";
BA_ "GenSigSNA" SG_ 906 VC_BEAM_SHAPING_PRSNT "0h";
BA_ "GenSigSendType" SG_ 906 VC_BEAM_SHAPING_PRSNT 5;
BA_ "GenSigCycleTime" SG_ 906 VC_BEAM_SHAPING_PRSNT 2000;
BA_ "FlexKomSigStartValue" SG_ 906 VC_BEAM_SHAPING_PRSNT "0300000000000000h";
BA_ "FlexKomSigStartPos" SG_ 906 VC_BEAM_SHAPING_PRSNT 7;
BA_ "FlexKomSigName" SG_ 906 VC_BEAM_SHAPING_PRSNT "VehCfg8_Pkt";
BA_ "FlexKomSigLaenge" SG_ 906 VC_BEAM_SHAPING_PRSNT 64;
BA_ "FlexKomSID" SG_ 906 VC_BEAM_SHAPING_PRSNT 2722;
BA_ "FlexKomIsMotorola" SG_ 906 VC_BEAM_SHAPING_PRSNT 1;
BA_ "FlexKomComment" SG_ 906 VC_BEAM_SHAPING_PRSNT "Vehicle Configuration 8 Packet";
BA_ "GenSigTimeout_TPM" SG_ 906 VC_CHILLER_PRSNT 21000;
BA_ "GenSigTimeout_ORC" SG_ 906 VC_CHILLER_PRSNT 7000;
BA_ "GenSigTimeout_IC" SG_ 906 VC_CHILLER_PRSNT 21000;
BA_ "GenSigSNA" SG_ 906 VC_CHILLER_PRSNT "0h";
BA_ "GenSigSendType" SG_ 906 VC_CHILLER_PRSNT 5;
BA_ "GenSigCycleTime" SG_ 906 VC_CHILLER_PRSNT 2000;
BA_ "FlexKomSigStartValue" SG_ 906 VC_CHILLER_PRSNT "0300000000000000h";
BA_ "FlexKomSigStartPos" SG_ 906 VC_CHILLER_PRSNT 7;
BA_ "FlexKomSigName" SG_ 906 VC_CHILLER_PRSNT "VehCfg8_Pkt";
BA_ "FlexKomSigLaenge" SG_ 906 VC_CHILLER_PRSNT 64;
BA_ "FlexKomSID" SG_ 906 VC_CHILLER_PRSNT 2722;
BA_ "FlexKomIsMotorola" SG_ 906 VC_CHILLER_PRSNT 1;
BA_ "FlexKomComment" SG_ 906 VC_CHILLER_PRSNT "Vehicle Configuration 8 Packet";
BA_ "GenSigSNA" SG_ 906 VC_DBL_PRSNT "0h";
BA_ "GenSigSendType" SG_ 906 VC_DBL_PRSNT 5;
BA_ "GenSigCycleTime" SG_ 906 VC_DBL_PRSNT 2000;
BA_ "FlexKomSigStartValue" SG_ 906 VC_DBL_PRSNT "0300000000000000h";
BA_ "FlexKomSigStartPos" SG_ 906 VC_DBL_PRSNT 7;
BA_ "FlexKomSigName" SG_ 906 VC_DBL_PRSNT "VehCfg8_Pkt";
BA_ "FlexKomSigLaenge" SG_ 906 VC_DBL_PRSNT 64;
BA_ "FlexKomSID" SG_ 906 VC_DBL_PRSNT 2722;
BA_ "FlexKomIsMotorola" SG_ 906 VC_DBL_PRSNT 1;
BA_ "FlexKomComment" SG_ 906 VC_DBL_PRSNT "Vehicle Configuration 8 Packet";
BA_ "GenSigSNA" SG_ 906 VC_FADPrsnt "0h";
BA_ "GenSigSendType" SG_ 906 VC_FADPrsnt 5;
BA_ "GenSigCycleTime" SG_ 906 VC_FADPrsnt 2000;
BA_ "FlexKomSigStartValue" SG_ 906 VC_FADPrsnt "0300000000000000h";
BA_ "FlexKomSigStartPos" SG_ 906 VC_FADPrsnt 7;
BA_ "FlexKomSigName" SG_ 906 VC_FADPrsnt "VehCfg8_Pkt";
BA_ "FlexKomSigLaenge" SG_ 906 VC_FADPrsnt 64;
BA_ "FlexKomSID" SG_ 906 VC_FADPrsnt 2722;
BA_ "FlexKomIsMotorola" SG_ 906 VC_FADPrsnt 1;
BA_ "FlexKomComment" SG_ 906 VC_FADPrsnt "Vehicle Configuration 8 Packet";
BA_ "GenSigTimeout_TPM" SG_ 906 VC_HighOctane_PRSNT 21000;
BA_ "GenSigTimeout_ORC" SG_ 906 VC_HighOctane_PRSNT 7000;
BA_ "GenSigTimeout_IC" SG_ 906 VC_HighOctane_PRSNT 21000;
BA_ "GenSigSNA" SG_ 906 VC_HighOctane_PRSNT "0h";
BA_ "GenSigSendType" SG_ 906 VC_HighOctane_PRSNT 5;
BA_ "GenSigCycleTime" SG_ 906 VC_HighOctane_PRSNT 2000;
BA_ "FlexKomSigStartValue" SG_ 906 VC_HighOctane_PRSNT "0300000000000000h";
BA_ "FlexKomSigStartPos" SG_ 906 VC_HighOctane_PRSNT 7;
BA_ "FlexKomSigName" SG_ 906 VC_HighOctane_PRSNT "VehCfg8_Pkt";
BA_ "FlexKomSigLaenge" SG_ 906 VC_HighOctane_PRSNT 64;
BA_ "FlexKomSID" SG_ 906 VC_HighOctane_PRSNT 2722;
BA_ "FlexKomIsMotorola" SG_ 906 VC_HighOctane_PRSNT 1;
BA_ "FlexKomComment" SG_ 906 VC_HighOctane_PRSNT "Vehicle Configuration 8 Packet";
BA_ "GenSigSNA" SG_ 906 VC_INDIA_SPEED_WARNING "0h";
BA_ "GenSigSendType" SG_ 906 VC_INDIA_SPEED_WARNING 5;
BA_ "GenSigCycleTime" SG_ 906 VC_INDIA_SPEED_WARNING 2000;
BA_ "FlexKomSigStartValue" SG_ 906 VC_INDIA_SPEED_WARNING "0300000000000000h";
BA_ "FlexKomSigStartPos" SG_ 906 VC_INDIA_SPEED_WARNING 7;
BA_ "FlexKomSigName" SG_ 906 VC_INDIA_SPEED_WARNING "VehCfg8_Pkt";
BA_ "FlexKomSigLaenge" SG_ 906 VC_INDIA_SPEED_WARNING 64;
BA_ "FlexKomSID" SG_ 906 VC_INDIA_SPEED_WARNING 2722;
BA_ "FlexKomIsMotorola" SG_ 906 VC_INDIA_SPEED_WARNING 1;
BA_ "FlexKomComment" SG_ 906 VC_INDIA_SPEED_WARNING "Vehicle Configuration 8 Packet";
BA_ "GenSigTimeout_RF_HUB" SG_ 906 VC_Increasing_Speed_Constant 10500;
BA_ "GenSigTimeout_IC" SG_ 906 VC_Increasing_Speed_Constant 10500;
BA_ "GenSigSNA" SG_ 906 VC_Increasing_Speed_Constant "0h";
BA_ "GenSigSendType" SG_ 906 VC_Increasing_Speed_Constant 5;
BA_ "GenSigCycleTime" SG_ 906 VC_Increasing_Speed_Constant 2000;
BA_ "FlexKomSigStartValue" SG_ 906 VC_Increasing_Speed_Constant "0300000000000000h";
BA_ "FlexKomSigStartPos" SG_ 906 VC_Increasing_Speed_Constant 7;
BA_ "FlexKomSigName" SG_ 906 VC_Increasing_Speed_Constant "VehCfg8_Pkt";
BA_ "FlexKomSigLaenge" SG_ 906 VC_Increasing_Speed_Constant 64;
BA_ "FlexKomSID" SG_ 906 VC_Increasing_Speed_Constant 2722;
BA_ "FlexKomIsMotorola" SG_ 906 VC_Increasing_Speed_Constant 1;
BA_ "FlexKomComment" SG_ 906 VC_Increasing_Speed_Constant "Vehicle Configuration 8 Packet";
BA_ "GenSigTimeout_TPM" SG_ 906 VC_LineLock_PRSNT 21000;
BA_ "GenSigTimeout_ORC" SG_ 906 VC_LineLock_PRSNT 7000;
BA_ "GenSigTimeout_IC" SG_ 906 VC_LineLock_PRSNT 21000;
BA_ "GenSigSNA" SG_ 906 VC_LineLock_PRSNT "0h";
BA_ "GenSigSendType" SG_ 906 VC_LineLock_PRSNT 5;
BA_ "GenSigCycleTime" SG_ 906 VC_LineLock_PRSNT 2000;
BA_ "FlexKomSigStartValue" SG_ 906 VC_LineLock_PRSNT "0300000000000000h";
BA_ "FlexKomSigStartPos" SG_ 906 VC_LineLock_PRSNT 7;
BA_ "FlexKomSigName" SG_ 906 VC_LineLock_PRSNT "VehCfg8_Pkt";
BA_ "FlexKomSigLaenge" SG_ 906 VC_LineLock_PRSNT 64;
BA_ "FlexKomSID" SG_ 906 VC_LineLock_PRSNT 2722;
BA_ "FlexKomIsMotorola" SG_ 906 VC_LineLock_PRSNT 1;
BA_ "FlexKomComment" SG_ 906 VC_LineLock_PRSNT "Vehicle Configuration 8 Packet";
BA_ "GenSigSNA" SG_ 906 VC_OFFRoadModePrsnt "0h";
BA_ "GenSigSendType" SG_ 906 VC_OFFRoadModePrsnt 5;
BA_ "GenSigCycleTime" SG_ 906 VC_OFFRoadModePrsnt 2000;
BA_ "FlexKomSigStartValue" SG_ 906 VC_OFFRoadModePrsnt "0300000000000000h";
BA_ "FlexKomSigStartPos" SG_ 906 VC_OFFRoadModePrsnt 7;
BA_ "FlexKomSigName" SG_ 906 VC_OFFRoadModePrsnt "VehCfg8_Pkt";
BA_ "FlexKomSigLaenge" SG_ 906 VC_OFFRoadModePrsnt 64;
BA_ "FlexKomSID" SG_ 906 VC_OFFRoadModePrsnt 2722;
BA_ "FlexKomIsMotorola" SG_ 906 VC_OFFRoadModePrsnt 1;
BA_ "FlexKomComment" SG_ 906 VC_OFFRoadModePrsnt "Vehicle Configuration 8 Packet";
BA_ "GenSigSNA" SG_ 906 VC_OFFroad_Camera "0h";
BA_ "GenSigSendType" SG_ 906 VC_OFFroad_Camera 5;
BA_ "GenSigCycleTime" SG_ 906 VC_OFFroad_Camera 2000;
BA_ "FlexKomSigStartValue" SG_ 906 VC_OFFroad_Camera "0300000000000000h";
BA_ "FlexKomSigStartPos" SG_ 906 VC_OFFroad_Camera 7;
BA_ "FlexKomSigName" SG_ 906 VC_OFFroad_Camera "VehCfg8_Pkt";
BA_ "FlexKomSigLaenge" SG_ 906 VC_OFFroad_Camera 64;
BA_ "FlexKomSID" SG_ 906 VC_OFFroad_Camera 2722;
BA_ "FlexKomIsMotorola" SG_ 906 VC_OFFroad_Camera 1;
BA_ "FlexKomComment" SG_ 906 VC_OFFroad_Camera "Vehicle Configuration 8 Packet";
BA_ "GenSigSNA" SG_ 906 VC_OvertakingBan "0h";
BA_ "GenSigSendType" SG_ 906 VC_OvertakingBan 5;
BA_ "GenSigCycleTime" SG_ 906 VC_OvertakingBan 2000;
BA_ "FlexKomSigStartValue" SG_ 906 VC_OvertakingBan "0300000000000000h";
BA_ "FlexKomSigStartPos" SG_ 906 VC_OvertakingBan 7;
BA_ "FlexKomSigName" SG_ 906 VC_OvertakingBan "VehCfg8_Pkt";
BA_ "FlexKomSigLaenge" SG_ 906 VC_OvertakingBan 64;
BA_ "FlexKomSID" SG_ 906 VC_OvertakingBan 2722;
BA_ "FlexKomIsMotorola" SG_ 906 VC_OvertakingBan 1;
BA_ "FlexKomComment" SG_ 906 VC_OvertakingBan "Vehicle Configuration 8 Packet";
BA_ "GenSigSNA" SG_ 906 VC_PEB_PRSNT "0h";
BA_ "GenSigSendType" SG_ 906 VC_PEB_PRSNT 5;
BA_ "GenSigCycleTime" SG_ 906 VC_PEB_PRSNT 2000;
BA_ "FlexKomSigStartValue" SG_ 906 VC_PEB_PRSNT "0300000000000000h";
BA_ "FlexKomSigStartPos" SG_ 906 VC_PEB_PRSNT 7;
BA_ "FlexKomSigName" SG_ 906 VC_PEB_PRSNT "VehCfg8_Pkt";
BA_ "FlexKomSigLaenge" SG_ 906 VC_PEB_PRSNT 64;
BA_ "FlexKomSID" SG_ 906 VC_PEB_PRSNT 2722;
BA_ "FlexKomIsMotorola" SG_ 906 VC_PEB_PRSNT 1;
BA_ "FlexKomComment" SG_ 906 VC_PEB_PRSNT "Vehicle Configuration 8 Packet";
BA_ "GenSigSNA" SG_ 906 VC_PPPAHardBtn "0h";
BA_ "GenSigSendType" SG_ 906 VC_PPPAHardBtn 5;
BA_ "GenSigCycleTime" SG_ 906 VC_PPPAHardBtn 2000;
BA_ "FlexKomSigStartValue" SG_ 906 VC_PPPAHardBtn "0300000000000000h";
BA_ "FlexKomSigStartPos" SG_ 906 VC_PPPAHardBtn 7;
BA_ "FlexKomSigName" SG_ 906 VC_PPPAHardBtn "VehCfg8_Pkt";
BA_ "FlexKomSigLaenge" SG_ 906 VC_PPPAHardBtn 64;
BA_ "FlexKomSID" SG_ 906 VC_PPPAHardBtn 2722;
BA_ "FlexKomIsMotorola" SG_ 906 VC_PPPAHardBtn 1;
BA_ "FlexKomComment" SG_ 906 VC_PPPAHardBtn "Vehicle Configuration 8 Packet";
BA_ "GenSigSNA" SG_ 906 VC_Power_Outlet_Type "0h";
BA_ "GenSigSendType" SG_ 906 VC_Power_Outlet_Type 5;
BA_ "GenSigCycleTime" SG_ 906 VC_Power_Outlet_Type 2000;
BA_ "FlexKomSigStartValue" SG_ 906 VC_Power_Outlet_Type "0300000000000000h";
BA_ "FlexKomSigStartPos" SG_ 906 VC_Power_Outlet_Type 7;
BA_ "FlexKomSigName" SG_ 906 VC_Power_Outlet_Type "VehCfg8_Pkt";
BA_ "FlexKomSigLaenge" SG_ 906 VC_Power_Outlet_Type 64;
BA_ "FlexKomSID" SG_ 906 VC_Power_Outlet_Type 2722;
BA_ "FlexKomIsMotorola" SG_ 906 VC_Power_Outlet_Type 1;
BA_ "FlexKomComment" SG_ 906 VC_Power_Outlet_Type "Vehicle Configuration 8 Packet";
BA_ "GenSigSNA" SG_ 906 VC_SBL_FBL_CORNERING_PRSNT "0h";
BA_ "GenSigSendType" SG_ 906 VC_SBL_FBL_CORNERING_PRSNT 5;
BA_ "GenSigCycleTime" SG_ 906 VC_SBL_FBL_CORNERING_PRSNT 2000;
BA_ "FlexKomSigStartValue" SG_ 906 VC_SBL_FBL_CORNERING_PRSNT "0300000000000000h";
BA_ "FlexKomSigStartPos" SG_ 906 VC_SBL_FBL_CORNERING_PRSNT 7;
BA_ "FlexKomSigName" SG_ 906 VC_SBL_FBL_CORNERING_PRSNT "VehCfg8_Pkt";
BA_ "FlexKomSigLaenge" SG_ 906 VC_SBL_FBL_CORNERING_PRSNT 64;
BA_ "FlexKomSID" SG_ 906 VC_SBL_FBL_CORNERING_PRSNT 2722;
BA_ "FlexKomIsMotorola" SG_ 906 VC_SBL_FBL_CORNERING_PRSNT 1;
BA_ "FlexKomComment" SG_ 906 VC_SBL_FBL_CORNERING_PRSNT "Vehicle Configuration 8 Packet";
BA_ "GenSigTimeout_TPM" SG_ 906 VC_STFA_Prsnt 21000;
BA_ "GenSigTimeout_ORC" SG_ 906 VC_STFA_Prsnt 7000;
BA_ "GenSigTimeout_IC" SG_ 906 VC_STFA_Prsnt 21000;
BA_ "GenSigSNA" SG_ 906 VC_STFA_Prsnt "0h";
BA_ "GenSigSendType" SG_ 906 VC_STFA_Prsnt 5;
BA_ "GenSigCycleTime" SG_ 906 VC_STFA_Prsnt 2000;
BA_ "FlexKomSigStartValue" SG_ 906 VC_STFA_Prsnt "0300000000000000h";
BA_ "FlexKomSigStartPos" SG_ 906 VC_STFA_Prsnt 7;
BA_ "FlexKomSigName" SG_ 906 VC_STFA_Prsnt "VehCfg8_Pkt";
BA_ "FlexKomSigLaenge" SG_ 906 VC_STFA_Prsnt 64;
BA_ "FlexKomSID" SG_ 906 VC_STFA_Prsnt 2722;
BA_ "FlexKomIsMotorola" SG_ 906 VC_STFA_Prsnt 1;
BA_ "FlexKomComment" SG_ 906 VC_STFA_Prsnt "Vehicle Configuration 8 Packet";
BA_ "GenSigTimeout_RF_HUB" SG_ 906 VC_Speedometer_Tolerance 10500;
BA_ "GenSigTimeout_IC" SG_ 906 VC_Speedometer_Tolerance 10500;
BA_ "GenSigSNA" SG_ 906 VC_Speedometer_Tolerance "0h";
BA_ "GenSigSendType" SG_ 906 VC_Speedometer_Tolerance 5;
BA_ "GenSigCycleTime" SG_ 906 VC_Speedometer_Tolerance 2000;
BA_ "FlexKomSigStartValue" SG_ 906 VC_Speedometer_Tolerance "0300000000000000h";
BA_ "FlexKomSigStartPos" SG_ 906 VC_Speedometer_Tolerance 7;
BA_ "FlexKomSigName" SG_ 906 VC_Speedometer_Tolerance "VehCfg8_Pkt";
BA_ "FlexKomSigLaenge" SG_ 906 VC_Speedometer_Tolerance 64;
BA_ "FlexKomSID" SG_ 906 VC_Speedometer_Tolerance 2722;
BA_ "FlexKomIsMotorola" SG_ 906 VC_Speedometer_Tolerance 1;
BA_ "FlexKomComment" SG_ 906 VC_Speedometer_Tolerance "Vehicle Configuration 8 Packet";
BA_ "GenSigTimeout_TPM" SG_ 906 VC_Steering_Cfactor 21000;
BA_ "GenSigTimeout_ORC" SG_ 906 VC_Steering_Cfactor 7000;
BA_ "GenSigTimeout_IC" SG_ 906 VC_Steering_Cfactor 21000;
BA_ "GenSigSNA" SG_ 906 VC_Steering_Cfactor "0h";
BA_ "GenSigSendType" SG_ 906 VC_Steering_Cfactor 5;
BA_ "GenSigCycleTime" SG_ 906 VC_Steering_Cfactor 2000;
BA_ "FlexKomSigStartValue" SG_ 906 VC_Steering_Cfactor "0300000000000000h";
BA_ "FlexKomSigStartPos" SG_ 906 VC_Steering_Cfactor 7;
BA_ "FlexKomSigName" SG_ 906 VC_Steering_Cfactor "VehCfg8_Pkt";
BA_ "FlexKomSigLaenge" SG_ 906 VC_Steering_Cfactor 64;
BA_ "FlexKomSID" SG_ 906 VC_Steering_Cfactor 2722;
BA_ "FlexKomIsMotorola" SG_ 906 VC_Steering_Cfactor 1;
BA_ "FlexKomComment" SG_ 906 VC_Steering_Cfactor "Vehicle Configuration 8 Packet";
BA_ "GenSigSNA" SG_ 906 VC_TACHO_TYPE "0h";
BA_ "GenSigSendType" SG_ 906 VC_TACHO_TYPE 5;
BA_ "GenSigCycleTime" SG_ 906 VC_TACHO_TYPE 2000;
BA_ "FlexKomSigStartValue" SG_ 906 VC_TACHO_TYPE "0300000000000000h";
BA_ "FlexKomSigStartPos" SG_ 906 VC_TACHO_TYPE 7;
BA_ "FlexKomSigName" SG_ 906 VC_TACHO_TYPE "VehCfg8_Pkt";
BA_ "FlexKomSigLaenge" SG_ 906 VC_TACHO_TYPE 64;
BA_ "FlexKomSID" SG_ 906 VC_TACHO_TYPE 2722;
BA_ "FlexKomIsMotorola" SG_ 906 VC_TACHO_TYPE 1;
BA_ "FlexKomComment" SG_ 906 VC_TACHO_TYPE "Vehicle Configuration 8 Packet";
BA_ "GenSigSNA" SG_ 906 VC_TIPL_LOT "0h";
BA_ "GenSigSendType" SG_ 906 VC_TIPL_LOT 5;
BA_ "GenSigCycleTime" SG_ 906 VC_TIPL_LOT 2000;
BA_ "FlexKomSigStartValue" SG_ 906 VC_TIPL_LOT "0300000000000000h";
BA_ "FlexKomSigStartPos" SG_ 906 VC_TIPL_LOT 7;
BA_ "FlexKomSigName" SG_ 906 VC_TIPL_LOT "VehCfg8_Pkt";
BA_ "FlexKomSigLaenge" SG_ 906 VC_TIPL_LOT 64;
BA_ "FlexKomSID" SG_ 906 VC_TIPL_LOT 2722;
BA_ "FlexKomIsMotorola" SG_ 906 VC_TIPL_LOT 1;
BA_ "FlexKomComment" SG_ 906 VC_TIPL_LOT "Vehicle Configuration 8 Packet";
BA_ "GenSigSNA" SG_ 906 VC_TLC_PRSNT "0h";
BA_ "GenSigSendType" SG_ 906 VC_TLC_PRSNT 5;
BA_ "GenSigCycleTime" SG_ 906 VC_TLC_PRSNT 2000;
BA_ "FlexKomSigStartValue" SG_ 906 VC_TLC_PRSNT "0300000000000000h";
BA_ "FlexKomSigStartPos" SG_ 906 VC_TLC_PRSNT 7;
BA_ "FlexKomSigName" SG_ 906 VC_TLC_PRSNT "VehCfg8_Pkt";
BA_ "FlexKomSigLaenge" SG_ 906 VC_TLC_PRSNT 64;
BA_ "FlexKomSID" SG_ 906 VC_TLC_PRSNT 2722;
BA_ "FlexKomIsMotorola" SG_ 906 VC_TLC_PRSNT 1;
BA_ "FlexKomComment" SG_ 906 VC_TLC_PRSNT "Vehicle Configuration 8 Packet";
BA_ "GenSigTimeout_TPM" SG_ 906 VC_Trans_Brake_PRSNT 21000;
BA_ "GenSigTimeout_ORC" SG_ 906 VC_Trans_Brake_PRSNT 7000;
BA_ "GenSigTimeout_IC" SG_ 906 VC_Trans_Brake_PRSNT 21000;
BA_ "GenSigSNA" SG_ 906 VC_Trans_Brake_PRSNT "0h";
BA_ "GenSigSendType" SG_ 906 VC_Trans_Brake_PRSNT 5;
BA_ "GenSigCycleTime" SG_ 906 VC_Trans_Brake_PRSNT 2000;
BA_ "FlexKomSigStartValue" SG_ 906 VC_Trans_Brake_PRSNT "0300000000000000h";
BA_ "FlexKomSigStartPos" SG_ 906 VC_Trans_Brake_PRSNT 7;
BA_ "FlexKomSigName" SG_ 906 VC_Trans_Brake_PRSNT "VehCfg8_Pkt";
BA_ "FlexKomSigLaenge" SG_ 906 VC_Trans_Brake_PRSNT 64;
BA_ "FlexKomSID" SG_ 906 VC_Trans_Brake_PRSNT 2722;
BA_ "FlexKomIsMotorola" SG_ 906 VC_Trans_Brake_PRSNT 1;
BA_ "FlexKomComment" SG_ 906 VC_Trans_Brake_PRSNT "Vehicle Configuration 8 Packet";
BA_ "GenSigSendType" SG_ 906 VC_VP_Level 5;
BA_ "GenSigCycleTime" SG_ 906 VC_VP_Level 2000;
BA_ "FlexKomSigStartValue" SG_ 906 VC_VP_Level "0300000000000000h";
BA_ "FlexKomSigStartPos" SG_ 906 VC_VP_Level 7;
BA_ "FlexKomSigName" SG_ 906 VC_VP_Level "VehCfg8_Pkt";
BA_ "FlexKomSigLaenge" SG_ 906 VC_VP_Level 64;
BA_ "FlexKomSID" SG_ 906 VC_VP_Level 2722;
BA_ "FlexKomIsMotorola" SG_ 906 VC_VP_Level 1;
BA_ "FlexKomComment" SG_ 906 VC_VP_Level "Vehicle Configuration 8 Packet";
BA_ "GenSigTimeout_TPM" SG_ 906 VC_VehCfg8_Stat 21000;
BA_ "GenSigTimeout_ORC" SG_ 906 VC_VehCfg8_Stat 7000;
BA_ "GenSigTimeout_IC" SG_ 906 VC_VehCfg8_Stat 21000;
BA_ "GenSigStartValue" SG_ 906 VC_VehCfg8_Stat 3;
BA_ "GenSigSNA" SG_ 906 VC_VehCfg8_Stat "3h";
BA_ "GenSigSendType" SG_ 906 VC_VehCfg8_Stat 5;
BA_ "GenSigCycleTime" SG_ 906 VC_VehCfg8_Stat 2000;
BA_ "FlexKomSigStartValue" SG_ 906 VC_VehCfg8_Stat "0300000000000000h";
BA_ "FlexKomSigStartPos" SG_ 906 VC_VehCfg8_Stat 7;
BA_ "FlexKomSigName" SG_ 906 VC_VehCfg8_Stat "VehCfg8_Pkt";
BA_ "FlexKomSigLaenge" SG_ 906 VC_VehCfg8_Stat 64;
BA_ "FlexKomSID" SG_ 906 VC_VehCfg8_Stat 2722;
BA_ "FlexKomIsMotorola" SG_ 906 VC_VehCfg8_Stat 1;
BA_ "FlexKomComment" SG_ 906 VC_VehCfg8_Stat "Vehicle Configuration 8 Packet";
BA_ "GenSigSendType" SG_ 906 VC_WHL_BASE_LENGTH 5;
BA_ "GenSigCycleTime" SG_ 906 VC_WHL_BASE_LENGTH 2000;
BA_ "FlexKomSigStartValue" SG_ 906 VC_WHL_BASE_LENGTH "0300000000000000h";
BA_ "FlexKomSigStartPos" SG_ 906 VC_WHL_BASE_LENGTH 7;
BA_ "FlexKomSigName" SG_ 906 VC_WHL_BASE_LENGTH "VehCfg8_Pkt";
BA_ "FlexKomSigLaenge" SG_ 906 VC_WHL_BASE_LENGTH 64;
BA_ "FlexKomSID" SG_ 906 VC_WHL_BASE_LENGTH 2722;
BA_ "FlexKomIsMotorola" SG_ 906 VC_WHL_BASE_LENGTH 1;
BA_ "FlexKomComment" SG_ 906 VC_WHL_BASE_LENGTH "Vehicle Configuration 8 Packet";
BA_ "GenSigSNA" SG_ 1004 VC_BU_AUTO_HB "0h";
BA_ "GenSigSendType" SG_ 1004 VC_BU_AUTO_HB 1;
BA_ "FlexKomSigStartValue" SG_ 1004 VC_BU_AUTO_HB "FFFF7FF0FF0FFF00h";
BA_ "FlexKomSigStartPos" SG_ 1004 VC_BU_AUTO_HB 7;
BA_ "FlexKomSigName" SG_ 1004 VC_BU_AUTO_HB "VehCfgBU1_Pkt";
BA_ "FlexKomSigLaenge" SG_ 1004 VC_BU_AUTO_HB 64;
BA_ "FlexKomSID" SG_ 1004 VC_BU_AUTO_HB 919;
BA_ "FlexKomIsMotorola" SG_ 1004 VC_BU_AUTO_HB 1;
BA_ "FlexKomComment" SG_ 1004 VC_BU_AUTO_HB "Backup for Vehicle Configuration 1 Packet";
BA_ "GenSigStartValue" SG_ 1004 VC_BU_BODY_STYLE 15;
BA_ "GenSigSNA" SG_ 1004 VC_BU_BODY_STYLE "Fh";
BA_ "GenSigSendType" SG_ 1004 VC_BU_BODY_STYLE 1;
BA_ "FlexKomSigStartValue" SG_ 1004 VC_BU_BODY_STYLE "FFFF7FF0FF0FFF00h";
BA_ "FlexKomSigStartPos" SG_ 1004 VC_BU_BODY_STYLE 7;
BA_ "FlexKomSigName" SG_ 1004 VC_BU_BODY_STYLE "VehCfgBU1_Pkt";
BA_ "FlexKomSigLaenge" SG_ 1004 VC_BU_BODY_STYLE 64;
BA_ "FlexKomSID" SG_ 1004 VC_BU_BODY_STYLE 919;
BA_ "FlexKomIsMotorola" SG_ 1004 VC_BU_BODY_STYLE 1;
BA_ "FlexKomComment" SG_ 1004 VC_BU_BODY_STYLE "Backup for Vehicle Configuration 1 Packet";
BA_ "GenSigSNA" SG_ 1004 VC_BU_CHMCM_Prsnt "0h";
BA_ "GenSigSendType" SG_ 1004 VC_BU_CHMCM_Prsnt 1;
BA_ "FlexKomSigStartValue" SG_ 1004 VC_BU_CHMCM_Prsnt "FFFF7FF0FF0FFF00h";
BA_ "FlexKomSigStartPos" SG_ 1004 VC_BU_CHMCM_Prsnt 7;
BA_ "FlexKomSigName" SG_ 1004 VC_BU_CHMCM_Prsnt "VehCfgBU1_Pkt";
BA_ "FlexKomSigLaenge" SG_ 1004 VC_BU_CHMCM_Prsnt 64;
BA_ "FlexKomSID" SG_ 1004 VC_BU_CHMCM_Prsnt 919;
BA_ "FlexKomIsMotorola" SG_ 1004 VC_BU_CHMCM_Prsnt 1;
BA_ "FlexKomComment" SG_ 1004 VC_BU_CHMCM_Prsnt "Backup for Vehicle Configuration 1 Packet";
BA_ "GenSigStartValue" SG_ 1004 VC_BU_COUNTRY 31;
BA_ "GenSigSNA" SG_ 1004 VC_BU_COUNTRY "1Fh";
BA_ "GenSigSendType" SG_ 1004 VC_BU_COUNTRY 1;
BA_ "FlexKomSigStartValue" SG_ 1004 VC_BU_COUNTRY "FFFF7FF0FF0FFF00h";
BA_ "FlexKomSigStartPos" SG_ 1004 VC_BU_COUNTRY 7;
BA_ "FlexKomSigName" SG_ 1004 VC_BU_COUNTRY "VehCfgBU1_Pkt";
BA_ "FlexKomSigLaenge" SG_ 1004 VC_BU_COUNTRY 64;
BA_ "FlexKomSID" SG_ 1004 VC_BU_COUNTRY 919;
BA_ "FlexKomIsMotorola" SG_ 1004 VC_BU_COUNTRY 1;
BA_ "FlexKomComment" SG_ 1004 VC_BU_COUNTRY "Backup for Vehicle Configuration 1 Packet";
BA_ "GenSigSNA" SG_ 1004 VC_BU_EmodePrsnt "0h";
BA_ "GenSigSendType" SG_ 1004 VC_BU_EmodePrsnt 1;
BA_ "FlexKomSigStartValue" SG_ 1004 VC_BU_EmodePrsnt "FFFF7FF0FF0FFF00h";
BA_ "FlexKomSigStartPos" SG_ 1004 VC_BU_EmodePrsnt 7;
BA_ "FlexKomSigName" SG_ 1004 VC_BU_EmodePrsnt "VehCfgBU1_Pkt";
BA_ "FlexKomSigLaenge" SG_ 1004 VC_BU_EmodePrsnt 64;
BA_ "FlexKomSID" SG_ 1004 VC_BU_EmodePrsnt 919;
BA_ "FlexKomIsMotorola" SG_ 1004 VC_BU_EmodePrsnt 1;
BA_ "FlexKomComment" SG_ 1004 VC_BU_EmodePrsnt "Backup for Vehicle Configuration 1 Packet";
BA_ "GenSigSNA" SG_ 1004 VC_BU_HDC_Prsnt "0h";
BA_ "GenSigSendType" SG_ 1004 VC_BU_HDC_Prsnt 1;
BA_ "FlexKomSigStartValue" SG_ 1004 VC_BU_HDC_Prsnt "FFFF7FF0FF0FFF00h";
BA_ "FlexKomSigStartPos" SG_ 1004 VC_BU_HDC_Prsnt 7;
BA_ "FlexKomSigName" SG_ 1004 VC_BU_HDC_Prsnt "VehCfgBU1_Pkt";
BA_ "FlexKomSigLaenge" SG_ 1004 VC_BU_HDC_Prsnt 64;
BA_ "FlexKomSID" SG_ 1004 VC_BU_HDC_Prsnt 919;
BA_ "FlexKomIsMotorola" SG_ 1004 VC_BU_HDC_Prsnt 1;
BA_ "FlexKomComment" SG_ 1004 VC_BU_HDC_Prsnt "Backup for Vehicle Configuration 1 Packet";
BA_ "GenSigSNA" SG_ 1004 VC_BU_HdRstPrsnt "0h";
BA_ "GenSigSendType" SG_ 1004 VC_BU_HdRstPrsnt 1;
BA_ "FlexKomSigStartValue" SG_ 1004 VC_BU_HdRstPrsnt "FFFF7FF0FF0FFF00h";
BA_ "FlexKomSigStartPos" SG_ 1004 VC_BU_HdRstPrsnt 7;
BA_ "FlexKomSigName" SG_ 1004 VC_BU_HdRstPrsnt "VehCfgBU1_Pkt";
BA_ "FlexKomSigLaenge" SG_ 1004 VC_BU_HdRstPrsnt 64;
BA_ "FlexKomSID" SG_ 1004 VC_BU_HdRstPrsnt 919;
BA_ "FlexKomIsMotorola" SG_ 1004 VC_BU_HdRstPrsnt 1;
BA_ "FlexKomComment" SG_ 1004 VC_BU_HdRstPrsnt "Backup for Vehicle Configuration 1 Packet";
BA_ "GenSigStartValue" SG_ 1004 VC_BU_LHD_RHD 3;
BA_ "GenSigSNA" SG_ 1004 VC_BU_LHD_RHD "3h";
BA_ "GenSigSendType" SG_ 1004 VC_BU_LHD_RHD 1;
BA_ "FlexKomSigStartValue" SG_ 1004 VC_BU_LHD_RHD "FFFF7FF0FF0FFF00h";
BA_ "FlexKomSigStartPos" SG_ 1004 VC_BU_LHD_RHD 7;
BA_ "FlexKomSigName" SG_ 1004 VC_BU_LHD_RHD "VehCfgBU1_Pkt";
BA_ "FlexKomSigLaenge" SG_ 1004 VC_BU_LHD_RHD 64;
BA_ "FlexKomSID" SG_ 1004 VC_BU_LHD_RHD 919;
BA_ "FlexKomIsMotorola" SG_ 1004 VC_BU_LHD_RHD 1;
BA_ "FlexKomComment" SG_ 1004 VC_BU_LHD_RHD "Backup for Vehicle Configuration 1 Packet";
BA_ "GenSigStartValue" SG_ 1004 VC_BU_MAX_VEH_SPD 255;
BA_ "GenSigSNA" SG_ 1004 VC_BU_MAX_VEH_SPD "FFh";
BA_ "GenSigSendType" SG_ 1004 VC_BU_MAX_VEH_SPD 1;
BA_ "FlexKomSigStartValue" SG_ 1004 VC_BU_MAX_VEH_SPD "FFFF7FF0FF0FFF00h";
BA_ "FlexKomSigStartPos" SG_ 1004 VC_BU_MAX_VEH_SPD 7;
BA_ "FlexKomSigName" SG_ 1004 VC_BU_MAX_VEH_SPD "VehCfgBU1_Pkt";
BA_ "FlexKomSigLaenge" SG_ 1004 VC_BU_MAX_VEH_SPD 64;
BA_ "FlexKomSID" SG_ 1004 VC_BU_MAX_VEH_SPD 919;
BA_ "FlexKomIsMotorola" SG_ 1004 VC_BU_MAX_VEH_SPD 1;
BA_ "FlexKomComment" SG_ 1004 VC_BU_MAX_VEH_SPD "Backup for Vehicle Configuration 1 Packet";
BA_ "GenSigStartValue" SG_ 1004 VC_BU_MODEL_YEAR 63;
BA_ "GenSigSNA" SG_ 1004 VC_BU_MODEL_YEAR "3Fh";
BA_ "GenSigSendType" SG_ 1004 VC_BU_MODEL_YEAR 1;
BA_ "FlexKomSigStartValue" SG_ 1004 VC_BU_MODEL_YEAR "FFFF7FF0FF0FFF00h";
BA_ "FlexKomSigStartPos" SG_ 1004 VC_BU_MODEL_YEAR 7;
BA_ "FlexKomSigName" SG_ 1004 VC_BU_MODEL_YEAR "VehCfgBU1_Pkt";
BA_ "FlexKomSigLaenge" SG_ 1004 VC_BU_MODEL_YEAR 64;
BA_ "FlexKomSID" SG_ 1004 VC_BU_MODEL_YEAR 919;
BA_ "FlexKomIsMotorola" SG_ 1004 VC_BU_MODEL_YEAR 1;
BA_ "FlexKomComment" SG_ 1004 VC_BU_MODEL_YEAR "Backup for Vehicle Configuration 1 Packet";
BA_ "GenSigSNA" SG_ 1004 VC_BU_PP_Prsnt "0h";
BA_ "GenSigSendType" SG_ 1004 VC_BU_PP_Prsnt 1;
BA_ "FlexKomSigStartValue" SG_ 1004 VC_BU_PP_Prsnt "FFFF7FF0FF0FFF00h";
BA_ "FlexKomSigStartPos" SG_ 1004 VC_BU_PP_Prsnt 7;
BA_ "FlexKomSigName" SG_ 1004 VC_BU_PP_Prsnt "VehCfgBU1_Pkt";
BA_ "FlexKomSigLaenge" SG_ 1004 VC_BU_PP_Prsnt 64;
BA_ "FlexKomSID" SG_ 1004 VC_BU_PP_Prsnt 919;
BA_ "FlexKomIsMotorola" SG_ 1004 VC_BU_PP_Prsnt 1;
BA_ "FlexKomComment" SG_ 1004 VC_BU_PP_Prsnt "Backup for Vehicle Configuration 1 Packet";
BA_ "GenSigSNA" SG_ 1004 VC_BU_PTS_Config "0h";
BA_ "GenSigSendType" SG_ 1004 VC_BU_PTS_Config 1;
BA_ "FlexKomSigStartValue" SG_ 1004 VC_BU_PTS_Config "FFFF7FF0FF0FFF00h";
BA_ "FlexKomSigStartPos" SG_ 1004 VC_BU_PTS_Config 7;
BA_ "FlexKomSigName" SG_ 1004 VC_BU_PTS_Config "VehCfgBU1_Pkt";
BA_ "FlexKomSigLaenge" SG_ 1004 VC_BU_PTS_Config 64;
BA_ "FlexKomSID" SG_ 1004 VC_BU_PTS_Config 919;
BA_ "FlexKomIsMotorola" SG_ 1004 VC_BU_PTS_Config 1;
BA_ "FlexKomComment" SG_ 1004 VC_BU_PTS_Config "Backup for Vehicle Configuration 1 Packet";
BA_ "GenSigSNA" SG_ 1004 VC_BU_PTS_DispTyp "7h";
BA_ "GenSigSendType" SG_ 1004 VC_BU_PTS_DispTyp 1;
BA_ "FlexKomSigStartValue" SG_ 1004 VC_BU_PTS_DispTyp "FFFF7FF0FF0FFF00h";
BA_ "FlexKomSigStartPos" SG_ 1004 VC_BU_PTS_DispTyp 7;
BA_ "FlexKomSigName" SG_ 1004 VC_BU_PTS_DispTyp "VehCfgBU1_Pkt";
BA_ "FlexKomSigLaenge" SG_ 1004 VC_BU_PTS_DispTyp 64;
BA_ "FlexKomSID" SG_ 1004 VC_BU_PTS_DispTyp 919;
BA_ "FlexKomIsMotorola" SG_ 1004 VC_BU_PTS_DispTyp 1;
BA_ "FlexKomComment" SG_ 1004 VC_BU_PTS_DispTyp "Backup for Vehicle Configuration 1 Packet";
BA_ "GenSigSNA" SG_ 1004 VC_BU_RVCM_Prsnt "0h";
BA_ "GenSigSendType" SG_ 1004 VC_BU_RVCM_Prsnt 1;
BA_ "FlexKomSigStartValue" SG_ 1004 VC_BU_RVCM_Prsnt "FFFF7FF0FF0FFF00h";
BA_ "FlexKomSigStartPos" SG_ 1004 VC_BU_RVCM_Prsnt 7;
BA_ "FlexKomSigName" SG_ 1004 VC_BU_RVCM_Prsnt "VehCfgBU1_Pkt";
BA_ "FlexKomSigLaenge" SG_ 1004 VC_BU_RVCM_Prsnt 64;
BA_ "FlexKomSID" SG_ 1004 VC_BU_RVCM_Prsnt 919;
BA_ "FlexKomIsMotorola" SG_ 1004 VC_BU_RVCM_Prsnt 1;
BA_ "FlexKomComment" SG_ 1004 VC_BU_RVCM_Prsnt "Backup for Vehicle Configuration 1 Packet";
BA_ "GenSigSNA" SG_ 1004 VC_BU_RemStPrsnt "0h";
BA_ "GenSigSendType" SG_ 1004 VC_BU_RemStPrsnt 1;
BA_ "FlexKomSigStartValue" SG_ 1004 VC_BU_RemStPrsnt "FFFF7FF0FF0FFF00h";
BA_ "FlexKomSigStartPos" SG_ 1004 VC_BU_RemStPrsnt 7;
BA_ "FlexKomSigName" SG_ 1004 VC_BU_RemStPrsnt "VehCfgBU1_Pkt";
BA_ "FlexKomSigLaenge" SG_ 1004 VC_BU_RemStPrsnt 64;
BA_ "FlexKomSID" SG_ 1004 VC_BU_RemStPrsnt 919;
BA_ "FlexKomIsMotorola" SG_ 1004 VC_BU_RemStPrsnt 1;
BA_ "FlexKomComment" SG_ 1004 VC_BU_RemStPrsnt "Backup for Vehicle Configuration 1 Packet";
BA_ "GenSigSNA" SG_ 1004 VC_BU_SCR_Prsnt "0h";
BA_ "GenSigSendType" SG_ 1004 VC_BU_SCR_Prsnt 1;
BA_ "FlexKomSigStartValue" SG_ 1004 VC_BU_SCR_Prsnt "FFFF7FF0FF0FFF00h";
BA_ "FlexKomSigStartPos" SG_ 1004 VC_BU_SCR_Prsnt 7;
BA_ "FlexKomSigName" SG_ 1004 VC_BU_SCR_Prsnt "VehCfgBU1_Pkt";
BA_ "FlexKomSigLaenge" SG_ 1004 VC_BU_SCR_Prsnt 64;
BA_ "FlexKomSID" SG_ 1004 VC_BU_SCR_Prsnt 919;
BA_ "FlexKomIsMotorola" SG_ 1004 VC_BU_SCR_Prsnt 1;
BA_ "FlexKomComment" SG_ 1004 VC_BU_SCR_Prsnt "Backup for Vehicle Configuration 1 Packet";
BA_ "GenSigSNA" SG_ 1004 VC_BU_SSC_Prsnt "0h";
BA_ "GenSigSendType" SG_ 1004 VC_BU_SSC_Prsnt 1;
BA_ "FlexKomSigStartValue" SG_ 1004 VC_BU_SSC_Prsnt "FFFF7FF0FF0FFF00h";
BA_ "FlexKomSigStartPos" SG_ 1004 VC_BU_SSC_Prsnt 7;
BA_ "FlexKomSigName" SG_ 1004 VC_BU_SSC_Prsnt "VehCfgBU1_Pkt";
BA_ "FlexKomSigLaenge" SG_ 1004 VC_BU_SSC_Prsnt 64;
BA_ "FlexKomSID" SG_ 1004 VC_BU_SSC_Prsnt 919;
BA_ "FlexKomIsMotorola" SG_ 1004 VC_BU_SSC_Prsnt 1;
BA_ "FlexKomComment" SG_ 1004 VC_BU_SSC_Prsnt "Backup for Vehicle Configuration 1 Packet";
BA_ "GenSigStartValue" SG_ 1004 VC_BU_ShftrTyp 15;
BA_ "GenSigSNA" SG_ 1004 VC_BU_ShftrTyp "Fh";
BA_ "GenSigSendType" SG_ 1004 VC_BU_ShftrTyp 1;
BA_ "FlexKomSigStartValue" SG_ 1004 VC_BU_ShftrTyp "FFFF7FF0FF0FFF00h";
BA_ "FlexKomSigStartPos" SG_ 1004 VC_BU_ShftrTyp 7;
BA_ "FlexKomSigName" SG_ 1004 VC_BU_ShftrTyp "VehCfgBU1_Pkt";
BA_ "FlexKomSigLaenge" SG_ 1004 VC_BU_ShftrTyp 64;
BA_ "FlexKomSID" SG_ 1004 VC_BU_ShftrTyp 919;
BA_ "FlexKomIsMotorola" SG_ 1004 VC_BU_ShftrTyp 1;
BA_ "FlexKomComment" SG_ 1004 VC_BU_ShftrTyp "Backup for Vehicle Configuration 1 Packet";
BA_ "GenSigStartValue" SG_ 1004 VC_BU_SpecialPKG 255;
BA_ "GenSigSNA" SG_ 1004 VC_BU_SpecialPKG "FFh";
BA_ "GenSigSendType" SG_ 1004 VC_BU_SpecialPKG 1;
BA_ "FlexKomSigStartValue" SG_ 1004 VC_BU_SpecialPKG "FFFF7FF0FF0FFF00h";
BA_ "FlexKomSigStartPos" SG_ 1004 VC_BU_SpecialPKG 7;
BA_ "FlexKomSigName" SG_ 1004 VC_BU_SpecialPKG "VehCfgBU1_Pkt";
BA_ "FlexKomSigLaenge" SG_ 1004 VC_BU_SpecialPKG 64;
BA_ "FlexKomSID" SG_ 1004 VC_BU_SpecialPKG 919;
BA_ "FlexKomIsMotorola" SG_ 1004 VC_BU_SpecialPKG 1;
BA_ "FlexKomComment" SG_ 1004 VC_BU_SpecialPKG "Backup for Vehicle Configuration 1 Packet";
BA_ "GenSigStartValue" SG_ 1004 VC_BU_VEH_LINE 255;
BA_ "GenSigSNA" SG_ 1004 VC_BU_VEH_LINE "FFh";
BA_ "GenSigSendType" SG_ 1004 VC_BU_VEH_LINE 1;
BA_ "FlexKomSigStartValue" SG_ 1004 VC_BU_VEH_LINE "FFFF7FF0FF0FFF00h";
BA_ "FlexKomSigStartPos" SG_ 1004 VC_BU_VEH_LINE 7;
BA_ "FlexKomSigName" SG_ 1004 VC_BU_VEH_LINE "VehCfgBU1_Pkt";
BA_ "FlexKomSigLaenge" SG_ 1004 VC_BU_VEH_LINE 64;
BA_ "FlexKomSID" SG_ 1004 VC_BU_VEH_LINE 919;
BA_ "FlexKomIsMotorola" SG_ 1004 VC_BU_VEH_LINE 1;
BA_ "FlexKomComment" SG_ 1004 VC_BU_VEH_LINE "Backup for Vehicle Configuration 1 Packet";
BA_ "GenSigStartValue" SG_ 1004 VC_BU_VehCfg1_Stat 3;
BA_ "GenSigSNA" SG_ 1004 VC_BU_VehCfg1_Stat "3h";
BA_ "GenSigSendType" SG_ 1004 VC_BU_VehCfg1_Stat 1;
BA_ "FlexKomSigStartValue" SG_ 1004 VC_BU_VehCfg1_Stat "FFFF7FF0FF0FFF00h";
BA_ "FlexKomSigStartPos" SG_ 1004 VC_BU_VehCfg1_Stat 7;
BA_ "FlexKomSigName" SG_ 1004 VC_BU_VehCfg1_Stat "VehCfgBU1_Pkt";
BA_ "FlexKomSigLaenge" SG_ 1004 VC_BU_VehCfg1_Stat 64;
BA_ "FlexKomSID" SG_ 1004 VC_BU_VehCfg1_Stat 919;
BA_ "FlexKomIsMotorola" SG_ 1004 VC_BU_VehCfg1_Stat 1;
BA_ "FlexKomComment" SG_ 1004 VC_BU_VehCfg1_Stat "Backup for Vehicle Configuration 1 Packet";
BA_ "GenSigSNA" SG_ 1004 VC_BU_XWD "0h";
BA_ "GenSigSendType" SG_ 1004 VC_BU_XWD 1;
BA_ "FlexKomSigStartValue" SG_ 1004 VC_BU_XWD "FFFF7FF0FF0FFF00h";
BA_ "FlexKomSigStartPos" SG_ 1004 VC_BU_XWD 7;
BA_ "FlexKomSigName" SG_ 1004 VC_BU_XWD "VehCfgBU1_Pkt";
BA_ "FlexKomSigLaenge" SG_ 1004 VC_BU_XWD 64;
BA_ "FlexKomSID" SG_ 1004 VC_BU_XWD 919;
BA_ "FlexKomIsMotorola" SG_ 1004 VC_BU_XWD 1;
BA_ "FlexKomComment" SG_ 1004 VC_BU_XWD "Backup for Vehicle Configuration 1 Packet";
BA_ "GenSigSNA" SG_ 1005 VC_BU_AC_Prsnt "0h";
BA_ "GenSigSendType" SG_ 1005 VC_BU_AC_Prsnt 1;
BA_ "FlexKomSigStartValue" SG_ 1005 VC_BU_AC_Prsnt "0300FF00FFFFFFFFh";
BA_ "FlexKomSigStartPos" SG_ 1005 VC_BU_AC_Prsnt 7;
BA_ "FlexKomSigName" SG_ 1005 VC_BU_AC_Prsnt "VehCfgBu2_Pkt";
BA_ "FlexKomSigLaenge" SG_ 1005 VC_BU_AC_Prsnt 64;
BA_ "FlexKomSID" SG_ 1005 VC_BU_AC_Prsnt 920;
BA_ "FlexKomIsMotorola" SG_ 1005 VC_BU_AC_Prsnt 1;
BA_ "FlexKomComment" SG_ 1005 VC_BU_AC_Prsnt "Vehicle Configuration Backup 2 Packet";
BA_ "GenSigSNA" SG_ 1005 VC_BU_CRUISE_PRSNT "0h";
BA_ "GenSigSendType" SG_ 1005 VC_BU_CRUISE_PRSNT 1;
BA_ "FlexKomSigStartValue" SG_ 1005 VC_BU_CRUISE_PRSNT "0300FF00FFFFFFFFh";
BA_ "FlexKomSigStartPos" SG_ 1005 VC_BU_CRUISE_PRSNT 7;
BA_ "FlexKomSigName" SG_ 1005 VC_BU_CRUISE_PRSNT "VehCfgBu2_Pkt";
BA_ "FlexKomSigLaenge" SG_ 1005 VC_BU_CRUISE_PRSNT 64;
BA_ "FlexKomSID" SG_ 1005 VC_BU_CRUISE_PRSNT 920;
BA_ "FlexKomIsMotorola" SG_ 1005 VC_BU_CRUISE_PRSNT 1;
BA_ "FlexKomComment" SG_ 1005 VC_BU_CRUISE_PRSNT "Vehicle Configuration Backup 2 Packet";
BA_ "GenSigSNA" SG_ 1005 VC_BU_DRVMD_Prsnt "0h";
BA_ "GenSigSendType" SG_ 1005 VC_BU_DRVMD_Prsnt 1;
BA_ "FlexKomSigStartValue" SG_ 1005 VC_BU_DRVMD_Prsnt "0300FF00FFFFFFFFh";
BA_ "FlexKomSigStartPos" SG_ 1005 VC_BU_DRVMD_Prsnt 7;
BA_ "FlexKomSigName" SG_ 1005 VC_BU_DRVMD_Prsnt "VehCfgBu2_Pkt";
BA_ "FlexKomSigLaenge" SG_ 1005 VC_BU_DRVMD_Prsnt 64;
BA_ "FlexKomSID" SG_ 1005 VC_BU_DRVMD_Prsnt 920;
BA_ "FlexKomIsMotorola" SG_ 1005 VC_BU_DRVMD_Prsnt 1;
BA_ "FlexKomComment" SG_ 1005 VC_BU_DRVMD_Prsnt "Vehicle Configuration Backup 2 Packet";
BA_ "GenSigSNA" SG_ 1005 VC_BU_ECO_Indicator "0h";
BA_ "GenSigSendType" SG_ 1005 VC_BU_ECO_Indicator 1;
BA_ "FlexKomSigStartValue" SG_ 1005 VC_BU_ECO_Indicator "0300FF00FFFFFFFFh";
BA_ "FlexKomSigStartPos" SG_ 1005 VC_BU_ECO_Indicator 7;
BA_ "FlexKomSigName" SG_ 1005 VC_BU_ECO_Indicator "VehCfgBu2_Pkt";
BA_ "FlexKomSigLaenge" SG_ 1005 VC_BU_ECO_Indicator 64;
BA_ "FlexKomSID" SG_ 1005 VC_BU_ECO_Indicator 920;
BA_ "FlexKomIsMotorola" SG_ 1005 VC_BU_ECO_Indicator 1;
BA_ "FlexKomComment" SG_ 1005 VC_BU_ECO_Indicator "Vehicle Configuration Backup 2 Packet";
BA_ "GenSigSNA" SG_ 1005 VC_BU_ESCDrvMd_Prsnt "0h";
BA_ "GenSigSendType" SG_ 1005 VC_BU_ESCDrvMd_Prsnt 1;
BA_ "FlexKomSigStartValue" SG_ 1005 VC_BU_ESCDrvMd_Prsnt "0300FF00FFFFFFFFh";
BA_ "FlexKomSigStartPos" SG_ 1005 VC_BU_ESCDrvMd_Prsnt 7;
BA_ "FlexKomSigName" SG_ 1005 VC_BU_ESCDrvMd_Prsnt "VehCfgBu2_Pkt";
BA_ "FlexKomSigLaenge" SG_ 1005 VC_BU_ESCDrvMd_Prsnt 64;
BA_ "FlexKomSID" SG_ 1005 VC_BU_ESCDrvMd_Prsnt 920;
BA_ "FlexKomIsMotorola" SG_ 1005 VC_BU_ESCDrvMd_Prsnt 1;
BA_ "FlexKomComment" SG_ 1005 VC_BU_ESCDrvMd_Prsnt "Vehicle Configuration Backup 2 Packet";
BA_ "GenSigSNA" SG_ 1005 VC_BU_EngPowerDrvMd_Prsnt "0h";
BA_ "GenSigSendType" SG_ 1005 VC_BU_EngPowerDrvMd_Prsnt 1;
BA_ "FlexKomSigStartValue" SG_ 1005 VC_BU_EngPowerDrvMd_Prsnt "0300FF00FFFFFFFFh";
BA_ "FlexKomSigStartPos" SG_ 1005 VC_BU_EngPowerDrvMd_Prsnt 7;
BA_ "FlexKomSigName" SG_ 1005 VC_BU_EngPowerDrvMd_Prsnt "VehCfgBu2_Pkt";
BA_ "FlexKomSigLaenge" SG_ 1005 VC_BU_EngPowerDrvMd_Prsnt 64;
BA_ "FlexKomSID" SG_ 1005 VC_BU_EngPowerDrvMd_Prsnt 920;
BA_ "FlexKomIsMotorola" SG_ 1005 VC_BU_EngPowerDrvMd_Prsnt 1;
BA_ "FlexKomComment" SG_ 1005 VC_BU_EngPowerDrvMd_Prsnt "Vehicle Configuration Backup 2 Packet";
BA_ "GenSigSNA" SG_ 1005 VC_BU_FG_PRSNT "0h";
BA_ "GenSigSendType" SG_ 1005 VC_BU_FG_PRSNT 1;
BA_ "FlexKomSigStartValue" SG_ 1005 VC_BU_FG_PRSNT "0300FF00FFFFFFFFh";
BA_ "FlexKomSigStartPos" SG_ 1005 VC_BU_FG_PRSNT 7;
BA_ "FlexKomSigName" SG_ 1005 VC_BU_FG_PRSNT "VehCfgBu2_Pkt";
BA_ "FlexKomSigLaenge" SG_ 1005 VC_BU_FG_PRSNT 64;
BA_ "FlexKomSID" SG_ 1005 VC_BU_FG_PRSNT 920;
BA_ "FlexKomIsMotorola" SG_ 1005 VC_BU_FG_PRSNT 1;
BA_ "FlexKomComment" SG_ 1005 VC_BU_FG_PRSNT "Vehicle Configuration Backup 2 Packet";
BA_ "GenSigSNA" SG_ 1005 VC_BU_FULL_SPARE "0h";
BA_ "GenSigSendType" SG_ 1005 VC_BU_FULL_SPARE 1;
BA_ "FlexKomSigStartValue" SG_ 1005 VC_BU_FULL_SPARE "0300FF00FFFFFFFFh";
BA_ "FlexKomSigStartPos" SG_ 1005 VC_BU_FULL_SPARE 7;
BA_ "FlexKomSigName" SG_ 1005 VC_BU_FULL_SPARE "VehCfgBu2_Pkt";
BA_ "FlexKomSigLaenge" SG_ 1005 VC_BU_FULL_SPARE 64;
BA_ "FlexKomSID" SG_ 1005 VC_BU_FULL_SPARE 920;
BA_ "FlexKomIsMotorola" SG_ 1005 VC_BU_FULL_SPARE 1;
BA_ "FlexKomComment" SG_ 1005 VC_BU_FULL_SPARE "Vehicle Configuration Backup 2 Packet";
BA_ "GenSigStartValue" SG_ 1005 VC_BU_LgtLdPressFtTr 255;
BA_ "GenSigSNA" SG_ 1005 VC_BU_LgtLdPressFtTr "FFh";
BA_ "GenSigSendType" SG_ 1005 VC_BU_LgtLdPressFtTr 1;
BA_ "FlexKomSigStartValue" SG_ 1005 VC_BU_LgtLdPressFtTr "0300FF00FFFFFFFFh";
BA_ "FlexKomSigStartPos" SG_ 1005 VC_BU_LgtLdPressFtTr 7;
BA_ "FlexKomSigName" SG_ 1005 VC_BU_LgtLdPressFtTr "VehCfgBu2_Pkt";
BA_ "FlexKomSigLaenge" SG_ 1005 VC_BU_LgtLdPressFtTr 64;
BA_ "FlexKomSID" SG_ 1005 VC_BU_LgtLdPressFtTr 920;
BA_ "FlexKomIsMotorola" SG_ 1005 VC_BU_LgtLdPressFtTr 1;
BA_ "FlexKomComment" SG_ 1005 VC_BU_LgtLdPressFtTr "Vehicle Configuration Backup 2 Packet";
BA_ "GenSigStartValue" SG_ 1005 VC_BU_LgtLdPressRrTr 255;
BA_ "GenSigSNA" SG_ 1005 VC_BU_LgtLdPressRrTr "FFh";
BA_ "GenSigSendType" SG_ 1005 VC_BU_LgtLdPressRrTr 1;
BA_ "FlexKomSigStartValue" SG_ 1005 VC_BU_LgtLdPressRrTr "0300FF00FFFFFFFFh";
BA_ "FlexKomSigStartPos" SG_ 1005 VC_BU_LgtLdPressRrTr 7;
BA_ "FlexKomSigName" SG_ 1005 VC_BU_LgtLdPressRrTr "VehCfgBu2_Pkt";
BA_ "FlexKomSigLaenge" SG_ 1005 VC_BU_LgtLdPressRrTr 64;
BA_ "FlexKomSID" SG_ 1005 VC_BU_LgtLdPressRrTr 920;
BA_ "FlexKomIsMotorola" SG_ 1005 VC_BU_LgtLdPressRrTr 1;
BA_ "FlexKomComment" SG_ 1005 VC_BU_LgtLdPressRrTr "Vehicle Configuration Backup 2 Packet";
BA_ "GenSigSNA" SG_ 1005 VC_BU_MaseratiMd "3h";
BA_ "GenSigSendType" SG_ 1005 VC_BU_MaseratiMd 1;
BA_ "FlexKomSigStartValue" SG_ 1005 VC_BU_MaseratiMd "0300FF00FFFFFFFFh";
BA_ "FlexKomSigStartPos" SG_ 1005 VC_BU_MaseratiMd 7;
BA_ "FlexKomSigName" SG_ 1005 VC_BU_MaseratiMd "VehCfgBu2_Pkt";
BA_ "FlexKomSigLaenge" SG_ 1005 VC_BU_MaseratiMd 64;
BA_ "FlexKomSID" SG_ 1005 VC_BU_MaseratiMd 920;
BA_ "FlexKomIsMotorola" SG_ 1005 VC_BU_MaseratiMd 1;
BA_ "FlexKomComment" SG_ 1005 VC_BU_MaseratiMd "Vehicle Configuration Backup 2 Packet";
BA_ "GenSigStartValue" SG_ 1005 VC_BU_MaxLdPressFtTr 255;
BA_ "GenSigSNA" SG_ 1005 VC_BU_MaxLdPressFtTr "FFh";
BA_ "GenSigSendType" SG_ 1005 VC_BU_MaxLdPressFtTr 1;
BA_ "FlexKomSigStartValue" SG_ 1005 VC_BU_MaxLdPressFtTr "0300FF00FFFFFFFFh";
BA_ "FlexKomSigStartPos" SG_ 1005 VC_BU_MaxLdPressFtTr 7;
BA_ "FlexKomSigName" SG_ 1005 VC_BU_MaxLdPressFtTr "VehCfgBu2_Pkt";
BA_ "FlexKomSigLaenge" SG_ 1005 VC_BU_MaxLdPressFtTr 64;
BA_ "FlexKomSID" SG_ 1005 VC_BU_MaxLdPressFtTr 920;
BA_ "FlexKomIsMotorola" SG_ 1005 VC_BU_MaxLdPressFtTr 1;
BA_ "FlexKomComment" SG_ 1005 VC_BU_MaxLdPressFtTr "Vehicle Configuration Backup 2 Packet";
BA_ "GenSigStartValue" SG_ 1005 VC_BU_MaxLdPressRrTr 255;
BA_ "GenSigSNA" SG_ 1005 VC_BU_MaxLdPressRrTr "FFh";
BA_ "GenSigSendType" SG_ 1005 VC_BU_MaxLdPressRrTr 1;
BA_ "FlexKomSigStartValue" SG_ 1005 VC_BU_MaxLdPressRrTr "0300FF00FFFFFFFFh";
BA_ "FlexKomSigStartPos" SG_ 1005 VC_BU_MaxLdPressRrTr 7;
BA_ "FlexKomSigName" SG_ 1005 VC_BU_MaxLdPressRrTr "VehCfgBu2_Pkt";
BA_ "FlexKomSigLaenge" SG_ 1005 VC_BU_MaxLdPressRrTr 64;
BA_ "FlexKomSID" SG_ 1005 VC_BU_MaxLdPressRrTr 920;
BA_ "FlexKomIsMotorola" SG_ 1005 VC_BU_MaxLdPressRrTr 1;
BA_ "FlexKomComment" SG_ 1005 VC_BU_MaxLdPressRrTr "Vehicle Configuration Backup 2 Packet";
BA_ "GenSigSNA" SG_ 1005 VC_BU_MemoryDRVMD_Prsnt "0h";
BA_ "GenSigSendType" SG_ 1005 VC_BU_MemoryDRVMD_Prsnt 1;
BA_ "FlexKomSigStartValue" SG_ 1005 VC_BU_MemoryDRVMD_Prsnt "0300FF00FFFFFFFFh";
BA_ "FlexKomSigStartPos" SG_ 1005 VC_BU_MemoryDRVMD_Prsnt 7;
BA_ "FlexKomSigName" SG_ 1005 VC_BU_MemoryDRVMD_Prsnt "VehCfgBu2_Pkt";
BA_ "FlexKomSigLaenge" SG_ 1005 VC_BU_MemoryDRVMD_Prsnt 64;
BA_ "FlexKomSID" SG_ 1005 VC_BU_MemoryDRVMD_Prsnt 920;
BA_ "FlexKomIsMotorola" SG_ 1005 VC_BU_MemoryDRVMD_Prsnt 1;
BA_ "FlexKomComment" SG_ 1005 VC_BU_MemoryDRVMD_Prsnt "Vehicle Configuration Backup 2 Packet";
BA_ "GenSigSNA" SG_ 1005 VC_BU_OffRoad "0h";
BA_ "GenSigSendType" SG_ 1005 VC_BU_OffRoad 1;
BA_ "FlexKomSigStartValue" SG_ 1005 VC_BU_OffRoad "0300FF00FFFFFFFFh";
BA_ "FlexKomSigStartPos" SG_ 1005 VC_BU_OffRoad 7;
BA_ "FlexKomSigName" SG_ 1005 VC_BU_OffRoad "VehCfgBu2_Pkt";
BA_ "FlexKomSigLaenge" SG_ 1005 VC_BU_OffRoad 64;
BA_ "FlexKomSID" SG_ 1005 VC_BU_OffRoad 920;
BA_ "FlexKomIsMotorola" SG_ 1005 VC_BU_OffRoad 1;
BA_ "FlexKomComment" SG_ 1005 VC_BU_OffRoad "Vehicle Configuration Backup 2 Packet";
BA_ "GenSigSNA" SG_ 1005 VC_BU_PADS_Prsnt "0h";
BA_ "GenSigSendType" SG_ 1005 VC_BU_PADS_Prsnt 1;
BA_ "FlexKomSigStartValue" SG_ 1005 VC_BU_PADS_Prsnt "0300FF00FFFFFFFFh";
BA_ "FlexKomSigStartPos" SG_ 1005 VC_BU_PADS_Prsnt 7;
BA_ "FlexKomSigName" SG_ 1005 VC_BU_PADS_Prsnt "VehCfgBu2_Pkt";
BA_ "FlexKomSigLaenge" SG_ 1005 VC_BU_PADS_Prsnt 64;
BA_ "FlexKomSID" SG_ 1005 VC_BU_PADS_Prsnt 920;
BA_ "FlexKomIsMotorola" SG_ 1005 VC_BU_PADS_Prsnt 1;
BA_ "FlexKomComment" SG_ 1005 VC_BU_PADS_Prsnt "Vehicle Configuration Backup 2 Packet";
BA_ "GenSigSNA" SG_ 1005 VC_BU_PwrIvtrTyp "0h";
BA_ "GenSigSendType" SG_ 1005 VC_BU_PwrIvtrTyp 1;
BA_ "FlexKomSigStartValue" SG_ 1005 VC_BU_PwrIvtrTyp "0300FF00FFFFFFFFh";
BA_ "FlexKomSigStartPos" SG_ 1005 VC_BU_PwrIvtrTyp 7;
BA_ "FlexKomSigName" SG_ 1005 VC_BU_PwrIvtrTyp "VehCfgBu2_Pkt";
BA_ "FlexKomSigLaenge" SG_ 1005 VC_BU_PwrIvtrTyp 64;
BA_ "FlexKomSID" SG_ 1005 VC_BU_PwrIvtrTyp 920;
BA_ "FlexKomIsMotorola" SG_ 1005 VC_BU_PwrIvtrTyp 1;
BA_ "FlexKomComment" SG_ 1005 VC_BU_PwrIvtrTyp "Vehicle Configuration Backup 2 Packet";
BA_ "GenSigSNA" SG_ 1005 VC_BU_RainSnsPrsnt "0h";
BA_ "GenSigSendType" SG_ 1005 VC_BU_RainSnsPrsnt 1;
BA_ "FlexKomSigStartValue" SG_ 1005 VC_BU_RainSnsPrsnt "0300FF00FFFFFFFFh";
BA_ "FlexKomSigStartPos" SG_ 1005 VC_BU_RainSnsPrsnt 7;
BA_ "FlexKomSigName" SG_ 1005 VC_BU_RainSnsPrsnt "VehCfgBu2_Pkt";
BA_ "FlexKomSigLaenge" SG_ 1005 VC_BU_RainSnsPrsnt 64;
BA_ "FlexKomSID" SG_ 1005 VC_BU_RainSnsPrsnt 920;
BA_ "FlexKomIsMotorola" SG_ 1005 VC_BU_RainSnsPrsnt 1;
BA_ "FlexKomComment" SG_ 1005 VC_BU_RainSnsPrsnt "Vehicle Configuration Backup 2 Packet";
BA_ "GenSigSNA" SG_ 1005 VC_BU_RunFlatTirePrsnt "0h";
BA_ "GenSigSendType" SG_ 1005 VC_BU_RunFlatTirePrsnt 1;
BA_ "FlexKomSigStartValue" SG_ 1005 VC_BU_RunFlatTirePrsnt "0300FF00FFFFFFFFh";
BA_ "FlexKomSigStartPos" SG_ 1005 VC_BU_RunFlatTirePrsnt 7;
BA_ "FlexKomSigName" SG_ 1005 VC_BU_RunFlatTirePrsnt "VehCfgBu2_Pkt";
BA_ "FlexKomSigLaenge" SG_ 1005 VC_BU_RunFlatTirePrsnt 64;
BA_ "FlexKomSID" SG_ 1005 VC_BU_RunFlatTirePrsnt 920;
BA_ "FlexKomIsMotorola" SG_ 1005 VC_BU_RunFlatTirePrsnt 1;
BA_ "FlexKomComment" SG_ 1005 VC_BU_RunFlatTirePrsnt "Vehicle Configuration Backup 2 Packet";
BA_ "GenSigSNA" SG_ 1005 VC_BU_SKIM_PRSNT "0h";
BA_ "GenSigSendType" SG_ 1005 VC_BU_SKIM_PRSNT 1;
BA_ "FlexKomSigStartValue" SG_ 1005 VC_BU_SKIM_PRSNT "0300FF00FFFFFFFFh";
BA_ "FlexKomSigStartPos" SG_ 1005 VC_BU_SKIM_PRSNT 7;
BA_ "FlexKomSigName" SG_ 1005 VC_BU_SKIM_PRSNT "VehCfgBu2_Pkt";
BA_ "FlexKomSigLaenge" SG_ 1005 VC_BU_SKIM_PRSNT 64;
BA_ "FlexKomSID" SG_ 1005 VC_BU_SKIM_PRSNT 920;
BA_ "FlexKomIsMotorola" SG_ 1005 VC_BU_SKIM_PRSNT 1;
BA_ "FlexKomComment" SG_ 1005 VC_BU_SKIM_PRSNT "Vehicle Configuration Backup 2 Packet";
BA_ "GenSigSNA" SG_ 1005 VC_BU_SecPrkPrsnt "0h";
BA_ "GenSigSendType" SG_ 1005 VC_BU_SecPrkPrsnt 1;
BA_ "FlexKomSigStartValue" SG_ 1005 VC_BU_SecPrkPrsnt "0300FF00FFFFFFFFh";
BA_ "FlexKomSigStartPos" SG_ 1005 VC_BU_SecPrkPrsnt 7;
BA_ "FlexKomSigName" SG_ 1005 VC_BU_SecPrkPrsnt "VehCfgBu2_Pkt";
BA_ "FlexKomSigLaenge" SG_ 1005 VC_BU_SecPrkPrsnt 64;
BA_ "FlexKomSID" SG_ 1005 VC_BU_SecPrkPrsnt 920;
BA_ "FlexKomIsMotorola" SG_ 1005 VC_BU_SecPrkPrsnt 1;
BA_ "FlexKomComment" SG_ 1005 VC_BU_SecPrkPrsnt "Vehicle Configuration Backup 2 Packet";
BA_ "GenSigSNA" SG_ 1005 VC_BU_ShftInd_Prsnt "0h";
BA_ "GenSigSendType" SG_ 1005 VC_BU_ShftInd_Prsnt 1;
BA_ "FlexKomSigStartValue" SG_ 1005 VC_BU_ShftInd_Prsnt "0300FF00FFFFFFFFh";
BA_ "FlexKomSigStartPos" SG_ 1005 VC_BU_ShftInd_Prsnt 7;
BA_ "FlexKomSigName" SG_ 1005 VC_BU_ShftInd_Prsnt "VehCfgBu2_Pkt";
BA_ "FlexKomSigLaenge" SG_ 1005 VC_BU_ShftInd_Prsnt 64;
BA_ "FlexKomSID" SG_ 1005 VC_BU_ShftInd_Prsnt 920;
BA_ "FlexKomIsMotorola" SG_ 1005 VC_BU_ShftInd_Prsnt 1;
BA_ "FlexKomComment" SG_ 1005 VC_BU_ShftInd_Prsnt "Vehicle Configuration Backup 2 Packet";
BA_ "GenSigStartValue" SG_ 1005 VC_BU_SpecialPKG_IC 255;
BA_ "GenSigSNA" SG_ 1005 VC_BU_SpecialPKG_IC "FFh";
BA_ "GenSigSendType" SG_ 1005 VC_BU_SpecialPKG_IC 1;
BA_ "FlexKomSigStartValue" SG_ 1005 VC_BU_SpecialPKG_IC "0300FF00FFFFFFFFh";
BA_ "FlexKomSigStartPos" SG_ 1005 VC_BU_SpecialPKG_IC 7;
BA_ "FlexKomSigName" SG_ 1005 VC_BU_SpecialPKG_IC "VehCfgBu2_Pkt";
BA_ "FlexKomSigLaenge" SG_ 1005 VC_BU_SpecialPKG_IC 64;
BA_ "FlexKomSID" SG_ 1005 VC_BU_SpecialPKG_IC 920;
BA_ "FlexKomIsMotorola" SG_ 1005 VC_BU_SpecialPKG_IC 1;
BA_ "FlexKomComment" SG_ 1005 VC_BU_SpecialPKG_IC "Vehicle Configuration Backup 2 Packet";
BA_ "GenSigSNA" SG_ 1005 VC_BU_ThatchamPrsnt "0h";
BA_ "GenSigSendType" SG_ 1005 VC_BU_ThatchamPrsnt 1;
BA_ "FlexKomSigStartValue" SG_ 1005 VC_BU_ThatchamPrsnt "0300FF00FFFFFFFFh";
BA_ "FlexKomSigStartPos" SG_ 1005 VC_BU_ThatchamPrsnt 7;
BA_ "FlexKomSigName" SG_ 1005 VC_BU_ThatchamPrsnt "VehCfgBu2_Pkt";
BA_ "FlexKomSigLaenge" SG_ 1005 VC_BU_ThatchamPrsnt 64;
BA_ "FlexKomSID" SG_ 1005 VC_BU_ThatchamPrsnt 920;
BA_ "FlexKomIsMotorola" SG_ 1005 VC_BU_ThatchamPrsnt 1;
BA_ "FlexKomComment" SG_ 1005 VC_BU_ThatchamPrsnt "Vehicle Configuration Backup 2 Packet";
BA_ "GenSigStartValue" SG_ 1005 VC_BU_VehCfg2_Stat 3;
BA_ "GenSigSNA" SG_ 1005 VC_BU_VehCfg2_Stat "3h";
BA_ "GenSigSendType" SG_ 1005 VC_BU_VehCfg2_Stat 1;
BA_ "FlexKomSigStartValue" SG_ 1005 VC_BU_VehCfg2_Stat "0300FF00FFFFFFFFh";
BA_ "FlexKomSigStartPos" SG_ 1005 VC_BU_VehCfg2_Stat 7;
BA_ "FlexKomSigName" SG_ 1005 VC_BU_VehCfg2_Stat "VehCfgBu2_Pkt";
BA_ "FlexKomSigLaenge" SG_ 1005 VC_BU_VehCfg2_Stat 64;
BA_ "FlexKomSID" SG_ 1005 VC_BU_VehCfg2_Stat 920;
BA_ "FlexKomIsMotorola" SG_ 1005 VC_BU_VehCfg2_Stat 1;
BA_ "FlexKomComment" SG_ 1005 VC_BU_VehCfg2_Stat "Vehicle Configuration Backup 2 Packet";
BA_ "GenSigSNA" SG_ 1006 VC_BU_ADJ_PDL_PRSNT "0h";
BA_ "GenSigSendType" SG_ 1006 VC_BU_ADJ_PDL_PRSNT 1;
BA_ "FlexKomSigStartValue" SG_ 1006 VC_BU_ADJ_PDL_PRSNT "0370FF037FFF0000h";
BA_ "FlexKomSigStartPos" SG_ 1006 VC_BU_ADJ_PDL_PRSNT 7;
BA_ "FlexKomSigName" SG_ 1006 VC_BU_ADJ_PDL_PRSNT "VehCfgBu3_Pkt";
BA_ "FlexKomSigLaenge" SG_ 1006 VC_BU_ADJ_PDL_PRSNT 64;
BA_ "FlexKomSID" SG_ 1006 VC_BU_ADJ_PDL_PRSNT 921;
BA_ "FlexKomIsMotorola" SG_ 1006 VC_BU_ADJ_PDL_PRSNT 1;
BA_ "FlexKomComment" SG_ 1006 VC_BU_ADJ_PDL_PRSNT "Vehicle Configuration Backup 3 Packet";
BA_ "GenSigSNA" SG_ 1006 VC_BU_AUTO_HL "0h";
BA_ "GenSigSendType" SG_ 1006 VC_BU_AUTO_HL 1;
BA_ "FlexKomSigStartValue" SG_ 1006 VC_BU_AUTO_HL "0370FF037FFF0000h";
BA_ "FlexKomSigStartPos" SG_ 1006 VC_BU_AUTO_HL 7;
BA_ "FlexKomSigName" SG_ 1006 VC_BU_AUTO_HL "VehCfgBu3_Pkt";
BA_ "FlexKomSigLaenge" SG_ 1006 VC_BU_AUTO_HL 64;
BA_ "FlexKomSID" SG_ 1006 VC_BU_AUTO_HL 921;
BA_ "FlexKomIsMotorola" SG_ 1006 VC_BU_AUTO_HL 1;
BA_ "FlexKomComment" SG_ 1006 VC_BU_AUTO_HL "Vehicle Configuration Backup 3 Packet";
BA_ "GenSigSNA" SG_ 1006 VC_BU_AutoParkPrsnt "0h";
BA_ "GenSigSendType" SG_ 1006 VC_BU_AutoParkPrsnt 1;
BA_ "FlexKomSigStartValue" SG_ 1006 VC_BU_AutoParkPrsnt "0370FF037FFF0000h";
BA_ "FlexKomSigStartPos" SG_ 1006 VC_BU_AutoParkPrsnt 7;
BA_ "FlexKomSigName" SG_ 1006 VC_BU_AutoParkPrsnt "VehCfgBu3_Pkt";
BA_ "FlexKomSigLaenge" SG_ 1006 VC_BU_AutoParkPrsnt 64;
BA_ "FlexKomSID" SG_ 1006 VC_BU_AutoParkPrsnt 921;
BA_ "FlexKomIsMotorola" SG_ 1006 VC_BU_AutoParkPrsnt 1;
BA_ "FlexKomComment" SG_ 1006 VC_BU_AutoParkPrsnt "Vehicle Configuration Backup 3 Packet";
BA_ "GenSigSNA" SG_ 1006 VC_BU_Base_TPM "0h";
BA_ "GenSigSendType" SG_ 1006 VC_BU_Base_TPM 1;
BA_ "FlexKomSigStartValue" SG_ 1006 VC_BU_Base_TPM "0370FF037FFF0000h";
BA_ "FlexKomSigStartPos" SG_ 1006 VC_BU_Base_TPM 7;
BA_ "FlexKomSigName" SG_ 1006 VC_BU_Base_TPM "VehCfgBu3_Pkt";
BA_ "FlexKomSigLaenge" SG_ 1006 VC_BU_Base_TPM 64;
BA_ "FlexKomSID" SG_ 1006 VC_BU_Base_TPM 921;
BA_ "FlexKomIsMotorola" SG_ 1006 VC_BU_Base_TPM 1;
BA_ "FlexKomComment" SG_ 1006 VC_BU_Base_TPM "Vehicle Configuration Backup 3 Packet";
BA_ "GenSigSNA" SG_ 1006 VC_BU_CMP_DISP "0h";
BA_ "GenSigSendType" SG_ 1006 VC_BU_CMP_DISP 1;
BA_ "FlexKomSigStartValue" SG_ 1006 VC_BU_CMP_DISP "0370FF037FFF0000h";
BA_ "FlexKomSigStartPos" SG_ 1006 VC_BU_CMP_DISP 7;
BA_ "FlexKomSigName" SG_ 1006 VC_BU_CMP_DISP "VehCfgBu3_Pkt";
BA_ "FlexKomSigLaenge" SG_ 1006 VC_BU_CMP_DISP 64;
BA_ "FlexKomSID" SG_ 1006 VC_BU_CMP_DISP 921;
BA_ "FlexKomIsMotorola" SG_ 1006 VC_BU_CMP_DISP 1;
BA_ "FlexKomComment" SG_ 1006 VC_BU_CMP_DISP "Vehicle Configuration Backup 3 Packet";
BA_ "GenSigSNA" SG_ 1006 VC_BU_CMS "0h";
BA_ "GenSigSendType" SG_ 1006 VC_BU_CMS 1;
BA_ "FlexKomSigStartValue" SG_ 1006 VC_BU_CMS "0370FF037FFF0000h";
BA_ "FlexKomSigStartPos" SG_ 1006 VC_BU_CMS 7;
BA_ "FlexKomSigName" SG_ 1006 VC_BU_CMS "VehCfgBu3_Pkt";
BA_ "FlexKomSigLaenge" SG_ 1006 VC_BU_CMS 64;
BA_ "FlexKomSID" SG_ 1006 VC_BU_CMS 921;
BA_ "FlexKomIsMotorola" SG_ 1006 VC_BU_CMS 1;
BA_ "FlexKomComment" SG_ 1006 VC_BU_CMS "Vehicle Configuration Backup 3 Packet";
BA_ "GenSigStartValue" SG_ 1006 VC_BU_ChassisType 127;
BA_ "GenSigSNA" SG_ 1006 VC_BU_ChassisType "7Fh";
BA_ "GenSigSendType" SG_ 1006 VC_BU_ChassisType 1;
BA_ "FlexKomSigStartValue" SG_ 1006 VC_BU_ChassisType "0370FF037FFF0000h";
BA_ "FlexKomSigStartPos" SG_ 1006 VC_BU_ChassisType 7;
BA_ "FlexKomSigName" SG_ 1006 VC_BU_ChassisType "VehCfgBu3_Pkt";
BA_ "FlexKomSigLaenge" SG_ 1006 VC_BU_ChassisType 64;
BA_ "FlexKomSID" SG_ 1006 VC_BU_ChassisType 921;
BA_ "FlexKomIsMotorola" SG_ 1006 VC_BU_ChassisType 1;
BA_ "FlexKomComment" SG_ 1006 VC_BU_ChassisType "Vehicle Configuration Backup 3 Packet";
BA_ "GenSigSNA" SG_ 1006 VC_BU_DSBL_CLK_DISP "0h";
BA_ "GenSigSendType" SG_ 1006 VC_BU_DSBL_CLK_DISP 1;
BA_ "FlexKomSigStartValue" SG_ 1006 VC_BU_DSBL_CLK_DISP "0370FF037FFF0000h";
BA_ "FlexKomSigStartPos" SG_ 1006 VC_BU_DSBL_CLK_DISP 7;
BA_ "FlexKomSigName" SG_ 1006 VC_BU_DSBL_CLK_DISP "VehCfgBu3_Pkt";
BA_ "FlexKomSigLaenge" SG_ 1006 VC_BU_DSBL_CLK_DISP 64;
BA_ "FlexKomSID" SG_ 1006 VC_BU_DSBL_CLK_DISP 921;
BA_ "FlexKomIsMotorola" SG_ 1006 VC_BU_DSBL_CLK_DISP 1;
BA_ "FlexKomComment" SG_ 1006 VC_BU_DSBL_CLK_DISP "Vehicle Configuration Backup 3 Packet";
BA_ "GenSigSNA" SG_ 1006 VC_BU_DrAlrPrsnt "0h";
BA_ "GenSigSendType" SG_ 1006 VC_BU_DrAlrPrsnt 1;
BA_ "FlexKomSigStartValue" SG_ 1006 VC_BU_DrAlrPrsnt "0370FF037FFF0000h";
BA_ "FlexKomSigStartPos" SG_ 1006 VC_BU_DrAlrPrsnt 7;
BA_ "FlexKomSigName" SG_ 1006 VC_BU_DrAlrPrsnt "VehCfgBu3_Pkt";
BA_ "FlexKomSigLaenge" SG_ 1006 VC_BU_DrAlrPrsnt 64;
BA_ "FlexKomSID" SG_ 1006 VC_BU_DrAlrPrsnt 921;
BA_ "FlexKomIsMotorola" SG_ 1006 VC_BU_DrAlrPrsnt 1;
BA_ "FlexKomComment" SG_ 1006 VC_BU_DrAlrPrsnt "Vehicle Configuration Backup 3 Packet";
BA_ "GenSigSNA" SG_ 1006 VC_BU_DualFuelSens "0h";
BA_ "GenSigSendType" SG_ 1006 VC_BU_DualFuelSens 1;
BA_ "FlexKomSigStartValue" SG_ 1006 VC_BU_DualFuelSens "0370FF037FFF0000h";
BA_ "FlexKomSigStartPos" SG_ 1006 VC_BU_DualFuelSens 7;
BA_ "FlexKomSigName" SG_ 1006 VC_BU_DualFuelSens "VehCfgBu3_Pkt";
BA_ "FlexKomSigLaenge" SG_ 1006 VC_BU_DualFuelSens 64;
BA_ "FlexKomSID" SG_ 1006 VC_BU_DualFuelSens 921;
BA_ "FlexKomIsMotorola" SG_ 1006 VC_BU_DualFuelSens 1;
BA_ "FlexKomComment" SG_ 1006 VC_BU_DualFuelSens "Vehicle Configuration Backup 3 Packet";
BA_ "GenSigSNA" SG_ 1006 VC_BU_ELV_PRSNT "0h";
BA_ "GenSigSendType" SG_ 1006 VC_BU_ELV_PRSNT 1;
BA_ "FlexKomSigStartValue" SG_ 1006 VC_BU_ELV_PRSNT "0370FF037FFF0000h";
BA_ "FlexKomSigStartPos" SG_ 1006 VC_BU_ELV_PRSNT 7;
BA_ "FlexKomSigName" SG_ 1006 VC_BU_ELV_PRSNT "VehCfgBu3_Pkt";
BA_ "FlexKomSigLaenge" SG_ 1006 VC_BU_ELV_PRSNT 64;
BA_ "FlexKomSID" SG_ 1006 VC_BU_ELV_PRSNT 921;
BA_ "FlexKomIsMotorola" SG_ 1006 VC_BU_ELV_PRSNT 1;
BA_ "FlexKomComment" SG_ 1006 VC_BU_ELV_PRSNT "Vehicle Configuration Backup 3 Packet";
BA_ "GenSigSNA" SG_ 1006 VC_BU_ESCL_Prsnt "0h";
BA_ "GenSigSendType" SG_ 1006 VC_BU_ESCL_Prsnt 1;
BA_ "FlexKomSigStartValue" SG_ 1006 VC_BU_ESCL_Prsnt "0370FF037FFF0000h";
BA_ "FlexKomSigStartPos" SG_ 1006 VC_BU_ESCL_Prsnt 7;
BA_ "FlexKomSigName" SG_ 1006 VC_BU_ESCL_Prsnt "VehCfgBu3_Pkt";
BA_ "FlexKomSigLaenge" SG_ 1006 VC_BU_ESCL_Prsnt 64;
BA_ "FlexKomSID" SG_ 1006 VC_BU_ESCL_Prsnt 921;
BA_ "FlexKomIsMotorola" SG_ 1006 VC_BU_ESCL_Prsnt 1;
BA_ "FlexKomComment" SG_ 1006 VC_BU_ESCL_Prsnt "Vehicle Configuration Backup 3 Packet";
BA_ "GenSigSNA" SG_ 1006 VC_BU_FCW "0h";
BA_ "GenSigSendType" SG_ 1006 VC_BU_FCW 1;
BA_ "FlexKomSigStartValue" SG_ 1006 VC_BU_FCW "0370FF037FFF0000h";
BA_ "FlexKomSigStartPos" SG_ 1006 VC_BU_FCW 7;
BA_ "FlexKomSigName" SG_ 1006 VC_BU_FCW "VehCfgBu3_Pkt";
BA_ "FlexKomSigLaenge" SG_ 1006 VC_BU_FCW 64;
BA_ "FlexKomSID" SG_ 1006 VC_BU_FCW 921;
BA_ "FlexKomIsMotorola" SG_ 1006 VC_BU_FCW 1;
BA_ "FlexKomComment" SG_ 1006 VC_BU_FCW "Vehicle Configuration Backup 3 Packet";
BA_ "GenSigStartValue" SG_ 1006 VC_BU_FOBIKsafeENBL 1;
BA_ "GenSigSNA" SG_ 1006 VC_BU_FOBIKsafeENBL "1h";
BA_ "GenSigSendType" SG_ 1006 VC_BU_FOBIKsafeENBL 1;
BA_ "FlexKomSigStartValue" SG_ 1006 VC_BU_FOBIKsafeENBL "0370FF037FFF0000h";
BA_ "FlexKomSigStartPos" SG_ 1006 VC_BU_FOBIKsafeENBL 7;
BA_ "FlexKomSigName" SG_ 1006 VC_BU_FOBIKsafeENBL "VehCfgBu3_Pkt";
BA_ "FlexKomSigLaenge" SG_ 1006 VC_BU_FOBIKsafeENBL 64;
BA_ "FlexKomSID" SG_ 1006 VC_BU_FOBIKsafeENBL 921;
BA_ "FlexKomIsMotorola" SG_ 1006 VC_BU_FOBIKsafeENBL 1;
BA_ "FlexKomComment" SG_ 1006 VC_BU_FOBIKsafeENBL "Vehicle Configuration Backup 3 Packet";
BA_ "GenSigStartValue" SG_ 1006 VC_BU_FUEL_CAP 255;
BA_ "GenSigSNA" SG_ 1006 VC_BU_FUEL_CAP "FFh";
BA_ "GenSigSendType" SG_ 1006 VC_BU_FUEL_CAP 1;
BA_ "FlexKomSigStartValue" SG_ 1006 VC_BU_FUEL_CAP "0370FF037FFF0000h";
BA_ "FlexKomSigStartPos" SG_ 1006 VC_BU_FUEL_CAP 7;
BA_ "FlexKomSigName" SG_ 1006 VC_BU_FUEL_CAP "VehCfgBu3_Pkt";
BA_ "FlexKomSigLaenge" SG_ 1006 VC_BU_FUEL_CAP 64;
BA_ "FlexKomSID" SG_ 1006 VC_BU_FUEL_CAP 921;
BA_ "FlexKomIsMotorola" SG_ 1006 VC_BU_FUEL_CAP 1;
BA_ "FlexKomComment" SG_ 1006 VC_BU_FUEL_CAP "Vehicle Configuration Backup 3 Packet";
BA_ "GenSigSNA" SG_ 1006 VC_BU_HID_HL "0h";
BA_ "GenSigSendType" SG_ 1006 VC_BU_HID_HL 1;
BA_ "FlexKomSigStartValue" SG_ 1006 VC_BU_HID_HL "0370FF037FFF0000h";
BA_ "FlexKomSigStartPos" SG_ 1006 VC_BU_HID_HL 7;
BA_ "FlexKomSigName" SG_ 1006 VC_BU_HID_HL "VehCfgBu3_Pkt";
BA_ "FlexKomSigLaenge" SG_ 1006 VC_BU_HID_HL 64;
BA_ "FlexKomSID" SG_ 1006 VC_BU_HID_HL 921;
BA_ "FlexKomIsMotorola" SG_ 1006 VC_BU_HID_HL 1;
BA_ "FlexKomComment" SG_ 1006 VC_BU_HID_HL "Vehicle Configuration Backup 3 Packet";
BA_ "GenSigStartValue" SG_ 1006 VC_BU_HVAC_Config 15;
BA_ "GenSigSNA" SG_ 1006 VC_BU_HVAC_Config "Fh";
BA_ "GenSigSendType" SG_ 1006 VC_BU_HVAC_Config 1;
BA_ "FlexKomSigStartValue" SG_ 1006 VC_BU_HVAC_Config "0370FF037FFF0000h";
BA_ "FlexKomSigStartPos" SG_ 1006 VC_BU_HVAC_Config 7;
BA_ "FlexKomSigName" SG_ 1006 VC_BU_HVAC_Config "VehCfgBu3_Pkt";
BA_ "FlexKomSigLaenge" SG_ 1006 VC_BU_HVAC_Config 64;
BA_ "FlexKomSID" SG_ 1006 VC_BU_HVAC_Config 921;
BA_ "FlexKomIsMotorola" SG_ 1006 VC_BU_HVAC_Config 1;
BA_ "FlexKomComment" SG_ 1006 VC_BU_HVAC_Config "Vehicle Configuration Backup 3 Packet";
BA_ "GenSigSNA" SG_ 1006 VC_BU_IntEC_MIRR "0h";
BA_ "GenSigSendType" SG_ 1006 VC_BU_IntEC_MIRR 1;
BA_ "FlexKomSigStartValue" SG_ 1006 VC_BU_IntEC_MIRR "0370FF037FFF0000h";
BA_ "FlexKomSigStartPos" SG_ 1006 VC_BU_IntEC_MIRR 7;
BA_ "FlexKomSigName" SG_ 1006 VC_BU_IntEC_MIRR "VehCfgBu3_Pkt";
BA_ "FlexKomSigLaenge" SG_ 1006 VC_BU_IntEC_MIRR 64;
BA_ "FlexKomSID" SG_ 1006 VC_BU_IntEC_MIRR 921;
BA_ "FlexKomIsMotorola" SG_ 1006 VC_BU_IntEC_MIRR 1;
BA_ "FlexKomComment" SG_ 1006 VC_BU_IntEC_MIRR "Vehicle Configuration Backup 3 Packet";
BA_ "GenSigSNA" SG_ 1006 VC_BU_KG_Prsnt "0h";
BA_ "GenSigSendType" SG_ 1006 VC_BU_KG_Prsnt 1;
BA_ "FlexKomSigStartValue" SG_ 1006 VC_BU_KG_Prsnt "0370FF037FFF0000h";
BA_ "FlexKomSigStartPos" SG_ 1006 VC_BU_KG_Prsnt 7;
BA_ "FlexKomSigName" SG_ 1006 VC_BU_KG_Prsnt "VehCfgBu3_Pkt";
BA_ "FlexKomSigLaenge" SG_ 1006 VC_BU_KG_Prsnt 64;
BA_ "FlexKomSID" SG_ 1006 VC_BU_KG_Prsnt 921;
BA_ "FlexKomIsMotorola" SG_ 1006 VC_BU_KG_Prsnt 1;
BA_ "FlexKomComment" SG_ 1006 VC_BU_KG_Prsnt "Vehicle Configuration Backup 3 Packet";
BA_ "GenSigSNA" SG_ 1006 VC_BU_Liftgate_Trunk "3h";
BA_ "GenSigSendType" SG_ 1006 VC_BU_Liftgate_Trunk 1;
BA_ "FlexKomSigStartValue" SG_ 1006 VC_BU_Liftgate_Trunk "0370FF037FFF0000h";
BA_ "FlexKomSigStartPos" SG_ 1006 VC_BU_Liftgate_Trunk 7;
BA_ "FlexKomSigName" SG_ 1006 VC_BU_Liftgate_Trunk "VehCfgBu3_Pkt";
BA_ "FlexKomSigLaenge" SG_ 1006 VC_BU_Liftgate_Trunk 64;
BA_ "FlexKomSID" SG_ 1006 VC_BU_Liftgate_Trunk 921;
BA_ "FlexKomIsMotorola" SG_ 1006 VC_BU_Liftgate_Trunk 1;
BA_ "FlexKomComment" SG_ 1006 VC_BU_Liftgate_Trunk "Vehicle Configuration Backup 3 Packet";
BA_ "GenSigSNA" SG_ 1006 VC_BU_PDDL_PRSNT "0h";
BA_ "GenSigSendType" SG_ 1006 VC_BU_PDDL_PRSNT 1;
BA_ "FlexKomSigStartValue" SG_ 1006 VC_BU_PDDL_PRSNT "0370FF037FFF0000h";
BA_ "FlexKomSigStartPos" SG_ 1006 VC_BU_PDDL_PRSNT 7;
BA_ "FlexKomSigName" SG_ 1006 VC_BU_PDDL_PRSNT "VehCfgBu3_Pkt";
BA_ "FlexKomSigLaenge" SG_ 1006 VC_BU_PDDL_PRSNT 64;
BA_ "FlexKomSID" SG_ 1006 VC_BU_PDDL_PRSNT 921;
BA_ "FlexKomIsMotorola" SG_ 1006 VC_BU_PDDL_PRSNT 1;
BA_ "FlexKomComment" SG_ 1006 VC_BU_PDDL_PRSNT "Vehicle Configuration Backup 3 Packet";
BA_ "GenSigSNA" SG_ 1006 VC_BU_PE_Prsnt "0h";
BA_ "GenSigSendType" SG_ 1006 VC_BU_PE_Prsnt 1;
BA_ "FlexKomSigStartValue" SG_ 1006 VC_BU_PE_Prsnt "0370FF037FFF0000h";
BA_ "FlexKomSigStartPos" SG_ 1006 VC_BU_PE_Prsnt 7;
BA_ "FlexKomSigName" SG_ 1006 VC_BU_PE_Prsnt "VehCfgBu3_Pkt";
BA_ "FlexKomSigLaenge" SG_ 1006 VC_BU_PE_Prsnt 64;
BA_ "FlexKomSID" SG_ 1006 VC_BU_PE_Prsnt 921;
BA_ "FlexKomIsMotorola" SG_ 1006 VC_BU_PE_Prsnt 1;
BA_ "FlexKomComment" SG_ 1006 VC_BU_PE_Prsnt "Vehicle Configuration Backup 3 Packet";
BA_ "GenSigSNA" SG_ 1006 VC_BU_POLICE "0h";
BA_ "GenSigSendType" SG_ 1006 VC_BU_POLICE 1;
BA_ "FlexKomSigStartValue" SG_ 1006 VC_BU_POLICE "0370FF037FFF0000h";
BA_ "FlexKomSigStartPos" SG_ 1006 VC_BU_POLICE 7;
BA_ "FlexKomSigName" SG_ 1006 VC_BU_POLICE "VehCfgBu3_Pkt";
BA_ "FlexKomSigLaenge" SG_ 1006 VC_BU_POLICE 64;
BA_ "FlexKomSID" SG_ 1006 VC_BU_POLICE 921;
BA_ "FlexKomIsMotorola" SG_ 1006 VC_BU_POLICE 1;
BA_ "FlexKomComment" SG_ 1006 VC_BU_POLICE "Vehicle Configuration Backup 3 Packet";
BA_ "GenSigSNA" SG_ 1006 VC_BU_PWR_LFT_GT "0h";
BA_ "GenSigSendType" SG_ 1006 VC_BU_PWR_LFT_GT 1;
BA_ "FlexKomSigStartValue" SG_ 1006 VC_BU_PWR_LFT_GT "0370FF037FFF0000h";
BA_ "FlexKomSigStartPos" SG_ 1006 VC_BU_PWR_LFT_GT 7;
BA_ "FlexKomSigName" SG_ 1006 VC_BU_PWR_LFT_GT "VehCfgBu3_Pkt";
BA_ "FlexKomSigLaenge" SG_ 1006 VC_BU_PWR_LFT_GT 64;
BA_ "FlexKomSID" SG_ 1006 VC_BU_PWR_LFT_GT 921;
BA_ "FlexKomIsMotorola" SG_ 1006 VC_BU_PWR_LFT_GT 1;
BA_ "FlexKomComment" SG_ 1006 VC_BU_PWR_LFT_GT "Vehicle Configuration Backup 3 Packet";
BA_ "GenSigSNA" SG_ 1006 VC_BU_PWR_LT_SLDR "0h";
BA_ "GenSigSendType" SG_ 1006 VC_BU_PWR_LT_SLDR 1;
BA_ "FlexKomSigStartValue" SG_ 1006 VC_BU_PWR_LT_SLDR "0370FF037FFF0000h";
BA_ "FlexKomSigStartPos" SG_ 1006 VC_BU_PWR_LT_SLDR 7;
BA_ "FlexKomSigName" SG_ 1006 VC_BU_PWR_LT_SLDR "VehCfgBu3_Pkt";
BA_ "FlexKomSigLaenge" SG_ 1006 VC_BU_PWR_LT_SLDR 64;
BA_ "FlexKomSID" SG_ 1006 VC_BU_PWR_LT_SLDR 921;
BA_ "FlexKomIsMotorola" SG_ 1006 VC_BU_PWR_LT_SLDR 1;
BA_ "FlexKomComment" SG_ 1006 VC_BU_PWR_LT_SLDR "Vehicle Configuration Backup 3 Packet";
BA_ "GenSigSNA" SG_ 1006 VC_BU_PWR_RT_SLDR "0h";
BA_ "GenSigSendType" SG_ 1006 VC_BU_PWR_RT_SLDR 1;
BA_ "FlexKomSigStartValue" SG_ 1006 VC_BU_PWR_RT_SLDR "0370FF037FFF0000h";
BA_ "FlexKomSigStartPos" SG_ 1006 VC_BU_PWR_RT_SLDR 7;
BA_ "FlexKomSigName" SG_ 1006 VC_BU_PWR_RT_SLDR "VehCfgBu3_Pkt";
BA_ "FlexKomSigLaenge" SG_ 1006 VC_BU_PWR_RT_SLDR 64;
BA_ "FlexKomSID" SG_ 1006 VC_BU_PWR_RT_SLDR 921;
BA_ "FlexKomIsMotorola" SG_ 1006 VC_BU_PWR_RT_SLDR 1;
BA_ "FlexKomComment" SG_ 1006 VC_BU_PWR_RT_SLDR "Vehicle Configuration Backup 3 Packet";
BA_ "GenSigSNA" SG_ 1006 VC_BU_Prem_TPM "0h";
BA_ "GenSigSendType" SG_ 1006 VC_BU_Prem_TPM 1;
BA_ "FlexKomSigStartValue" SG_ 1006 VC_BU_Prem_TPM "0370FF037FFF0000h";
BA_ "FlexKomSigStartPos" SG_ 1006 VC_BU_Prem_TPM 7;
BA_ "FlexKomSigName" SG_ 1006 VC_BU_Prem_TPM "VehCfgBu3_Pkt";
BA_ "FlexKomSigLaenge" SG_ 1006 VC_BU_Prem_TPM 64;
BA_ "FlexKomSID" SG_ 1006 VC_BU_Prem_TPM 921;
BA_ "FlexKomIsMotorola" SG_ 1006 VC_BU_Prem_TPM 1;
BA_ "FlexKomComment" SG_ 1006 VC_BU_Prem_TPM "Vehicle Configuration Backup 3 Packet";
BA_ "GenSigSNA" SG_ 1006 VC_BU_RKE_PRSNT "0h";
BA_ "GenSigSendType" SG_ 1006 VC_BU_RKE_PRSNT 1;
BA_ "FlexKomSigStartValue" SG_ 1006 VC_BU_RKE_PRSNT "0370FF037FFF0000h";
BA_ "FlexKomSigStartPos" SG_ 1006 VC_BU_RKE_PRSNT 7;
BA_ "FlexKomSigName" SG_ 1006 VC_BU_RKE_PRSNT "VehCfgBu3_Pkt";
BA_ "FlexKomSigLaenge" SG_ 1006 VC_BU_RKE_PRSNT 64;
BA_ "FlexKomSID" SG_ 1006 VC_BU_RKE_PRSNT 921;
BA_ "FlexKomIsMotorola" SG_ 1006 VC_BU_RKE_PRSNT 1;
BA_ "FlexKomComment" SG_ 1006 VC_BU_RKE_PRSNT "Vehicle Configuration Backup 3 Packet";
BA_ "GenSigSNA" SG_ 1006 VC_BU_SPORT_PRSNT "0h";
BA_ "GenSigSendType" SG_ 1006 VC_BU_SPORT_PRSNT 1;
BA_ "FlexKomSigStartValue" SG_ 1006 VC_BU_SPORT_PRSNT "0370FF037FFF0000h";
BA_ "FlexKomSigStartPos" SG_ 1006 VC_BU_SPORT_PRSNT 7;
BA_ "FlexKomSigName" SG_ 1006 VC_BU_SPORT_PRSNT "VehCfgBu3_Pkt";
BA_ "FlexKomSigLaenge" SG_ 1006 VC_BU_SPORT_PRSNT 64;
BA_ "FlexKomSID" SG_ 1006 VC_BU_SPORT_PRSNT 921;
BA_ "FlexKomIsMotorola" SG_ 1006 VC_BU_SPORT_PRSNT 1;
BA_ "FlexKomComment" SG_ 1006 VC_BU_SPORT_PRSNT "Vehicle Configuration Backup 3 Packet";
BA_ "GenSigSNA" SG_ 1006 VC_BU_SRT_PRSNT "0h";
BA_ "GenSigSendType" SG_ 1006 VC_BU_SRT_PRSNT 1;
BA_ "FlexKomSigStartValue" SG_ 1006 VC_BU_SRT_PRSNT "0370FF037FFF0000h";
BA_ "FlexKomSigStartPos" SG_ 1006 VC_BU_SRT_PRSNT 7;
BA_ "FlexKomSigName" SG_ 1006 VC_BU_SRT_PRSNT "VehCfgBu3_Pkt";
BA_ "FlexKomSigLaenge" SG_ 1006 VC_BU_SRT_PRSNT 64;
BA_ "FlexKomSID" SG_ 1006 VC_BU_SRT_PRSNT 921;
BA_ "FlexKomIsMotorola" SG_ 1006 VC_BU_SRT_PRSNT 1;
BA_ "FlexKomComment" SG_ 1006 VC_BU_SRT_PRSNT "Vehicle Configuration Backup 3 Packet";
BA_ "GenSigSNA" SG_ 1006 VC_BU_SecLkPrsnt "0h";
BA_ "GenSigSendType" SG_ 1006 VC_BU_SecLkPrsnt 1;
BA_ "FlexKomSigStartValue" SG_ 1006 VC_BU_SecLkPrsnt "0370FF037FFF0000h";
BA_ "FlexKomSigStartPos" SG_ 1006 VC_BU_SecLkPrsnt 7;
BA_ "FlexKomSigName" SG_ 1006 VC_BU_SecLkPrsnt "VehCfgBu3_Pkt";
BA_ "FlexKomSigLaenge" SG_ 1006 VC_BU_SecLkPrsnt 64;
BA_ "FlexKomSID" SG_ 1006 VC_BU_SecLkPrsnt 921;
BA_ "FlexKomIsMotorola" SG_ 1006 VC_BU_SecLkPrsnt 1;
BA_ "FlexKomComment" SG_ 1006 VC_BU_SecLkPrsnt "Vehicle Configuration Backup 3 Packet";
BA_ "GenSigSNA" SG_ 1006 VC_BU_SunShade_Present "0h";
BA_ "GenSigSendType" SG_ 1006 VC_BU_SunShade_Present 1;
BA_ "FlexKomSigStartValue" SG_ 1006 VC_BU_SunShade_Present "0370FF037FFF0000h";
BA_ "FlexKomSigStartPos" SG_ 1006 VC_BU_SunShade_Present 7;
BA_ "FlexKomSigName" SG_ 1006 VC_BU_SunShade_Present "VehCfgBu3_Pkt";
BA_ "FlexKomSigLaenge" SG_ 1006 VC_BU_SunShade_Present 64;
BA_ "FlexKomSID" SG_ 1006 VC_BU_SunShade_Present 921;
BA_ "FlexKomIsMotorola" SG_ 1006 VC_BU_SunShade_Present 1;
BA_ "FlexKomComment" SG_ 1006 VC_BU_SunShade_Present "Vehicle Configuration Backup 3 Packet";
BA_ "GenSigSNA" SG_ 1006 VC_BU_TEMP_DISP "0h";
BA_ "GenSigSendType" SG_ 1006 VC_BU_TEMP_DISP 1;
BA_ "FlexKomSigStartValue" SG_ 1006 VC_BU_TEMP_DISP "0370FF037FFF0000h";
BA_ "FlexKomSigStartPos" SG_ 1006 VC_BU_TEMP_DISP 7;
BA_ "FlexKomSigName" SG_ 1006 VC_BU_TEMP_DISP "VehCfgBu3_Pkt";
BA_ "FlexKomSigLaenge" SG_ 1006 VC_BU_TEMP_DISP 64;
BA_ "FlexKomSID" SG_ 1006 VC_BU_TEMP_DISP 921;
BA_ "FlexKomIsMotorola" SG_ 1006 VC_BU_TEMP_DISP 1;
BA_ "FlexKomComment" SG_ 1006 VC_BU_TEMP_DISP "Vehicle Configuration Backup 3 Packet";
BA_ "GenSigSNA" SG_ 1006 VC_BU_TcaseTyp "0h";
BA_ "GenSigSendType" SG_ 1006 VC_BU_TcaseTyp 1;
BA_ "FlexKomSigStartValue" SG_ 1006 VC_BU_TcaseTyp "0370FF037FFF0000h";
BA_ "FlexKomSigStartPos" SG_ 1006 VC_BU_TcaseTyp 7;
BA_ "FlexKomSigName" SG_ 1006 VC_BU_TcaseTyp "VehCfgBu3_Pkt";
BA_ "FlexKomSigLaenge" SG_ 1006 VC_BU_TcaseTyp 64;
BA_ "FlexKomSID" SG_ 1006 VC_BU_TcaseTyp 921;
BA_ "FlexKomIsMotorola" SG_ 1006 VC_BU_TcaseTyp 1;
BA_ "FlexKomComment" SG_ 1006 VC_BU_TcaseTyp "Vehicle Configuration Backup 3 Packet";
BA_ "GenSigStartValue" SG_ 1006 VC_BU_VEH_BRAND 15;
BA_ "GenSigSNA" SG_ 1006 VC_BU_VEH_BRAND "Fh";
BA_ "GenSigSendType" SG_ 1006 VC_BU_VEH_BRAND 1;
BA_ "FlexKomSigStartValue" SG_ 1006 VC_BU_VEH_BRAND "0370FF037FFF0000h";
BA_ "FlexKomSigStartPos" SG_ 1006 VC_BU_VEH_BRAND 7;
BA_ "FlexKomSigName" SG_ 1006 VC_BU_VEH_BRAND "VehCfgBu3_Pkt";
BA_ "FlexKomSigLaenge" SG_ 1006 VC_BU_VEH_BRAND 64;
BA_ "FlexKomSID" SG_ 1006 VC_BU_VEH_BRAND 921;
BA_ "FlexKomIsMotorola" SG_ 1006 VC_BU_VEH_BRAND 1;
BA_ "FlexKomComment" SG_ 1006 VC_BU_VEH_BRAND "Vehicle Configuration Backup 3 Packet";
BA_ "GenSigStartValue" SG_ 1006 VC_BU_VehCfg3_Stat 3;
BA_ "GenSigSNA" SG_ 1006 VC_BU_VehCfg3_Stat "3h";
BA_ "GenSigSendType" SG_ 1006 VC_BU_VehCfg3_Stat 1;
BA_ "FlexKomSigStartValue" SG_ 1006 VC_BU_VehCfg3_Stat "0370FF037FFF0000h";
BA_ "FlexKomSigStartPos" SG_ 1006 VC_BU_VehCfg3_Stat 7;
BA_ "FlexKomSigName" SG_ 1006 VC_BU_VehCfg3_Stat "VehCfgBu3_Pkt";
BA_ "FlexKomSigLaenge" SG_ 1006 VC_BU_VehCfg3_Stat 64;
BA_ "FlexKomSID" SG_ 1006 VC_BU_VehCfg3_Stat 921;
BA_ "FlexKomIsMotorola" SG_ 1006 VC_BU_VehCfg3_Stat 1;
BA_ "FlexKomComment" SG_ 1006 VC_BU_VehCfg3_Stat "Vehicle Configuration Backup 3 Packet";
BA_ "GenSigStartValue" SG_ 1006 VC_BU_WHL_BASE 3;
BA_ "GenSigSNA" SG_ 1006 VC_BU_WHL_BASE "3h";
BA_ "GenSigSendType" SG_ 1006 VC_BU_WHL_BASE 1;
BA_ "FlexKomSigStartValue" SG_ 1006 VC_BU_WHL_BASE "0370FF037FFF0000h";
BA_ "FlexKomSigStartPos" SG_ 1006 VC_BU_WHL_BASE 7;
BA_ "FlexKomSigName" SG_ 1006 VC_BU_WHL_BASE "VehCfgBu3_Pkt";
BA_ "FlexKomSigLaenge" SG_ 1006 VC_BU_WHL_BASE 64;
BA_ "FlexKomSID" SG_ 1006 VC_BU_WHL_BASE 921;
BA_ "FlexKomIsMotorola" SG_ 1006 VC_BU_WHL_BASE 1;
BA_ "FlexKomComment" SG_ 1006 VC_BU_WHL_BASE "Vehicle Configuration Backup 3 Packet";
BA_ "GenSigStartValue" SG_ 1006 VC_BU_WIN_EXPR_FEAT 3;
BA_ "GenSigSNA" SG_ 1006 VC_BU_WIN_EXPR_FEAT "3h";
BA_ "GenSigSendType" SG_ 1006 VC_BU_WIN_EXPR_FEAT 1;
BA_ "FlexKomSigStartValue" SG_ 1006 VC_BU_WIN_EXPR_FEAT "0370FF037FFF0000h";
BA_ "FlexKomSigStartPos" SG_ 1006 VC_BU_WIN_EXPR_FEAT 7;
BA_ "FlexKomSigName" SG_ 1006 VC_BU_WIN_EXPR_FEAT "VehCfgBu3_Pkt";
BA_ "FlexKomSigLaenge" SG_ 1006 VC_BU_WIN_EXPR_FEAT 64;
BA_ "FlexKomSID" SG_ 1006 VC_BU_WIN_EXPR_FEAT 921;
BA_ "FlexKomIsMotorola" SG_ 1006 VC_BU_WIN_EXPR_FEAT 1;
BA_ "FlexKomComment" SG_ 1006 VC_BU_WIN_EXPR_FEAT "Vehicle Configuration Backup 3 Packet";
BA_ "GenSigStartValue" SG_ 1007 VC_BU_AXLE_RATIO 65535;
BA_ "GenSigSNA" SG_ 1007 VC_BU_AXLE_RATIO "FFFFh";
BA_ "GenSigSendType" SG_ 1007 VC_BU_AXLE_RATIO 1;
BA_ "FlexKomSigStartValue" SG_ 1007 VC_BU_AXLE_RATIO "FFFFFFFFFFFFFFFFh";
BA_ "FlexKomSigStartPos" SG_ 1007 VC_BU_AXLE_RATIO 7;
BA_ "FlexKomSigName" SG_ 1007 VC_BU_AXLE_RATIO "VehCfgBu4_Pkt";
BA_ "FlexKomSigLaenge" SG_ 1007 VC_BU_AXLE_RATIO 64;
BA_ "FlexKomSID" SG_ 1007 VC_BU_AXLE_RATIO 1036;
BA_ "FlexKomIsMotorola" SG_ 1007 VC_BU_AXLE_RATIO 1;
BA_ "FlexKomComment" SG_ 1007 VC_BU_AXLE_RATIO "Vehicle Configuration Backup 4 Packet";
BA_ "GenSigStartValue" SG_ 1007 VC_BU_TCASE_HI_RATIO 16383;
BA_ "GenSigSNA" SG_ 1007 VC_BU_TCASE_HI_RATIO "3FFFh";
BA_ "GenSigSendType" SG_ 1007 VC_BU_TCASE_HI_RATIO 1;
BA_ "FlexKomSigStartValue" SG_ 1007 VC_BU_TCASE_HI_RATIO "FFFFFFFFFFFFFFFFh";
BA_ "FlexKomSigStartPos" SG_ 1007 VC_BU_TCASE_HI_RATIO 7;
BA_ "FlexKomSigName" SG_ 1007 VC_BU_TCASE_HI_RATIO "VehCfgBu4_Pkt";
BA_ "FlexKomSigLaenge" SG_ 1007 VC_BU_TCASE_HI_RATIO 64;
BA_ "FlexKomSID" SG_ 1007 VC_BU_TCASE_HI_RATIO 1036;
BA_ "FlexKomIsMotorola" SG_ 1007 VC_BU_TCASE_HI_RATIO 1;
BA_ "FlexKomComment" SG_ 1007 VC_BU_TCASE_HI_RATIO "Vehicle Configuration Backup 4 Packet";
BA_ "GenSigStartValue" SG_ 1007 VC_BU_TCASE_LO_RATIO 65535;
BA_ "GenSigSNA" SG_ 1007 VC_BU_TCASE_LO_RATIO "FFFFh";
BA_ "GenSigSendType" SG_ 1007 VC_BU_TCASE_LO_RATIO 1;
BA_ "FlexKomSigStartValue" SG_ 1007 VC_BU_TCASE_LO_RATIO "FFFFFFFFFFFFFFFFh";
BA_ "FlexKomSigStartPos" SG_ 1007 VC_BU_TCASE_LO_RATIO 7;
BA_ "FlexKomSigName" SG_ 1007 VC_BU_TCASE_LO_RATIO "VehCfgBu4_Pkt";
BA_ "FlexKomSigLaenge" SG_ 1007 VC_BU_TCASE_LO_RATIO 64;
BA_ "FlexKomSID" SG_ 1007 VC_BU_TCASE_LO_RATIO 1036;
BA_ "FlexKomIsMotorola" SG_ 1007 VC_BU_TCASE_LO_RATIO 1;
BA_ "FlexKomComment" SG_ 1007 VC_BU_TCASE_LO_RATIO "Vehicle Configuration Backup 4 Packet";
BA_ "GenSigStartValue" SG_ 1007 VC_BU_TIRE_CIRCUMF 65535;
BA_ "GenSigSNA" SG_ 1007 VC_BU_TIRE_CIRCUMF "FFFFh";
BA_ "GenSigSendType" SG_ 1007 VC_BU_TIRE_CIRCUMF 1;
BA_ "FlexKomSigStartValue" SG_ 1007 VC_BU_TIRE_CIRCUMF "FFFFFFFFFFFFFFFFh";
BA_ "FlexKomSigStartPos" SG_ 1007 VC_BU_TIRE_CIRCUMF 7;
BA_ "FlexKomSigName" SG_ 1007 VC_BU_TIRE_CIRCUMF "VehCfgBu4_Pkt";
BA_ "FlexKomSigLaenge" SG_ 1007 VC_BU_TIRE_CIRCUMF 64;
BA_ "FlexKomSID" SG_ 1007 VC_BU_TIRE_CIRCUMF 1036;
BA_ "FlexKomIsMotorola" SG_ 1007 VC_BU_TIRE_CIRCUMF 1;
BA_ "FlexKomComment" SG_ 1007 VC_BU_TIRE_CIRCUMF "Vehicle Configuration Backup 4 Packet";
BA_ "GenSigStartValue" SG_ 1007 VC_BU_VehCfg4_Stat 3;
BA_ "GenSigSNA" SG_ 1007 VC_BU_VehCfg4_Stat "3h";
BA_ "GenSigSendType" SG_ 1007 VC_BU_VehCfg4_Stat 1;
BA_ "FlexKomSigStartValue" SG_ 1007 VC_BU_VehCfg4_Stat "FFFFFFFFFFFFFFFFh";
BA_ "FlexKomSigStartPos" SG_ 1007 VC_BU_VehCfg4_Stat 7;
BA_ "FlexKomSigName" SG_ 1007 VC_BU_VehCfg4_Stat "VehCfgBu4_Pkt";
BA_ "FlexKomSigLaenge" SG_ 1007 VC_BU_VehCfg4_Stat 64;
BA_ "FlexKomSID" SG_ 1007 VC_BU_VehCfg4_Stat 1036;
BA_ "FlexKomIsMotorola" SG_ 1007 VC_BU_VehCfg4_Stat 1;
BA_ "FlexKomComment" SG_ 1007 VC_BU_VehCfg4_Stat "Vehicle Configuration Backup 4 Packet";
VAL_ 1002 VC_ChassisType 127 "SNA" ;
VAL_ 1002 VC_FUEL_CAP 255 "SNA" ;
VAL_ 1002 VC_HVAC_Config 0 "1_ZN_MTC" 1 "1_ZN_MTC_p_RR" 2 "1_ZN_ATC" 3 "2_ZN_MTC" 4 "2_ZN_ATC" 5 "2_ZN_ATC_p_RR" 6 "2_ZN_MTC_p_RR" 15 "SNA" ;
VAL_ 1002 VC_Liftgate_Trunk 0 "TRUNK" 1 "PLG" 2 "MANUAL_LG" 3 "SNA" ;
VAL_ 1002 VC_TcaseTyp 0 "NOT_PRSNT" 1 "TCASE_143_144" 2 "BW4445_46_48_WS" 3 "Tcase_253_1522" 4 "Tcase_BW4444" 5 "Tcase_BW4446" 6 "Tcase_MPT3025C" 7 "Tcase_241_MPT1222C" 8 "BW4447_WOS" 9 "Tcase_243" 10 "BW4447_49_WS" 11 "Tcase_273" 12 "Tcase_MAS_ATC" 13 "Tcase_BW4440" 14 "Tcase_156" 15 "Tcase_256_3022" ;
VAL_ 1002 VC_VEH_BRAND 1 "CHRYSLER" 2 "DODGE" 3 "JEEP" 4 "MERCEDES_BENZ" 5 "MITSUBISHI" 6 "VOLKSWAGEN" 7 "FREIGHTLINER" 8 "ALPHA" 9 "FIAT" 10 "LANCIA" 11 "MASERATI" 12 "RAM" 15 "SNA" ;
VAL_ 1002 VC_VehCfg3_Stat 0 "NA" 1 "PROGAMMED" 2 "REQUEST_DATA" 3 "SNA" ;
VAL_ 1002 VC_WHL_BASE 0 "SHORT" 1 "LONG" 2 "XLONG" 3 "SNA" ;
VAL_ 1002 VC_WIN_EXPR_FEAT 0 "WIN_EXPR_DRV" 1 "WIN_EXPR_FT" 2 "WIN_EXPR_ALL" 3 "WIN_EXPR_NN" ;
VAL_ 1003 VC_AXLE_RATIO 65535 "SNA" ;
VAL_ 1003 VC_TCASE_HI_RATIO 16383 "SNA" ;
VAL_ 1003 VC_TCASE_LO_RATIO 65535 "SNA" ;
VAL_ 1003 VC_TIRE_CIRCUMF 65535 "SNA" ;
VAL_ 1003 VC_VehCfg4_Stat 0 "NA" 1 "PROGAMMED" 2 "REQUEST_DATA" 3 "SNA" ;
VAL_ 1098 VC_AmbTempLct 0 "CBC" 1 "DCM" 3 "SNA" ;
VAL_ 1098 VC_Strng_Rt_0 255 "SNA" ;
VAL_ 1098 VC_Strng_Rt_pls1 255 "SNA" ;
VAL_ 1098 VC_Strng_Rt_pls2 255 "SNA" ;
VAL_ 1098 VC_Strng_Rt_pls3 255 "SNA" ;
VAL_ 1098 VC_Strng_Rt_pls4 255 "SNA" ;
VAL_ 1098 VC_Strng_Rt_pls5 255 "SNA" ;
VAL_ 1098 VC_VehCfg5_Stat 0 "NA" 1 "PROGAMMED" 2 "REQUEST_DATA" 3 "SNA" ;
VAL_ 1100 VC_AnlgDrSnsr 0 "NONE" 1 "DRV" 2 "FT" 3 "ALL" ;
VAL_ 1100 VC_BrkTyp 0 "SMALL" 1 "PB" 2 "CB" 3 "MB" 7 "SNA" ;
VAL_ 1100 VC_Strng_Rt_Mns1 255 "SNA" ;
VAL_ 1100 VC_Strng_Rt_Mns2 255 "SNA" ;
VAL_ 1100 VC_Strng_Rt_Mns3 255 "SNA" ;
VAL_ 1100 VC_Strng_Rt_Mns4 255 "SNA" ;
VAL_ 1100 VC_Strng_Rt_Mns5 255 "SNA" ;
VAL_ 1100 VC_TireCircumfFT 65535 "SNA" ;
VAL_ 1100 VC_VehCfg6_Stat 0 "NA" 1 "PROGAMMED" 2 "REQUEST_DATA" 3 "SNA" ;
VAL_ 897 VC_ACC_Type 0 "NONE" 1 "ACC" 2 "STOP" 3 "GO" ;
VAL_ 897 VC_AGSprsnt 0 "Not_Present" 1 "Present" ;
VAL_ 897 VC_AS_ERS 0 "NONE" 1 "ERS" 2 "AS" 3 "SNA" ;
VAL_ 897 VC_AxleLockerPrsnt 0 "NONE" 1 "REAR" 2 "FTRR" ;
VAL_ 897 VC_Brake_Type 0 "None" 1 "1" 2 "2" 3 "3" 4 "4" 5 "5" 6 "6" 7 "7" 8 "8" 9 "9" 10 "10" 11 "11" 12 "12" 13 "13" 14 "14" 15 "15" ;
VAL_ 897 VC_GlareFree_Prsnt 0 "Not_Present" 1 "Present" ;
VAL_ 897 VC_HybridType 0 "NONE" 1 "BEV" 2 "HEV" 3 "PHEV" 4 "BSG48" ;
VAL_ 897 VC_MOC_Type 0 "NO_MOC" 1 "MOC_BREMBO" 2 "MOC_CONTI" ;
VAL_ 897 VC_PBTyp 0 "MECH" 1 "EPB_MOC" 2 "EPB_CP" 3 "IMOC" 4 "ICP" 7 "SNA" ;
VAL_ 897 VC_Suspension_Type 0 "None" 1 "1" 2 "2" 3 "3" 4 "4" 5 "5" 6 "6" 7 "7" 8 "8" 9 "9" 10 "10" 11 "11" 12 "12" 13 "13" 14 "14" 15 "15" ;
VAL_ 897 VC_TPMS_Configuration 0 "NHTSA" 1 "NAFTA" 2 "ECE" 3 "OTHER" 4 "CHINA" 7 "SNA" ;
VAL_ 897 VC_Temp_Display_Resolution 0 "One_Degree_C" 1 "Half_Degree_C" ;
VAL_ 897 VC_TransType 0 "NP" 1 "SI_EVT_Hybrid_Trans" 2 "MTA" 3 "c40TES" 4 "Aisin_LD" 5 "W5A580" 6 "c62TE" 7 "c65RFE" 8 "c66RFE" 9 "c68RFE" 10 "AISIN_HD" 11 "DDCT_C635" 12 "HPT_6F24" 13 "ZF_8Spd" 14 "ZF_9Spd" 63 "SNA" ;
VAL_ 897 VC_VehCfg7_Stat 0 "NA" 1 "PROGAMMED" 2 "REQUEST_DATA" 3 "SNA" ;
VAL_ 906 VC_AVAC_PRSNT 0 "Not_Present" 1 "Present" ;
VAL_ 906 VC_BEAM_SHAPING_PRSNT 0 "Not_Present" 1 "Present" ;
VAL_ 906 VC_DBL_PRSNT 0 "Not_Present" 1 "Present" ;
VAL_ 906 VC_FADPrsnt 0 "Not_Present" 1 "Present" ;
VAL_ 906 VC_Increasing_Speed_Constant 0 "Increasing_0" 1 "Increasing_1" 2 "Increasing_2" 3 "Increasing_3" 4 "Increasing_4" 5 "Increasing_5" 6 "Increasing_6" 7 "Increasing_7" ;
VAL_ 906 VC_PEB_PRSNT 0 "Not_Present" 1 "Present" ;
VAL_ 906 VC_PPPAHardBtn 0 "Not_Present" 1 "Present" ;
VAL_ 906 VC_Power_Outlet_Type 0 "No_Inverter" 1 "230V_Auxiliary_Power_Outlet" 2 "115V_Auxiliary_Power_Outlet" 3 "Reserved" ;
VAL_ 906 VC_SBL_FBL_CORNERING_PRSNT 0 "Not_Present" 1 "SBL_FBL_Present" 2 "Cornering_Present" ;
VAL_ 906 VC_Speedometer_Tolerance 0 "Tolerance_0" 1 "Tolerance_1" 2 "Tolerance_2" 3 "Tolerance_3" 4 "Tolerance_4" 5 "Tolerance_5" 6 "Tolerance_6" 7 "Tolerance_7" 8 "Tolerance_8" 9 "Tolerance_9" 10 "Tolerance_10" 11 "Tolerance_Neg1" 12 "Tolerance_Neg2" 13 "Tolerance_Neg3" 14 "Tolerance_Neg4" 15 "Tolerance_Neg5" ;
VAL_ 906 VC_Steering_Cfactor 0 "TYPE_1" 1 "TYPE_2" 2 "TYPE_3" 3 "TYPE_4" ;
VAL_ 906 VC_TACHO_TYPE 0 "DISABLED" 1 "TYP_1" 2 "TYP_2" 3 "TYP_3" ;
VAL_ 906 VC_VP_Level 0 "None" 1 "LTM" 2 "ETM" ;
VAL_ 906 VC_VehCfg8_Stat 0 "NA" 1 "PROGAMMED" 2 "REQUEST_DATA" 3 "SNA" ;
VAL_ 906 VC_WHL_BASE_LENGTH 0 "Not_Used" 1 "Length_1" 2 "Length_2" 3 "Length_3" 4 "Length_4" 5 "Length_5" 6 "Length_6" 7 "Length_7" 8 "Length_8" 9 "Length_9" 10 "Length_10" 11 "Length_11" 12 "Length_12" 13 "Length_13" 14 "Length_14" 15 "Length_15" ;
VAL_ 1004 VC_BU_BODY_STYLE 0 "BODY_NONE" 1 "BODY_4DS" 2 "BODY_2DS" 3 "BODY_CONV" 4 "BODY_WAGON" 5 "BODY_4DH" 6 "BODY_2DP" 7 "BODY_4DP" 8 "BODY_4DMP" 15 "BODY_SNA" ;
VAL_ 1004 VC_BU_COUNTRY 0 "ROW" 2 "USA" 3 "EU" 4 "CND" 5 "GB" 6 "JPN" 7 "GER" 8 "SWISS" 9 "MLY" 10 "AUS" 11 "IND" 12 "GULF" 13 "VEN" 14 "MEX" 15 "BRZ" 16 "CHINA" 17 "EGYPT" 20 "S_KOR" 21 "ECE" 31 "COUNTRY_SNA" ;
VAL_ 1004 VC_BU_LHD_RHD 0 "NA" 1 "LHD" 2 "RHD" 3 "SNA" ;
VAL_ 1004 VC_BU_MAX_VEH_SPD 255 "SNA" ;
VAL_ 1004 VC_BU_MODEL_YEAR 63 "SNA" ;
VAL_ 1004 VC_BU_PTS_Config 0 "REAR" 1 "FRT_REAR" 3 "SEMI" ;
VAL_ 1004 VC_BU_PTS_DispTyp 0 "HEAD_DISP" 1 "CCN_DISP" 2 "AUDIO_DISP" 7 "SNA" ;
VAL_ 1004 VC_BU_RemStPrsnt 0 "SNA" ;
VAL_ 1004 VC_BU_ShftrTyp 0 "TYPE_NA" 1 "TYPE_ERS4" 2 "TYPE_AS4" 3 "TYPE_ERS5" 4 "TYPE_AS5" 5 "TYPE_RS5M" 6 "TYPE_RS5S" 7 "TYPE_RS5L" 8 "TYPE_ERS4ESW" 9 "TYPE_MS7D" 10 "TYPE_MS7M156" 11 "TYPE_RS4" 12 "TYPE_MS7S" 13 "TYPE_MS7" 14 "TYPE_PS5" 15 "SNA" ;
VAL_ 1004 VC_BU_SpecialPKG 0 "NONE" 255 "SNA" ;
VAL_ 1004 VC_BU_VEH_LINE 0 "VEH_NONE" 1 "VEH_WK" 2 "VEH_LX" 22 "VEH_JC" 29 "VEH_DS" 31 "VEH_D2" 32 "VEH_DD" 33 "VEH_DP" 34 "VEH_DJ" 35 "VEH_WD" 39 "VEH_DX" 41 "VEH_LD" 42 "VEH_M156" 43 "VEH_ZD" 44 "VEH_LA" 45 "VEH_RU" 46 "VEH_M161" 47 "VEH_WS" 48 "VEH_DF" 49 "VEH_JL" 50 "VEH_M157" 51 "VEH_RA" 52 "VEH_WL" 53 "VEH_DT" 54 "VEH_DU" 55 "VEH_JT" 80 "VEH_PF" 81 "VEH_KL" 82 "VEH_UF" 83 "VEH_UT" 84 "VEH_M145" 85 "VEH_M145BD" 86 "VEH_K8" 87 "VEH_FF" 255 "SNA" ;
VAL_ 1004 VC_BU_VehCfg1_Stat 0 "NA" 1 "PROGAMMED" 2 "NA1" 3 "SNA" ;
VAL_ 1004 VC_BU_XWD 0 "2FT" 1 "2RR" 2 "ALLWD" 3 "4WD" ;
VAL_ 1005 VC_BU_LgtLdPressFtTr 255 "SNA" ;
VAL_ 1005 VC_BU_LgtLdPressRrTr 255 "SNA" ;
VAL_ 1005 VC_BU_MaseratiMd 0 "NORMAL" 1 "GTS" 2 "RACE" 3 "SNA" ;
VAL_ 1005 VC_BU_MaxLdPressFtTr 255 "SNA" ;
VAL_ 1005 VC_BU_MaxLdPressRrTr 255 "SNA" ;
VAL_ 1005 VC_BU_PwrIvtrTyp 0 "NoPwrIvtr" 1 "MtrySw" 2 "LchSw" ;
VAL_ 1005 VC_BU_ShftInd_Prsnt 0 "NONE" 1 "GSI" 2 "PSI" 3 "PGSI" ;
VAL_ 1005 VC_BU_SpecialPKG_IC 0 "NONE" 1 "PKG_70JP" 2 "PKG_300S" 3 "PKG_BEATS" 4 "PKG_SUPERBEE" 5 "MOPAR" 6 "Hellcat" 7 "Shaker" 8 "Scat" 9 "ADR" 10 "Scat_Drag" 11 "High_Output" 12 "Hellcat_HO" 16 "LARAMIE" 17 "BIGHORN" 18 "LONGHORN" 19 "LONESTAR" 20 "LIMITED" 21 "MOSSY_OAK" 22 "ORT" 23 "POWERWAGON" 24 "HD_DX" 25 "SPORT" 26 "PWGN_Laramie" 27 "RAM_1500" 28 "PWGN_GOODYEAR" 29 "LONGHORN_BLACK" 30 "LONGHORN_BROWN" 31 "RAM_2500" 32 "RAM_3500" 33 "RAM_4500" 34 "RAM_5500" 35 "RAM_TRX21" 36 "VOYAGER" 37 "PACIFICA" 38 "GRAND_CARAVAN" 39 "50th_Anniversary" 100 "WRANGLER_SPORT" 101 "WRANGLER_SAHARA" 102 "WRANGLER_RUBICON" 103 "JEEP_SPORT" 104 "JEEP_SPORT_X" 105 "JEEP_RUBICON" 106 "JEEP_PRO_FIGHTER" 150 "TRAILHAWK_SUPERCHARGED" 246 "DODGE_100" 247 "VARVATOS" 255 "SNA" ;
VAL_ 1005 VC_BU_VehCfg2_Stat 0 "NA" 1 "PROGAMMED" 2 "NA1" 3 "SNA" ;
VAL_ 1006 VC_BU_ChassisType 127 "SNA" ;
VAL_ 1006 VC_BU_ELV_PRSNT 0 "SNA" ;
VAL_ 1006 VC_BU_FUEL_CAP 255 "SNA" ;
VAL_ 1006 VC_BU_HVAC_Config 0 "1_ZN_MTC" 1 "1_ZN_MTC_p_RR" 2 "1_ZN_ATC" 3 "2_ZN_MTC" 4 "2_ZN_ATC" 5 "2_ZN_ATC_p_RR" 6 "2_ZN_MTC_p_RR" 15 "SNA" ;
VAL_ 1006 VC_BU_Liftgate_Trunk 0 "TRUNK" 1 "PLG" 2 "MANUAL_LG" 3 "SNA" ;
VAL_ 1006 VC_BU_TcaseTyp 0 "NOT_PRSNT" 1 "TCASE_143_144" 2 "BW4445_46_48_WS" 3 "Tcase_253_1522" 4 "Tcase_BW4444" 5 "Tcase_BW4446" 6 "Tcase_MPT3025C" 7 "Tcase_241_MPT1222C" 8 "BW4447_WOS" 9 "Tcase_243" 10 "BW4447_49_WS" 11 "Tcase_273" 12 "Tcase_MAS_ATC" 13 "Tcase_BW4440" 14 "Tcase_156" 15 "Tcase_256_3022" ;
VAL_ 1006 VC_BU_VEH_BRAND 1 "CHRYSLER" 2 "DODGE" 3 "JEEP" 4 "MERCEDES_BENZ" 5 "MITSUBISHI" 6 "VOLKSWAGEN" 7 "FREIGHTLINER" 8 "ALPHA" 9 "FIAT" 10 "LANCIA" 11 "MASERATI" 12 "RAM" 15 "SNA" ;
VAL_ 1006 VC_BU_VehCfg3_Stat 0 "NA" 1 "PROGAMMED" 2 "NA1" 3 "SNA" ;
VAL_ 1006 VC_BU_WHL_BASE 0 "SHORT" 1 "LONG" 2 "XLONG" 3 "SNA" ;
VAL_ 1006 VC_BU_WIN_EXPR_FEAT 0 "WIN_EXPR_DRV" 1 "WIN_EXPR_FT" 2 "WIN_EXPR_ALL" 3 "WIN_EXPR_NN" ;
VAL_ 1007 VC_BU_AXLE_RATIO 65535 "SNA" ;
VAL_ 1007 VC_BU_TCASE_HI_RATIO 16383 "SNA" ;
VAL_ 1007 VC_BU_TCASE_LO_RATIO 65535 "SNA" ;
VAL_ 1007 VC_BU_TIRE_CIRCUMF 65535 "SNA" ;
VAL_ 1007 VC_BU_VehCfg4_Stat 0 "NA" 1 "PROGAMMED" 2 "NA1" 3 "SNA" ;
